VERSION "dbc-export 1 2025.20.8"

NS_ :

BS_:

BU_: ADSP APB APP APS APSB BB BMS CC CMP CMPD CP DAS DI DIF DIR DPB EPAS3P EPAS3S EPASTP EPASTS EPBL EPBR ESP GTW HVP IBST ICR IDB OCS1P ODIN PARK PCS PLG PM PMF PMR PTC RADC RCM RCM2 RCU SCCM SDCR TAS TCU TPMS TRCM UDS UI UIS UMC USM VC VCFRONT VCLEFT VCRIGHT VCSEC

BO_ 294 UI_alertMatrix4: 8 UI
 SG_ UI_a193_TcuRNandFwVersionMismatc : 0|1@1+ (1,0) [0|1] "" Vector__XXX
 SG_ UI_a194_AudioweaverRestarted : 1|1@1+ (1,0) [0|1] "" Vector__XXX
 SG_ UI_a195_gtwMfdUdpApiFired : 2|1@1+ (1,0) [0|1] "" Vector__XXX
 SG_ UI_a196_AMDI2C3BusInoperable : 3|1@1+ (1,0) [0|1] "" Vector__XXX
 SG_ UI_a197_AMDI2C1BusInoperable : 4|1@1+ (1,0) [0|1] "" Vector__XXX
 SG_ UI_a198_IncompatibleBTUSBHubHard : 5|1@1+ (1,0) [0|1] "" Vector__XXX
 SG_ UI_a199_HighAPedalDetectedAtColl : 6|1@1+ (1,0) [0|1] "" Vector__XXX
 SG_ UI_a200_UIFirmwareVersionMismatc : 7|1@1+ (1,0) [0|1] "" Vector__XXX
 SG_ UI_a201_rearDisplayDisconnected : 8|1@1+ (1,0) [0|1] "" Vector__XXX
 SG_ UI_a202_sysMemoryIncorrect : 9|1@1+ (1,0) [0|1] "" Vector__XXX
 SG_ UI_a204_ModemSleepFailure : 11|1@1+ (1,0) [0|1] "" Vector__XXX
 SG_ UI_a205_ModemSleepSignalMismatch : 12|1@1+ (1,0) [0|1] "" Vector__XXX
 SG_ UI_a206_ModemMIAAfterWake : 13|1@1+ (1,0) [0|1] "" Vector__XXX
 SG_ UI_a207_mqttClientDisconnected : 14|1@1+ (1,0) [0|1] "" Vector__XXX
 SG_ UI_a208_mqttDisconnectReason : 15|1@1+ (1,0) [0|1] "" Vector__XXX
 SG_ UI_a209_dataCallDisconnected : 16|1@1+ (1,0) [0|1] "" Vector__XXX
 SG_ UI_a210_CellularCSRegFail : 17|1@1+ (1,0) [0|1] "" Vector__XXX
 SG_ UI_a211_AEBSDisabled : 18|1@1+ (1,0) [0|1] "" Vector__XXX
 SG_ UI_a212_AEBSFaulted : 19|1@1+ (1,0) [0|1] "" Vector__XXX
 SG_ UI_a213_ISADisabled : 20|1@1+ (1,0) [0|1] "" Vector__XXX
 SG_ UI_a214_pmHelperFailure : 21|1@1+ (1,0) [0|1] "" Vector__XXX
 SG_ UI_a215_compositorStallDetected : 22|1@1+ (1,0) [0|1] "" Vector__XXX
 SG_ UI_a216_AudioA2bCircuitProblem : 23|1@1+ (1,0) [0|1] "" Vector__XXX
 SG_ UI_a217_CgroupMemoryPressure : 24|1@1+ (1,0) [0|1] "" Vector__XXX
 SG_ UI_a218_AudiodNoAudioDevices : 25|1@1+ (1,0) [0|1] "" Vector__XXX
 SG_ UI_a219_CompositorWatchdog : 26|1@1+ (1,0) [0|1] "" Vector__XXX
 SG_ UI_a220_MediaBrowseError : 27|1@1+ (1,0) [0|1] "" Vector__XXX
 SG_ UI_a221_NavigationServiceError : 28|1@1+ (1,0) [0|1] "" Vector__XXX
 SG_ UI_a222_QtCarRestart : 29|1@1+ (1,0) [0|1] "" Vector__XXX
 SG_ UI_a223_databaseError : 30|1@1+ (1,0) [0|1] "" Vector__XXX
 SG_ UI_a224_centerDisplayDisconnecte : 31|1@1+ (1,0) [0|1] "" Vector__XXX
 SG_ UI_a225_clusterDisplayDisconnect : 32|1@1+ (1,0) [0|1] "" Vector__XXX
 SG_ UI_a226_largePhoneContactSync : 33|1@1+ (1,0) [0|1] "" Vector__XXX
 SG_ UI_a228_pipewireXrunBurst : 35|1@1+ (1,0) [0|1] "" Vector__XXX
 SG_ UI_a229_SerDesError : 36|1@1+ (1,0) [0|1] "" Vector__XXX
 SG_ UI_a230_ModemSimCardMismatch : 37|1@1+ (1,0) [0|1] "" Vector__XXX
 SG_ UI_a231_SleepCancelled : 38|1@1+ (1,0) [0|1] "" Vector__XXX
 SG_ UI_a232_processExitError : 39|1@1+ (1,0) [0|1] "" Vector__XXX
 SG_ UI_a233_ModemRFFailure : 40|1@1+ (1,0) [0|1] "" Vector__XXX
 SG_ UI_a234_AMDI2C0Timeout : 41|1@1+ (1,0) [0|1] "" Vector__XXX
 SG_ UI_a235_AMDI2C1Timeout : 42|1@1+ (1,0) [0|1] "" Vector__XXX
 SG_ UI_a236_ModemOnResetState : 43|1@1+ (1,0) [0|1] "" Vector__XXX
 SG_ UI_a237_ClipUploadActive : 44|1@1+ (1,0) [0|1] "" Vector__XXX
 SG_ UI_a238_ModemConfigMismatch : 45|1@1+ (1,0) [0|1] "" Vector__XXX
 SG_ UI_a239_stateOfVehiclesFunctions : 46|1@1+ (1,0) [0|1] "" Vector__XXX
 SG_ UI_a240_ethError : 47|1@1+ (1,0) [0|1] "" Vector__XXX
 SG_ UI_a241_AxCPError : 48|1@1+ (1,0) [0|1] "" Vector__XXX

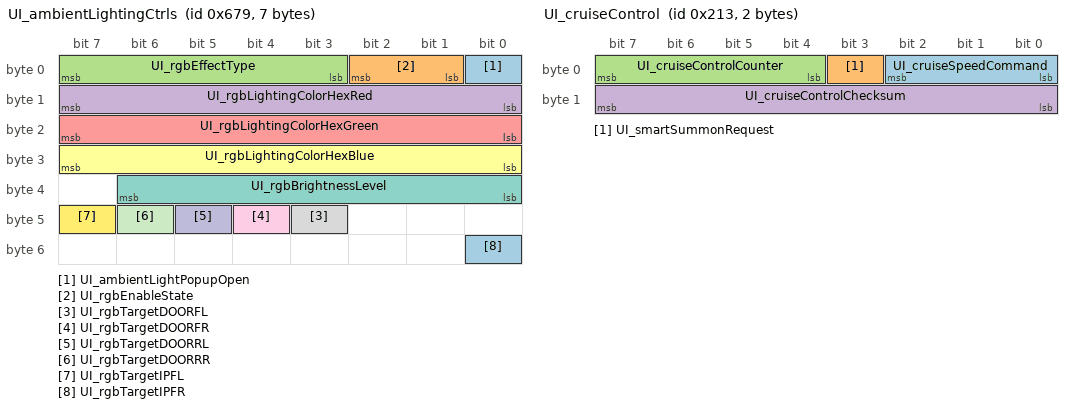
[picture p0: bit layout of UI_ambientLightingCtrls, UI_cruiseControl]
BO_ 1657 UI_ambientLightingCtrls: 7 UI
 SG_ UI_ambientLightPopupOpen : 0|1@1+ (1,0) [0|1] "" Vector__XXX
 SG_ UI_rgbEnableState : 1|2@1+ (1,0) [0|3] "" Vector__XXX
 SG_ UI_rgbEffectType : 3|5@1+ (1,0) [0|31] "" Vector__XXX
 SG_ UI_rgbLightingColorHexRed : 8|8@1+ (1,0) [0|255] "" Vector__XXX
 SG_ UI_rgbLightingColorHexGreen : 16|8@1+ (1,0) [0|255] "" Vector__XXX
 SG_ UI_rgbLightingColorHexBlue : 24|8@1+ (1,0) [0|255] "" Vector__XXX
 SG_ UI_rgbBrightnessLevel : 32|7@1+ (1,0) [0|100] "%" Vector__XXX
 SG_ UI_rgbTargetDOORFL : 43|1@1+ (1,0) [0|1] "" Vector__XXX
 SG_ UI_rgbTargetDOORFR : 44|1@1+ (1,0) [0|1] "" Vector__XXX
 SG_ UI_rgbTargetDOORRL : 45|1@1+ (1,0) [0|1] "" Vector__XXX
 SG_ UI_rgbTargetDOORRR : 46|1@1+ (1,0) [0|1] "" Vector__XXX
 SG_ UI_rgbTargetIPFL : 47|1@1+ (1,0) [0|1] "" Vector__XXX
 SG_ UI_rgbTargetIPFR : 48|1@1+ (1,0) [0|1] "" Vector__XXX

BO_ 1021 UI_autopilotControl: 8 UI
 SG_ UI_autopilotControlIndex M : 0|3@1+ (1,0) [0|7] "" Vector__XXX
 SG_ UI_hovEnabled m0 : 3|1@1+ (1,0) [0|1] "" Vector__XXX
 SG_ UI_donDisableAutoWiperDuration m0 : 4|3@1+ (1,0) [0|7] "" Vector__XXX
 SG_ UI_donDisableOnAutoWiperSpeed m0 : 7|4@1+ (1,0) [0|15] "" Vector__XXX
 SG_ UI_blindspotMinSpeed m0 : 11|4@1+ (1,0) [0|15] "" Vector__XXX
 SG_ UI_blindspotDistance m0 : 15|3@1+ (1,0) [0|7] "" Vector__XXX
 SG_ UI_blindspotTTC m0 : 18|3@1+ (1,0) [0|7] "" Vector__XXX
 SG_ UI_donStopEndOfRampBuffer m0 : 21|3@1+ (1,0) [0|7] "" Vector__XXX
 SG_ UI_donDisableCutin m0 : 24|1@1+ (1,0) [0|1] "" Vector__XXX
 SG_ UI_smartSetSpeedOffset m0 : 25|6@1+ (1,-30) [-30|33] "%" Vector__XXX
 SG_ UI_smartSetSpeedOffsetType m0 : 31|1@1+ (1,0) [0|1] "" Vector__XXX
 SG_ UI_autopilotMonarchBackup m0 : 32|1@1+ (1,0) [0|1] "" Vector__XXX
 SG_ UI_fsdVisualizationEnabled m0 : 37|1@1+ (1,0) [0|1] "" Vector__XXX
 SG_ UI_fsdStopsControlEnabled m0 : 38|1@1+ (1,0) [0|1] "" Vector__XXX
 SG_ UI_fsdContinueOnGreenWithCIPV m0 : 39|1@1+ (1,0) [0|1] "" Vector__XXX
 SG_ UI_smartSetSpeed m0 : 40|1@1+ (1,0) [0|1] "" Vector__XXX
 SG_ UI_automaticSetSpeedOffset m0 : 41|1@1+ (1,0) [0|1] "" Vector__XXX
 SG_ UI_apply2021_1958_ISA m0 : 42|1@1+ (1,0) [0|1] "" Vector__XXX
 SG_ UI_apply2021_646_ELKS m0 : 43|1@1+ (1,0) [0|1] "" Vector__XXX
 SG_ UI_apply2021_1341_DDAW m0 : 44|1@1+ (1,0) [0|1] "" Vector__XXX
 SG_ UI_homelinkNearby m0 : 45|1@1+ (1,0) [0|1] "" Vector__XXX
 SG_ UI_enableFullSelfDriving m0 : 46|1@1+ (1,0) [0|1] "" Vector__XXX
 SG_ UI_hasFullSelfDriving m0 : 47|1@1+ (1,0) [0|1] "" Vector__XXX
 SG_ UI_autosteerActivation m0 : 48|1@1+ (1,0) [0|1] "" Vector__XXX
 SG_ UI_autopilotDrivingProfile m0 : 49|2@1+ (1,0) [0|3] "" Vector__XXX
 SG_ UI_fsdBetaRequest m0 : 51|1@1+ (1,0) [0|1] "" Vector__XXX
 SG_ UI_fullSelfDrivingSuspended m0 : 52|1@1+ (1,0) [0|1] "" Vector__XXX
 SG_ UI_disableOptionalLaneChanges m0 : 53|1@1+ (1,0) [0|1] "" Vector__XXX
 SG_ UI_applyR152_AEBS m0 : 59|1@1+ (1,0) [0|1] "" Vector__XXX
 SG_ UI_autopilotControlMux0Valid m0 : 63|1@1+ (1,0) [0|1] "" Vector__XXX
 SG_ UI_selectableCameraRequest m1 : 8|4@1+ (1,0) [0|14] "" Vector__XXX
 SG_ UI_overrideSleepWithSuspend m1 : 16|1@1+ (1,0) [0|1] "" Vector__XXX
 SG_ UI_driverMonitorConfirmation m1 : 17|1@1+ (1,0) [0|1] "" Vector__XXX
 SG_ UI_parkAssistUseVision m1 : 18|1@1+ (1,0) [0|1] "" Vector__XXX
 SG_ UI_applyEceR79 m1 : 19|1@1+ (1,0) [0|1] "" Vector__XXX
 SG_ UI_enableMapStops m1 : 20|1@1+ (1,0) [0|1] "" Vector__XXX
 SG_ UI_disableMain m1 : 23|1@1+ (1,0) [0|1] "" Vector__XXX
 SG_ UI_disableNarrow m1 : 24|1@1+ (1,0) [0|1] "" Vector__XXX
 SG_ UI_disableFisheye m1 : 25|1@1+ (1,0) [0|1] "" Vector__XXX
 SG_ UI_disableLeftPillar m1 : 26|1@1+ (1,0) [0|1] "" Vector__XXX
 SG_ UI_disableRightPillar m1 : 27|1@1+ (1,0) [0|1] "" Vector__XXX
 SG_ UI_disableLeftRepeater m1 : 28|1@1+ (1,0) [0|1] "" Vector__XXX
 SG_ UI_disableRightRepeater m1 : 29|1@1+ (1,0) [0|1] "" Vector__XXX
 SG_ UI_disableBackup m1 : 30|1@1+ (1,0) [0|1] "" Vector__XXX
 SG_ UI_disableRadar m1 : 31|1@1+ (1,0) [0|1] "" Vector__XXX
 SG_ UI_noStalkConfirmAlertHaptic m1 : 32|1@1+ (1,0) [0|1] "" Vector__XXX
 SG_ UI_regulatoryLKA m1 : 33|1@1+ (1,0) [0|1] "" Vector__XXX
 SG_ UI_regulatoryLaneAssistLevel m1 : 34|1@1+ (1,0) [0|1] "" Vector__XXX
 SG_ UI_ulcSnooze m1 : 36|1@1+ (1,0) [0|1] "" Vector__XXX
 SG_ UI_noStalkConfirmAlertChime m1 : 37|1@1+ (1,0) [0|1] "" Vector__XXX
 SG_ UI_factorySummonEnable m1 : 39|1@1+ (1,0) [0|1] "" Vector__XXX
 SG_ UI_apmv3Branch m1 : 40|3@1+ (1,0) [0|7] "" Vector__XXX
 SG_ UI_enableCabinCamera m1 : 43|1@1+ (1,0) [0|1] "" Vector__XXX
 SG_ UI_enableAutopilotStopWarning m1 : 44|1@1+ (1,0) [0|1] "" Vector__XXX
 SG_ UI_showLaneGraph m1 : 45|1@1+ (1,0) [0|1] "" Vector__XXX
 SG_ UI_showTrackLabels m1 : 46|1@1+ (1,0) [0|1] "" Vector__XXX
 SG_ UI_hardCoreSummon m1 : 47|1@1+ (1,0) [0|1] "" Vector__XXX
 SG_ UI_enableCabinCameraTelemetry m1 : 48|1@1+ (1,0) [0|1] "" Vector__XXX
 SG_ UI_enableVisionSpeedControl m1 : 49|1@1+ (1,0) [0|1] "" Vector__XXX
 SG_ UI_autopilotTelemetryInChina m1 : 50|1@1+ (1,0) [0|1] "" Vector__XXX
 SG_ UI_enableTeslaAutopark m1 : 51|1@1+ (1,0) [0|1] "" Vector__XXX
 SG_ UI_autoTurnSignalMode m1 : 52|1@1+ (1,0) [0|1] "" Vector__XXX
 SG_ UI_enableCautionLightControl m1 : 54|1@1+ (1,0) [0|1] "" Vector__XXX
 SG_ UI_applyEceR79SmartSummonOnly m1 : 55|1@1+ (1,0) [0|1] "" Vector__XXX
 SG_ UI_autopilotMonarchEnabled m1 : 56|1@1+ (1,0) [0|1] "" Vector__XXX
 SG_ UI_autopilotEphemerisEnabled m1 : 57|1@1+ (1,0) [0|1] "" Vector__XXX
 SG_ UI_enableCabinAudioRecording m1 : 59|1@1+ (1,0) [0|1] "" Vector__XXX
 SG_ UI_autopilotControlMux1Valid m1 : 63|1@1+ (1,0) [0|1] "" Vector__XXX
 SG_ UI_enableApproachingEmergencyVeh m2 : 5|1@1+ (1,0) [0|1] "" Vector__XXX
 SG_ UI_enableStartFsdFromParkBrakeCo m2 : 6|1@1+ (1,0) [0|1] "" Vector__XXX
 SG_ UI_enableStartFsdFromPark m2 : 7|1@1+ (1,0) [0|1] "" Vector__XXX
 SG_ UI_fsdMaxSpeedOffsetPercentage m2 : 8|6@1+ (1,0) [0|63] "%" Vector__XXX
 SG_ UI_coldStartMonarchInFactory m2 : 16|1@1+ (1,0) [0|1] "" Vector__XXX
 SG_ UI_autopilotControlMux2Valid m2 : 63|1@1+ (1,0) [0|1] "" Vector__XXX

BO_ 819 UI_chargeRequest: 5 UI
 SG_ UI_openChargePortDoorRequest : 0|1@1+ (1,0) [0|1] "" Vector__XXX
 SG_ UI_closeChargePortDoorRequest : 1|1@1+ (1,0) [0|1] "" Vector__XXX
 SG_ UI_chargeEnableRequest : 2|1@1+ (1,0) [0|1] "" Vector__XXX
 SG_ UI_brickVLoggingRequest : 3|1@1+ (1,0) [0|1] "" Vector__XXX
 SG_ UI_brickBalancingDisabled : 4|1@1+ (1,0) [0|1] "" Vector__XXX
 SG_ UI_dSocAlertThreshold : 5|3@1+ (0.5,-4) [-4|-0.5] "%" Vector__XXX
 SG_ UI_acChargeCurrentLimit : 8|7@1+ (1,0) [0|126] "A" Vector__XXX
 SG_ UI_dSocAlertEnable : 15|1@1+ (1,0) [0|1] "" Vector__XXX
 SG_ UI_chargeTerminationPct : 16|10@1+ (0.1,0) [5|100] "%" Vector__XXX
 SG_ UI_chargeFeature1 : 26|1@1+ (1,0) [0|1] "" Vector__XXX
 SG_ UI_chargeFeature2 : 27|1@1+ (1,0) [0|1] "" Vector__XXX
 SG_ UI_chargeFeature3 : 28|1@1+ (1,0) [0|1] "" Vector__XXX
 SG_ UI_scheduledDepartureEnabled : 29|1@1+ (1,0) [0|1] "" Vector__XXX
 SG_ UI_chargePortLatchRequest : 30|2@1+ (1,0) [0|3] "" Vector__XXX
 SG_ UI_socSnapshotExpirationTime : 32|4@1+ (2,2) [2|32] "weeks" Vector__XXX
 SG_ UI_cpInletHeaterRequest : 36|2@1+ (1,0) [0|3] "" Vector__XXX
 SG_ UI_chargePowerSampleRequest : 38|1@1+ (1,0) [0|1] "" Vector__XXX
 SG_ UI_enableIso15118 : 39|1@1+ (1,0) [0|1] "" Vector__XXX

BO_ 531 UI_cruiseControl: 2 UI
 SG_ UI_cruiseSpeedCommand : 0|3@1+ (1,0) [0|7] "" Vector__XXX
 SG_ UI_smartSummonRequest : 3|1@1+ (1,0) [0|1] "" Vector__XXX
 SG_ UI_cruiseControlCounter : 4|4@1+ (1,0) [0|15] "" Vector__XXX
 SG_ UI_cruiseControlChecksum : 8|8@1+ (1,0) [0|255] "" Vector__XXX

BO_ 645 UI_driverProfileRecall: 8 UI
 SG_ UI_driverProfileRecallIndex M : 0|3@1+ (1,0) [1|7] "" Vector__XXX
 SG_ UI_driverProfileRecallStop : 3|1@1+ (1,0) [0|1] "" Vector__XXX
 SG_ UI_frontSeatRecallActive m1 : 4|1@1+ (1,0) [0|1] "" Vector__XXX
 SG_ UI_frontSeatTrackPos m1 : 5|10@1- (4,0) [-2048|2044] "mm" Vector__XXX
 SG_ UI_frontSeatBackPos m1 : 16|12@1- (0.1,0) [-204.8|204.7] "deg" Vector__XXX
 SG_ UI_frontSeatLiftPos m1 : 32|10@1- (4,0) [-2048|2044] "mm" Vector__XXX
 SG_ UI_frontSeatTiltPos m1 : 48|12@1- (0.1,0) [-204.8|204.7] "deg" Vector__XXX
 SG_ UI_columnAndLumbarRecallActive m2 : 4|1@1+ (1,0) [0|1] "" Vector__XXX
 SG_ UI_steeringColumnUpDownPos m2 : 8|8@1- (1,103) [-25|230] "mm" Vector__XXX
 SG_ UI_lumbarAPressureHpa m2 : 16|16@1+ (1,0) [0|65535] "" Vector__XXX
 SG_ UI_lumbarBPressureHpa m2 : 32|16@1+ (1,0) [0|65535] "" Vector__XXX
 SG_ UI_steeringColumnInOutPos m2 : 48|8@1- (1,103) [-25|230] "mm" Vector__XXX
 SG_ UI_leftMirrorTiltXPosition m3 : 8|8@1+ (0.02,0) [0|5] "V" Vector__XXX
 SG_ UI_leftMirrorTiltYPosition m3 : 16|8@1+ (0.02,0) [0|5] "V" Vector__XXX
 SG_ UI_rightMirrorTiltXPosition m3 : 24|8@1+ (0.02,0) [0|5.1] "V" Vector__XXX
 SG_ UI_rightMirrorTiltYPosition m3 : 32|8@1+ (0.02,0) [0|5.1] "V" Vector__XXX
 SG_ UI_mirrorRecallActive m4 : 4|1@1+ (1,0) [0|1] "" Vector__XXX
 SG_ UI_customMirrorDipPositionsSet m4 : 5|1@1+ (1,0) [0|1] "" Vector__XXX
 SG_ UI_leftMirrorDipXPosition m4 : 8|8@1+ (0.02,0) [0|5] "V" Vector__XXX
 SG_ UI_leftMirrorDipYPosition m4 : 16|8@1+ (0.02,0) [0|5] "V" Vector__XXX
 SG_ UI_rightMirrorDipXPosition m4 : 24|8@1+ (0.02,0) [0|5.1] "V" Vector__XXX
 SG_ UI_rightMirrorDipYPosition m4 : 32|8@1+ (0.02,0) [0|5.1] "V" Vector__XXX
 SG_ UI_modifyMirrorDipRequest m4 : 40|2@1+ (1,0) [0|3] "" Vector__XXX

BO_ 1279 UI_energyConsumptionInfo: 8 UI
 SG_ UI_energyConsumptionInfoIndex M : 0|5@1+ (1,0) [0|31] "" Vector__XXX
 SG_ UI_energyLossTotal_epa m0 : 16|16@1- (1,0) [-32768|32767] "Wh" Vector__XXX
 SG_ UI_energyLossDriving_epa m0 : 32|16@1- (1,0) [-32768|32767] "Wh" Vector__XXX
 SG_ UI_energyLossClimate_epa m0 : 48|16@1- (1,0) [-32768|32767] "Wh" Vector__XXX
 SG_ UI_energyLossBattCond_epa m1 : 16|16@1- (1,0) [-32768|32767] "Wh" Vector__XXX
 SG_ UI_energyLossElevation_epa m1 : 32|16@1- (1,0) [-32768|32767] "Wh" Vector__XXX
 SG_ UI_energyLossAcc_epa m1 : 48|16@1- (1,0) [-32768|32767] "Wh" Vector__XXX
 SG_ UI_energyLossTotalSinceCharge_ep m2 : 16|16@1- (1,0) [-32768|32767] "Wh" Vector__XXX
 SG_ UI_energyLossDrivingSinceCharge_ m2 : 32|16@1- (1,0) [-32768|32767] "Wh" Vector__XXX
 SG_ UI_energyLossClimateSinceCharge_ m2 : 48|16@1- (1,0) [-32768|32767] "Wh" Vector__XXX
 SG_ UI_energyLossBattCondSinceCharge m3 : 16|16@1- (1,0) [-32768|32767] "Wh" Vector__XXX
 SG_ UI_energyLossElevationSinceCharg m3 : 32|16@1- (1,0) [-32768|32767] "Wh" Vector__XXX
 SG_ UI_energyLossAccSinceCharge_epa m3 : 48|16@1- (1,0) [-32768|32767] "Wh" Vector__XXX
 SG_ UI_energyLossTotalSinceTripStart m4 : 16|16@1- (1,0) [-32768|32767] "Wh" Vector__XXX
 SG_ UI_energyLossDrivingSinceTripSta m4 : 32|16@1- (1,0) [-32768|32767] "Wh" Vector__XXX
 SG_ UI_energyLossClimateSinceTripSta m4 : 48|16@1- (1,0) [-32768|32767] "Wh" Vector__XXX
 SG_ UI_energyLossBattCondSinceTripSt m5 : 16|16@1- (1,0) [-32768|32767] "Wh" Vector__XXX
 SG_ UI_energyLossElevationSinceTripS m5 : 32|16@1- (1,0) [-32768|32767] "Wh" Vector__XXX
 SG_ UI_energyLossAccSinceTripStart m5 : 48|16@1- (1,0) [-32768|32767] "Wh" Vector__XXX
 SG_ UI_energyDeltaTotal_epa m6 : 16|16@1- (1,0) [-32768|32767] "Wh" Vector__XXX
 SG_ UI_energyDeltaDriving_epa m6 : 32|16@1- (1,0) [-32768|32767] "Wh" Vector__XXX
 SG_ UI_energyDeltaClimate_epa m6 : 48|16@1- (1,0) [-32768|32767] "Wh" Vector__XXX
 SG_ UI_energyDeltaBattCond_epa m7 : 16|16@1- (1,0) [-32768|32767] "Wh" Vector__XXX
 SG_ UI_energyDeltaElevation_epa m7 : 32|16@1- (1,0) [-32768|32767] "Wh" Vector__XXX
 SG_ UI_energyDeltaAcc_epa m7 : 48|16@1- (1,0) [-32768|32767] "Wh" Vector__XXX
 SG_ UI_uiDeltaOffsetTotal_epa m8 : 16|16@1- (1,0) [-32768|32767] "Wh" Vector__XXX
 SG_ UI_uiDeltaOffsetDriving_epa m8 : 32|16@1- (1,0) [-32768|32767] "Wh" Vector__XXX
 SG_ UI_uiDeltaOffsetClimate_epa m8 : 48|16@1- (1,0) [-32768|32767] "Wh" Vector__XXX
 SG_ UI_uiDeltaOffsetBattCond_epa m9 : 16|16@1- (1,0) [-32768|32767] "Wh" Vector__XXX
 SG_ UI_uiDeltaOffsetElevation_epa m9 : 32|16@1- (1,0) [-32768|32767] "Wh" Vector__XXX
 SG_ UI_uiDeltaOffsetAcc_epa m9 : 48|16@1- (1,0) [-32768|32767] "Wh" Vector__XXX
 SG_ UI_rawToUiEnergyRatio_epa m10 : 8|8@1+ (0.01,0) [0|2.55] "-" Vector__XXX
 SG_ UI_driveDistance_epa m10 : 16|16@1+ (0.01,0) [0|655.35] "miles" Vector__XXX
 SG_ UI_energyDeltaTotalSinceCharge_e m11 : 16|16@1- (1,0) [-32768|32767] "Wh" Vector__XXX
 SG_ UI_energyDeltaDrivingSinceCharge m11 : 32|16@1- (1,0) [-32768|32767] "Wh" Vector__XXX
 SG_ UI_energyDeltaClimateSinceCharge m11 : 48|16@1- (1,0) [-32768|32767] "Wh" Vector__XXX
 SG_ UI_energyDeltaBattCondSinceCharg m12 : 16|16@1- (1,0) [-32768|32767] "Wh" Vector__XXX
 SG_ UI_energyDeltaElevationSinceChar m12 : 32|16@1- (1,0) [-32768|32767] "Wh" Vector__XXX
 SG_ UI_energyDeltaAccSinceCharge_epa m12 : 48|16@1- (1,0) [-32768|32767] "Wh" Vector__XXX
 SG_ UI_uiDeltaOffsetTotalSinceCharge m13 : 16|16@1- (1,0) [-32768|32767] "Wh" Vector__XXX
 SG_ UI_uiDeltaOffsetDrivingSinceChar m13 : 32|16@1- (1,0) [-32768|32767] "Wh" Vector__XXX
 SG_ UI_uiDeltaOffsetClimateSinceChar m13 : 48|16@1- (1,0) [-32768|32767] "Wh" Vector__XXX
 SG_ UI_uiDeltaOffsetBattCondSinceCha m14 : 16|16@1- (1,0) [-32768|32767] "Wh" Vector__XXX
 SG_ UI_uiDeltaOffsetElevationSinceCh m14 : 32|16@1- (1,0) [-32768|32767] "Wh" Vector__XXX
 SG_ UI_uiDeltaOffsetAccSinceCharge_e m14 : 48|16@1- (1,0) [-32768|32767] "Wh" Vector__XXX
 SG_ UI_rawToUiEnergyRatioSinceCharge m15 : 8|8@1+ (0.01,0) [0|2.55] "-" Vector__XXX
 SG_ UI_driveDistanceSinceCharge_epa m15 : 16|16@1+ (0.01,0) [0|655.35] "miles" Vector__XXX
 SG_ UI_energyDeltaTotalSinceTripStar m16 : 16|16@1- (1,0) [-32768|32767] "Wh" Vector__XXX
 SG_ UI_energyDeltaDrivingSinceTripSt m16 : 32|16@1- (1,0) [-32768|32767] "Wh" Vector__XXX
 SG_ UI_energyDeltaClimateSinceTripSt m16 : 48|16@1- (1,0) [-32768|32767] "Wh" Vector__XXX
 SG_ UI_energyDeltaBattCondSinceTripS m17 : 16|16@1- (1,0) [-32768|32767] "Wh" Vector__XXX
 SG_ UI_energyDeltaElevationSinceTrip m17 : 32|16@1- (1,0) [-32768|32767] "Wh" Vector__XXX
 SG_ UI_energyDeltaAccSinceTripStart m17 : 48|16@1- (1,0) [-32768|32767] "Wh" Vector__XXX
 SG_ UI_uiDeltaOffsetTotalSinceTripSt m18 : 16|16@1- (1,0) [-32768|32767] "Wh" Vector__XXX
 SG_ UI_uiDeltaOffsetDrivingSinceTrip m18 : 32|16@1- (1,0) [-32768|32767] "Wh" Vector__XXX
 SG_ UI_uiDeltaOffsetClimateSinceTrip m18 : 48|16@1- (1,0) [-32768|32767] "Wh" Vector__XXX
 SG_ UI_uiDeltaOffsetBattCondSinceTri m19 : 16|16@1- (1,0) [-32768|32767] "Wh" Vector__XXX
 SG_ UI_uiDeltaOffsetElevationSinceTr m19 : 32|16@1- (1,0) [-32768|32767] "Wh" Vector__XXX
 SG_ UI_uiDeltaOffsetAccSinceTripStar m19 : 48|16@1- (1,0) [-32768|32767] "Wh" Vector__XXX
 SG_ UI_rawToUiEnergyRatioSinceTripSt m20 : 8|8@1+ (0.01,0) [0|2.55] "-" Vector__XXX
 SG_ UI_driveDistanceSinceTripStart m20 : 16|16@1+ (0.01,0) [0|655.35] "miles" Vector__XXX
 SG_ UI_voyagerEnabled m21 : 5|1@1+ (1,0) [0|1] "" Vector__XXX
 SG_ UI_trailerMass m21 : 16|16@1+ (1,0) [0|65535] "kg" Vector__XXX

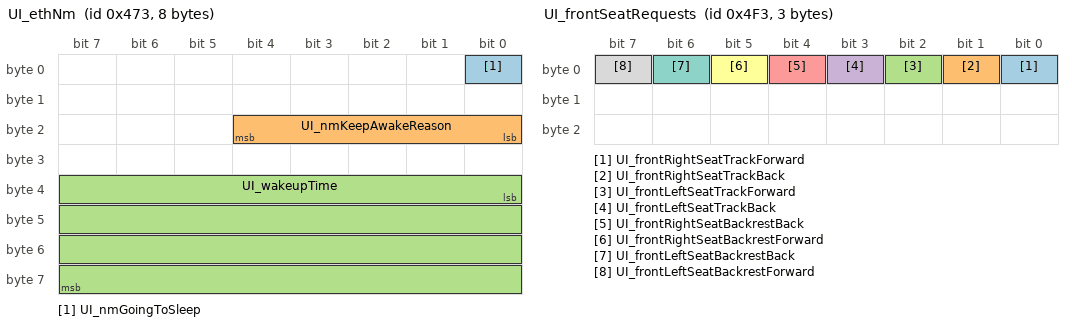
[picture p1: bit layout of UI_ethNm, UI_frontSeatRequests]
BO_ 1139 UI_ethNm: 8 UI
 SG_ UI_nmGoingToSleep : 0|1@1+ (1,0) [0|1] "" Vector__XXX
 SG_ UI_nmKeepAwakeReason : 16|5@1+ (1,0) [1|31] "" Vector__XXX
 SG_ UI_wakeupTime : 32|32@1+ (1,0) [0|4294967295] "" Vector__XXX

BO_ 1267 UI_frontSeatRequests: 3 UI
 SG_ UI_frontRightSeatTrackForward : 0|1@1+ (1,0) [0|1] "" Vector__XXX
 SG_ UI_frontRightSeatTrackBack : 1|1@1+ (1,0) [0|1] "" Vector__XXX
 SG_ UI_frontLeftSeatTrackForward : 2|1@1+ (1,0) [0|1] "" Vector__XXX
 SG_ UI_frontLeftSeatTrackBack : 3|1@1+ (1,0) [0|1] "" Vector__XXX
 SG_ UI_frontRightSeatBackrestBack : 4|1@1+ (1,0) [0|1] "" Vector__XXX
 SG_ UI_frontRightSeatBackrestForward : 5|1@1+ (1,0) [0|1] "" Vector__XXX
 SG_ UI_frontLeftSeatBackrestBack : 6|1@1+ (1,0) [0|1] "" Vector__XXX
 SG_ UI_frontLeftSeatBackrestForward : 7|1@1+ (1,0) [0|1] "" Vector__XXX

BO_ 955 UI_power: 2 UI
 SG_ UI_powerExpected : 0|8@1+ (1,0) [0|255] "kW" Vector__XXX
 SG_ UI_powerIdeal : 8|8@1+ (1,0) [0|255] "kW" Vector__XXX

BO_ 820 UI_powertrainControl: 8 UI
 SG_ UI_systemPowerLimit : 0|5@1+ (20,20) [20|620] "kW" Vector__XXX
 SG_ UI_pedalMap : 5|2@1+ (1,0) [0|3] "" Vector__XXX
 SG_ UI_enableRegenBackfill : 7|1@1+ (1,0) [0|1] "" Vector__XXX
 SG_ UI_systemTorqueLimit : 8|6@1+ (150,1000) [1000|10300] "Nm" Vector__XXX
 SG_ UI_closureConfirmed : 14|2@1+ (1,0) [0|3] "" Vector__XXX
 SG_ UI_regenTorqueMax : 16|5@1+ (5,0) [0|100] "%" Vector__XXX
 SG_ UI_limitMode : 21|2@1+ (1,0) [0|3] "" Vector__XXX
 SG_ UI_factoryCustomerDrivingModeReq : 23|1@1+ (1,0) [0|1] "" Vector__XXX
 SG_ UI_motorOnMode : 24|2@1+ (1,0) [0|3] "" Vector__XXX
 SG_ UI_wasteMode : 26|2@1+ (1,0) [0|3] "" Vector__XXX
 SG_ UI_wasteModeRegenLimit : 28|2@1+ (1,0) [0|3] "" Vector__XXX
 SG_ UI_stoppingMode : 30|2@1+ (1,0) [0|3] "" Vector__XXX
 SG_ UI_DIAppSliderDebug : 32|2@1+ (1,0) [0|3] "" Vector__XXX
 SG_ UI_speedLimit : 34|12@1+ (0.1,0) [0|335] "kph" Vector__XXX
 SG_ UI_enableSmartShift : 46|2@1+ (1,0) [0|3] "" Vector__XXX
 SG_ UI_navVehParallelToRdCanContinue : 49|2@1+ (1,0) [1|3] "" Vector__XXX
 SG_ UI_powertrainControlCounter : 52|4@1+ (1,0) [0|15] "" Vector__XXX
 SG_ UI_powertrainControlChecksum : 56|8@1+ (1,0) [0|255] "" Vector__XXX

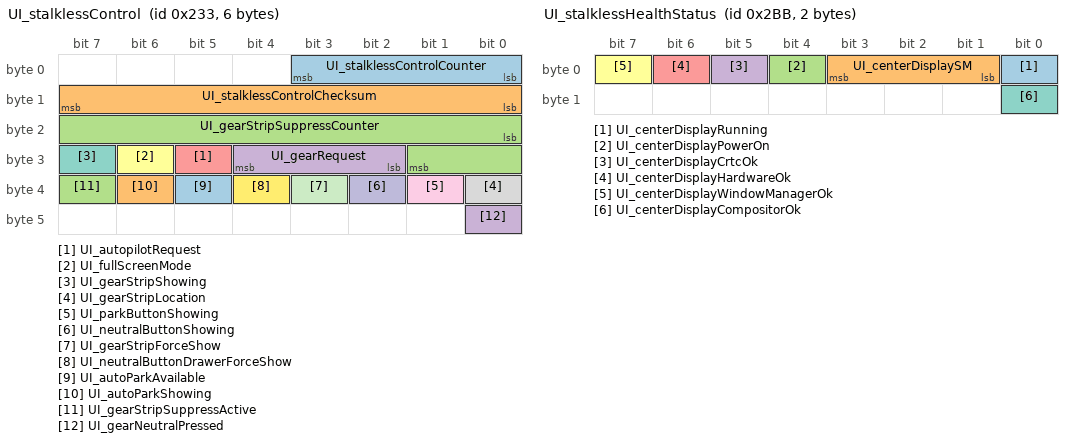
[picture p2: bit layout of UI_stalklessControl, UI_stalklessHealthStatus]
BO_ 563 UI_stalklessControl: 6 UI
 SG_ UI_stalklessControlCounter : 0|4@1+ (1,0) [0|15] "" Vector__XXX
 SG_ UI_stalklessControlChecksum : 8|8@1+ (1,0) [0|255] "" Vector__XXX
 SG_ UI_gearStripSuppressCounter : 16|10@1+ (1,0) [0|1023] "" Vector__XXX
 SG_ UI_gearRequest : 26|3@1+ (1,0) [1|7] "" Vector__XXX
 SG_ UI_autopilotRequest : 29|1@1+ (1,0) [0|1] "" Vector__XXX
 SG_ UI_fullScreenMode : 30|1@1+ (1,0) [0|1] "" Vector__XXX
 SG_ UI_gearStripShowing : 31|1@1+ (1,0) [0|1] "" Vector__XXX
 SG_ UI_gearStripLocation : 32|1@1+ (1,0) [0|1] "" Vector__XXX
 SG_ UI_parkButtonShowing : 33|1@1+ (1,0) [0|1] "" Vector__XXX
 SG_ UI_neutralButtonShowing : 34|1@1+ (1,0) [0|1] "" Vector__XXX
 SG_ UI_gearStripForceShow : 35|1@1+ (1,0) [0|1] "" Vector__XXX
 SG_ UI_neutralButtonDrawerForceShow : 36|1@1+ (1,0) [0|1] "" Vector__XXX
 SG_ UI_autoParkAvailable : 37|1@1+ (1,0) [0|1] "" Vector__XXX
 SG_ UI_autoParkShowing : 38|1@1+ (1,0) [0|1] "" Vector__XXX
 SG_ UI_gearStripSuppressActive : 39|1@1+ (1,0) [0|1] "" Vector__XXX
 SG_ UI_gearNeutralPressed : 40|1@1+ (1,0) [0|1] "" Vector__XXX

BO_ 699 UI_stalklessHealthStatus: 2 UI
 SG_ UI_centerDisplayRunning : 0|1@1+ (1,0) [0|1] "" Vector__XXX
 SG_ UI_centerDisplaySM : 1|3@1+ (1,0) [0|7] "" Vector__XXX
 SG_ UI_centerDisplayPowerOn : 4|1@1+ (1,0) [0|1] "" Vector__XXX
 SG_ UI_centerDisplayCrtcOk : 5|1@1+ (1,0) [0|1] "" Vector__XXX
 SG_ UI_centerDisplayHardwareOk : 6|1@1+ (1,0) [0|1] "" Vector__XXX
 SG_ UI_centerDisplayWindowManagerOk : 7|1@1+ (1,0) [0|1] "" Vector__XXX
 SG_ UI_centerDisplayCompositorOk : 8|1@1+ (1,0) [0|1] "" Vector__XXX

BO_ 991 UI_status2: 8 UI
 SG_ UI_mobileAppStepCount : 0|16@1+ (1,0) [0|65535] "" Vector__XXX
 SG_ UI_userRequestSnapshot : 16|1@1+ (1,0) [0|1] "" Vector__XXX
 SG_ UI_touchDetected : 17|1@1+ (1,0) [0|1] "" Vector__XXX
 SG_ UI_validDeviceForEUSummon : 18|1@1+ (1,0) [0|1] "" Vector__XXX
 SG_ UI_locatedAtHome : 19|1@1+ (1,0) [0|1] "" Vector__XXX
 SG_ UI_locatedAtWork : 20|1@1+ (1,0) [0|1] "" Vector__XXX
 SG_ UI_locatedAtFavorite : 21|1@1+ (1,0) [0|1] "" Vector__XXX
 SG_ UI_displayInDarkMode : 22|1@1+ (1,0) [0|1] "" Vector__XXX
 SG_ UI_userActivity : 23|1@1+ (1,0) [0|1] "" Vector__XXX
 SG_ UI_activeTouchPoints : 24|8@1+ (1,0) [0|255] "1" Vector__XXX
 SG_ UI_linkState : 32|2@1+ (1,0) [0|3] "" Vector__XXX
 SG_ UI_sentryModeState : 34|3@1+ (1,0) [0|7] "" Vector__XXX
 SG_ UI_autopilotSentryRequest : 37|1@1+ (1,0) [0|1] "" Vector__XXX
 SG_ UI_mobileAppConnected : 38|1@1+ (1,0) [0|1] "" Vector__XXX
 SG_ UI_autoshiftDRState : 40|3@1+ (1,0) [0|7] "" Vector__XXX
 SG_ UI_wifiBtModuleType : 43|3@1+ (1,0) [0|7] "" Vector__XXX
 SG_ UI_sohHealthStatus : 46|2@1+ (1,0) [0|3] "" Vector__XXX
 SG_ UI_selfParkState : 48|8@1+ (1,0) [0|254] "" Vector__XXX
 SG_ UI_summonDeviceIndex : 56|2@1+ (1,0) [0|3] "" Vector__XXX
 SG_ UI_sentryModeCameraDetection : 58|1@1+ (1,0) [0|1] "" Vector__XXX
 SG_ UI_wakeOnIPActive : 59|1@1+ (1,0) [0|1] "" Vector__XXX

BO_ 661 UI_systemMonitor: 8 UI
 SG_ UI_systemMonitorIndex M : 0|1@1+ (1,0) [0|1] "" Vector__XXX
 SG_ UI_SystemMemUsage m0 : 8|16@1+ (1,0) [0|65535] "MB" Vector__XXX
 SG_ UI_QtCarMemUsage m0 : 24|16@1+ (1,0) [0|65535] "MB" Vector__XXX
 SG_ UI_QtCarCPUUsage m0 : 40|7@1+ (1,0) [0|127] "%" Vector__XXX
 SG_ UI_emmcStatus m0 : 47|1@1+ (1,0) [0|1] "" Vector__XXX
 SG_ UI_SystemCPUUsage m0 : 48|7@1+ (1,0) [0|127] "%" Vector__XXX
 SG_ UI_HomeHealth m0 : 55|1@1+ (1,0) [0|1] "" Vector__XXX
 SG_ UI_VarHealth m0 : 56|1@1+ (1,0) [0|1] "" Vector__XXX
 SG_ UI_LogHealth m0 : 57|1@1+ (1,0) [0|1] "" Vector__XXX
 SG_ UI_TmpfsHealth m0 : 58|1@1+ (1,0) [0|1] "" Vector__XXX
 SG_ UI_emmcDataWritten m1 : 8|24@1+ (1,0) [0|16777215] "" Vector__XXX
 SG_ UI_emmcTotalErases m1 : 32|16@1+ (1,0) [0|65535] "" Vector__XXX

BO_ 952 UI_tpmsRCPsetting: 4 UI
 SG_ UI_setRCPFront : 16|8@1+ (0.025,0) [0|6.375] "bar" Vector__XXX
 SG_ UI_setRCPRear : 24|8@1+ (0.025,0) [0|6.375] "bar" Vector__XXX

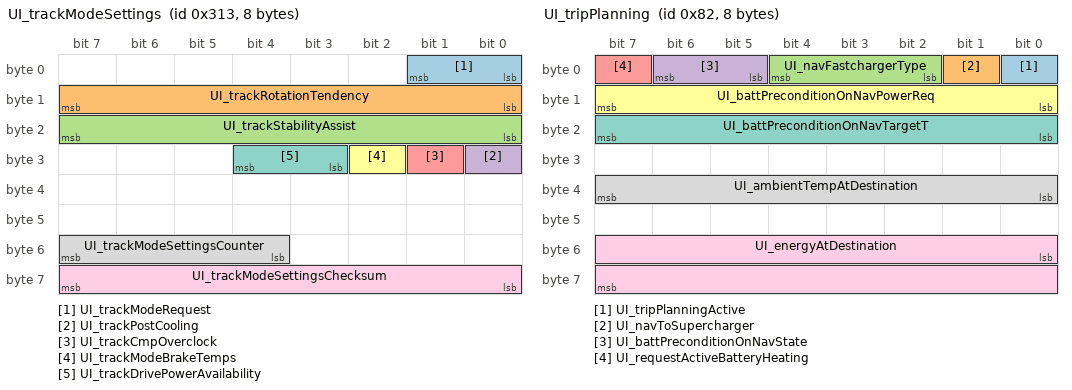
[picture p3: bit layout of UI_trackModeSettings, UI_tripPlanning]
BO_ 787 UI_trackModeSettings: 8 UI
 SG_ UI_trackModeRequest : 0|2@1+ (1,0) [0|3] "" Vector__XXX
 SG_ UI_trackRotationTendency : 8|8@1+ (0.5,0) [0|127.5] "%" Vector__XXX
 SG_ UI_trackStabilityAssist : 16|8@1+ (0.5,0) [0|127.5] "%" Vector__XXX
 SG_ UI_trackPostCooling : 24|1@1+ (1,0) [0|1] "" Vector__XXX
 SG_ UI_trackCmpOverclock : 25|1@1+ (1,0) [0|1] "" Vector__XXX
 SG_ UI_trackModeBrakeTemps : 26|1@1+ (1,0) [0|1] "" Vector__XXX
 SG_ UI_trackDrivePowerAvailability : 27|2@1+ (1,0) [0|3] "" Vector__XXX
 SG_ UI_trackModeSettingsCounter : 52|4@1+ (1,0) [0|15] "" Vector__XXX
 SG_ UI_trackModeSettingsChecksum : 56|8@1+ (1,0) [0|255] "" Vector__XXX

BO_ 130 UI_tripPlanning: 8 UI
 SG_ UI_tripPlanningActive : 0|1@1+ (1,0) [0|1] "" Vector__XXX
 SG_ UI_navToSupercharger : 1|1@1+ (1,0) [0|1] "" Vector__XXX
 SG_ UI_navFastchargerType : 2|3@1+ (1,0) [0|7] "" Vector__XXX
 SG_ UI_battPreconditionOnNavState : 5|2@1+ (1,0) [0|3] "" Vector__XXX
 SG_ UI_requestActiveBatteryHeating : 7|1@1+ (1,0) [0|1] "" Vector__XXX
 SG_ UI_battPreconditionOnNavPowerReq : 8|8@1- (125,0) [-16000|15750] "W" Vector__XXX
 SG_ UI_battPreconditionOnNavTargetT : 16|8@1+ (0.25,0) [0|63.5] "degC" Vector__XXX
 SG_ UI_ambientTempAtDestination : 32|8@1- (0.5,0) [-64|63.5] "degC" Vector__XXX
 SG_ UI_energyAtDestination : 48|16@1- (0.01,0) [-327.67|327.67] "kWh" Vector__XXX

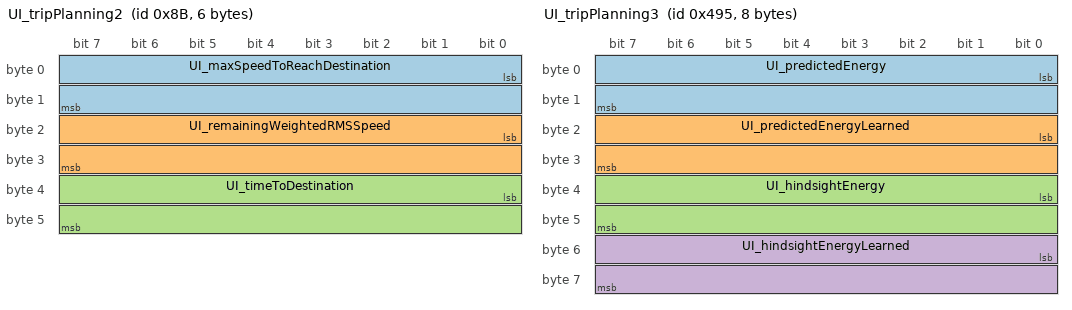
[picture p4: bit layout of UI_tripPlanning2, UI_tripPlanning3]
BO_ 139 UI_tripPlanning2: 6 UI
 SG_ UI_maxSpeedToReachDestination : 0|16@1+ (0.01,0) [0|655.34] "m/s" Vector__XXX
 SG_ UI_remainingWeightedRMSSpeed : 16|16@1+ (0.01,0) [0|655.34] "m/s" Vector__XXX
 SG_ UI_timeToDestination : 32|16@1+ (1,0) [0|65534] "s" Vector__XXX

BO_ 1173 UI_tripPlanning3: 8 UI
 SG_ UI_predictedEnergy : 0|16@1- (0.01,0) [-327.67|327.67] "kWh" Vector__XXX
 SG_ UI_predictedEnergyLearned : 16|16@1- (0.01,0) [-327.68|327.67] "kWh" Vector__XXX
 SG_ UI_hindsightEnergy : 32|16@1- (0.01,0) [-327.67|327.67] "kWh" Vector__XXX
 SG_ UI_hindsightEnergyLearned : 48|16@1- (0.01,0) [-327.68|327.67] "kWh" Vector__XXX

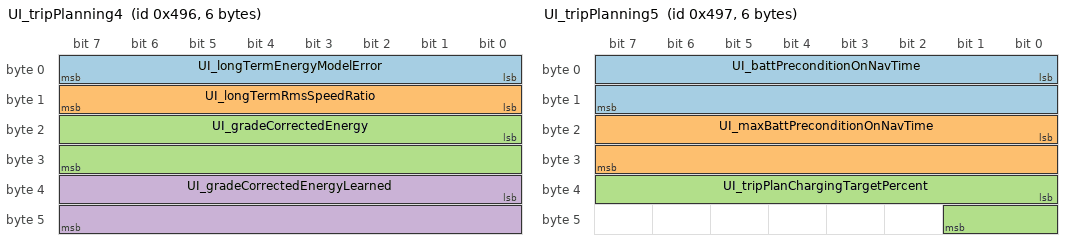
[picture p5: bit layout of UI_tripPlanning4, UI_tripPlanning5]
BO_ 1174 UI_tripPlanning4: 6 UI
 SG_ UI_longTermEnergyModelError : 0|8@1- (0.5,0) [-64|63.5] "whpm" Vector__XXX
 SG_ UI_longTermRmsSpeedRatio : 8|8@1+ (0.01,0) [0|2.54] "1" Vector__XXX
 SG_ UI_gradeCorrectedEnergy : 16|16@1- (0.01,0) [-327.68|327.67] "kWh" Vector__XXX
 SG_ UI_gradeCorrectedEnergyLearned : 32|16@1- (0.01,0) [-327.68|327.67] "kWh" Vector__XXX

BO_ 1175 UI_tripPlanning5: 6 UI
 SG_ UI_battPreconditionOnNavTime : 0|16@1+ (1,0) [0|65534] "s" Vector__XXX
 SG_ UI_maxBattPreconditionOnNavTime : 16|16@1+ (1,0) [0|65534] "s" Vector__XXX
 SG_ UI_tripPlanChargingTargetPercent : 32|10@1+ (0.1,0) [0|102.2] "%" Vector__XXX

BO_ 947 UI_vehicleControl2: 8 UI
 SG_ UI_gloveboxRequest : 0|1@1+ (1,0) [0|1] "" Vector__XXX
 SG_ UI_trunkRequest : 1|1@1+ (1,0) [0|1] "" Vector__XXX
 SG_ UI_UMCUpdateInhibit : 2|1@1+ (1,0) [0|1] "" Vector__XXX
 SG_ UI_WCUpdateInhibit : 3|1@1+ (1,0) [0|1] "" Vector__XXX
 SG_ UI_soundHornOnLock : 4|1@1+ (1,0) [0|1] "" Vector__XXX
 SG_ UI_locksPanelActive : 5|1@1+ (1,0) [0|1] "" Vector__XXX
 SG_ UI_PINToDriveEnabled : 6|1@1+ (1,0) [0|1] "" Vector__XXX
 SG_ UI_PINToDrivePassed : 7|1@1+ (1,0) [0|1] "" Vector__XXX
 SG_ UI_disableMirrorAutoDim : 8|1@1+ (1,0) [0|1] "" Vector__XXX
 SG_ UI_lightSwitch : 9|3@1+ (1,0) [0|7] "" Vector__XXX
 SG_ UI_readyToAddKey : 12|1@1+ (1,0) [0|1] "" Vector__XXX
 SG_ UI_alarmTriggerRequest : 13|1@1+ (1,0) [0|1] "" Vector__XXX
 SG_ UI_VCSECFeature1 : 14|1@1+ (1,0) [0|1] "" Vector__XXX
 SG_ UI_VCLEFTFeature1 : 15|1@1+ (1,0) [0|1] "" Vector__XXX
 SG_ UI_summonState : 16|2@1+ (1,0) [1|3] "" Vector__XXX
 SG_ UI_displayOnForUser : 18|1@1+ (1,0) [0|1] "" Vector__XXX
 SG_ UI_freeRollModeRequest : 19|1@1+ (1,0) [0|1] "" Vector__XXX
 SG_ UI_BLEPushNotificationRequest : 20|1@1+ (1,0) [0|1] "" Vector__XXX
 SG_ UI_pairKeyQRCodeDisplaying : 21|1@1+ (1,0) [0|1] "" Vector__XXX
 SG_ UI_keepAutopilotAwake : 22|1@1+ (1,0) [0|1] "" Vector__XXX
 SG_ UI_batteryPreconditioningRequest : 23|1@1+ (1,0) [0|1] "" Vector__XXX
 SG_ UI_coastDownMode : 24|1@1+ (1,0) [0|1] "" Vector__XXX
 SG_ UI_autopilotPowerStateRequest : 25|2@1+ (1,0) [0|3] "" Vector__XXX
 SG_ UI_shorted12VCellTestMode : 27|2@1+ (1,0) [0|3] "" Vector__XXX
 SG_ UI_autoRollWindowsOnLockEnable : 29|1@1+ (1,0) [0|1] "" Vector__XXX
 SG_ UI_virtualPitchSensorOverrideOKF : 30|1@1+ (1,0) [0|1] "" Vector__XXX
 SG_ UI_conditionalLoggingEnabledVCSE : 31|1@1+ (1,0) [0|1] "" Vector__XXX
 SG_ UI_WC3UpdateInhibit : 32|1@1+ (1,0) [0|1] "" Vector__XXX
 SG_ UI_steeringWheelHeatReq : 33|1@1+ (1,0) [0|1] "" Vector__XXX
 SG_ UI_disableHorn : 34|1@1+ (1,0) [0|1] "" Vector__XXX
 SG_ UI_frontLeftSeatFanReq : 37|2@1+ (1,0) [0|3] "" Vector__XXX
 SG_ UI_frontRightSeatAutoClimateReq : 39|1@1+ (1,0) [0|1] "" Vector__XXX
 SG_ UI_frontRightSeatFanReq : 40|2@1+ (1,0) [0|3] "" Vector__XXX
 SG_ UI_sleepFeature1 : 51|1@1+ (1,0) [0|1] "" Vector__XXX
 SG_ UI_dcr12VThreshold : 52|4@1+ (1,0) [0|15] "" Vector__XXX
 SG_ UI_frontLeftSeatAutoClimateReq : 56|1@1+ (1,0) [0|1] "" Vector__XXX
 SG_ UI_wiperHeaterReq : 57|1@1+ (1,0) [0|1] "" Vector__XXX
 SG_ UI_tireSeason : 59|1@1+ (1,0) [0|1] "" Vector__XXX
 SG_ UI_saveTireConfigReq : 60|1@1+ (1,0) [0|1] "" Vector__XXX
 SG_ UI_silentAlarm : 61|1@1+ (1,0) [0|1] "" Vector__XXX
 SG_ UI_sleepFeature2 : 63|1@1+ (1,0) [0|1] "" Vector__XXX

BO_ 628 UI_vehicleControl3: 8 UI
 SG_ UI_lightFlashRequest : 0|2@1+ (1,0) [0|3] "" Vector__XXX
 SG_ UI_keylessDrivingEnabled : 2|1@1+ (1,0) [0|1] "" Vector__XXX
 SG_ UI_phoneCallActive : 3|1@1+ (1,0) [0|1] "" Vector__XXX
 SG_ UI_drivingSideVEH : 4|2@1+ (1,0) [0|3] "" Vector__XXX
 SG_ UI_keyPairResponse : 6|2@1+ (1,0) [0|3] "" Vector__XXX
 SG_ UI_lightShowClosuresEnabled : 8|1@1+ (1,0) [0|1] "" Vector__XXX
 SG_ UI_steeringWheelHeatAutoReq : 9|1@1+ (1,0) [0|1] "" Vector__XXX
 SG_ UI_steeringWheelHeatLevelReq : 10|2@1+ (1,0) [0|3] "" Vector__XXX
 SG_ UI_headlightPulseRequest : 12|1@1+ (1,0) [0|1] "" Vector__XXX
 SG_ UI_VCSECFeature2 : 13|1@1+ (1,0) [0|1] "" Vector__XXX
 SG_ UI_VCSECFeature3 : 14|1@1+ (1,0) [0|1] "" Vector__XXX
 SG_ UI_VCSECFeature4 : 15|1@1+ (1,0) [0|1] "" Vector__XXX
 SG_ UI_VCSECFeature5 : 16|1@1+ (1,0) [0|1] "" Vector__XXX
 SG_ UI_shortHornRequest : 17|1@1+ (1,0) [0|1] "" Vector__XXX
 SG_ UI_packTempLoggingRequest : 18|1@1+ (1,0) [0|1] "" Vector__XXX
 SG_ UI_UMC3UpdateInhibit : 22|1@1+ (1,0) [0|1] "" Vector__XXX
 SG_ UI_handsFreeTrunk : 23|1@1+ (1,0) [0|1] "" Vector__XXX
 SG_ UI_displayRedShiftActive : 24|1@1+ (1,0) [0|1] "" Vector__XXX
 SG_ UI_handsFreeFrunk : 25|1@1+ (1,0) [0|1] "" Vector__XXX
 SG_ UI_fasciaCameraWashRequest : 26|1@1+ (1,0) [0|1] "" Vector__XXX
 SG_ UI_autoClosuresExcludeHome : 27|1@1+ (1,0) [0|1] "" Vector__XXX
 SG_ UI_leftRearSeatAdjustmentRequest : 28|3@1+ (1,0) [0|7] "" Vector__XXX
 SG_ UI_rightRearSeatAdjustmentReques : 32|3@1+ (1,0) [0|7] "" Vector__XXX
 SG_ UI_blindSpotIndicatorLightReques : 35|1@1+ (1,0) [0|1] "" Vector__XXX
 SG_ UI_etcBluetoothControl : 36|2@1+ (1,0) [0|3] "" Vector__XXX
 SG_ UI_keepOnAccessoryPortsReq : 38|1@1+ (1,0) [0|1] "" Vector__XXX
 SG_ UI_fasciaCameraShown : 39|1@1+ (1,0) [0|1] "" Vector__XXX
 SG_ UI_rearSeatChildLock : 40|2@1+ (1,0) [0|3] "" Vector__XXX
 SG_ UI_windowPercentageRequest : 42|6@1- (5,0) [-100|100] "%" Vector__XXX
 SG_ UI_windowRequestedFL : 48|1@1+ (1,0) [0|1] "" Vector__XXX
 SG_ UI_windowRequestedFR : 49|1@1+ (1,0) [0|1] "" Vector__XXX
 SG_ UI_windowRequestedRL : 50|1@1+ (1,0) [0|1] "" Vector__XXX
 SG_ UI_windowRequestedRR : 51|1@1+ (1,0) [0|1] "" Vector__XXX
 SG_ UI_windowRequest : 52|3@1+ (1,0) [0|7] "" Vector__XXX
 SG_ UI_closeTrunkRequest : 55|1@1+ (1,0) [0|1] "" Vector__XXX
 SG_ UI_childPresenceDetectionDisable : 56|1@1+ (1,0) [0|1] "" Vector__XXX
 SG_ UI_derivedLoadshedFeature : 59|1@1+ (1,0) [0|1] "" Vector__XXX
 SG_ UI_rearSeatFoldConfirmed : 60|1@1+ (1,0) [0|1] "" Vector__XXX
 SG_ UI_leftRearSeatRequestFromRearDi : 61|1@1+ (1,0) [0|1] "" Vector__XXX
 SG_ UI_selfParkStandingBy : 62|1@1+ (1,0) [0|1] "" Vector__XXX
 SG_ UI_rightRearSeatRequestFromRearD : 63|1@1+ (1,0) [0|1] "" Vector__XXX

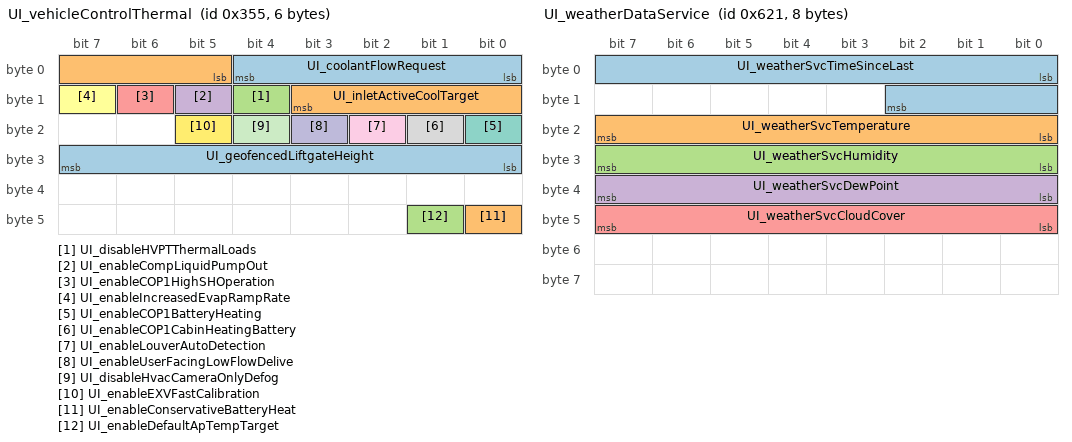
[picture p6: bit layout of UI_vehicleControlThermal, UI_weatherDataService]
BO_ 853 UI_vehicleControlThermal: 6 UI
 SG_ UI_coolantFlowRequest : 0|5@1+ (1,0) [0|25] "LPM" Vector__XXX
 SG_ UI_inletActiveCoolTarget : 5|7@1+ (1,0) [0|127] "degC" Vector__XXX
 SG_ UI_disableHVPTThermalLoads : 12|1@1+ (1,0) [0|1] "" Vector__XXX
 SG_ UI_enableCompLiquidPumpOut : 13|1@1+ (1,0) [0|1] "" Vector__XXX
 SG_ UI_enableCOP1HighSHOperation : 14|1@1+ (1,0) [0|1] "" Vector__XXX
 SG_ UI_enableIncreasedEvapRampRate : 15|1@1+ (1,0) [0|1] "" Vector__XXX
 SG_ UI_enableCOP1BatteryHeating : 16|1@1+ (1,0) [0|1] "" Vector__XXX
 SG_ UI_enableCOP1CabinHeatingBattery : 17|1@1+ (1,0) [0|1] "" Vector__XXX
 SG_ UI_enableLouverAutoDetection : 18|1@1+ (1,0) [0|1] "" Vector__XXX
 SG_ UI_enableUserFacingLowFlowDelive : 19|1@1+ (1,0) [0|1] "" Vector__XXX
 SG_ UI_disableHvacCameraOnlyDefog : 20|1@1+ (1,0) [0|1] "" Vector__XXX
 SG_ UI_enableEXVFastCalibration : 21|1@1+ (1,0) [0|1] "" Vector__XXX
 SG_ UI_geofencedLiftgateHeight : 24|8@1+ (1,0) [0|254] "cm" Vector__XXX
 SG_ UI_enableConservativeBatteryHeat : 40|1@1+ (1,0) [0|1] "" Vector__XXX
 SG_ UI_enableDefaultApTempTarget : 41|1@1+ (1,0) [0|1] "" Vector__XXX

BO_ 644 UI_vehicleModes: 8 UI
 SG_ UI_factoryMode : 0|1@1+ (1,0) [0|1] "" Vector__XXX
 SG_ UI_transportMode : 1|1@1+ (1,0) [0|1] "" Vector__XXX
 SG_ UI_showroomMode : 2|1@1+ (1,0) [0|1] "" Vector__XXX
 SG_ UI_serviceMode : 3|1@1+ (1,0) [0|1] "" Vector__XXX
 SG_ UI_isDelivered : 4|1@1+ (1,0) [0|1] "" Vector__XXX
 SG_ UI_hasEverBeenDelivered : 5|1@1+ (1,0) [0|1] "" Vector__XXX
 SG_ UI_homelinkV2Command0 : 8|8@1+ (1,0) [0|255] "" Vector__XXX
 SG_ UI_homelinkV2Command1 : 16|8@1+ (1,0) [0|255] "" Vector__XXX
 SG_ UI_homelinkV2Command2 : 24|8@1+ (1,0) [0|255] "" Vector__XXX
 SG_ UI_carWashMode : 32|1@1+ (1,0) [0|1] "" Vector__XXX
 SG_ UI_valetMode : 33|1@1+ (1,0) [0|1] "" Vector__XXX
 SG_ UI_gameMode : 34|1@1+ (1,0) [0|1] "" Vector__XXX
 SG_ UI_diagnosticsAllowed : 35|1@1+ (1,0) [0|1] "" Vector__XXX
 SG_ UI_serviceModePlus : 36|1@1+ (1,0) [0|1] "" Vector__XXX
 SG_ UI_premiumAmpPowerOff : 37|1@1+ (1,0) [0|1] "" Vector__XXX
 SG_ UI_signedCmdHardLocked : 38|1@1+ (1,0) [0|1] "" Vector__XXX
 SG_ UI_signedCmdServiceMode : 39|1@1+ (1,0) [0|1] "" Vector__XXX
 SG_ UI_closureEasterEggStatus : 40|2@1+ (1,0) [0|3] "" Vector__XXX
 SG_ UI_lightShowType : 42|3@1+ (1,0) [0|7] "" Vector__XXX
 SG_ UI_sohTestRequest : 45|1@1+ (1,0) [0|1] "" Vector__XXX
 SG_ UI_vehicleModesCounter : 52|4@1+ (1,0) [0|15] "" Vector__XXX
 SG_ UI_vehicleModesChecksum : 56|8@1+ (1,0) [0|255] "" Vector__XXX

BO_ 595 UI_ventPanelControlRequest: 8 UI
 SG_ UI_ventPanelControlRequestIndex M : 0|1@1+ (1,0) [0|1] "" Vector__XXX
 SG_ UI_ventPanelLeftPositionX m0 : 8|8@1+ (0.5,0) [0|100] "%" Vector__XXX
 SG_ UI_ventPanelLeftPositionY m0 : 16|8@1+ (0.5,0) [0|100] "%" Vector__XXX
 SG_ UI_ventPanelLeftLateralSplit m0 : 24|8@1+ (0.5,0) [0|100] "%" Vector__XXX
 SG_ UI_ventPanelRightPositionX m0 : 32|8@1+ (0.5,0) [0|100] "%" Vector__XXX
 SG_ UI_ventPanelRightPositionY m0 : 40|8@1+ (0.5,0) [0|100] "%" Vector__XXX
 SG_ UI_ventPanelRightLateralSplit m0 : 48|8@1+ (0.5,0) [0|100] "%" Vector__XXX
 SG_ UI_ventPanelLeftLateralMode m0 : 56|2@1+ (1,0) [0|3] "" Vector__XXX
 SG_ UI_ventPanelRightLateralMode m0 : 58|2@1+ (1,0) [0|3] "" Vector__XXX
 SG_ UI_hvacReqActiveVents m0 : 60|2@1+ (1,0) [0|3] "" Vector__XXX
 SG_ UI_vent2RLeftPositionX m1 : 8|8@1+ (0.5,0) [0|100] "%" Vector__XXX
 SG_ UI_vent2RLeftPositionY m1 : 16|8@1+ (0.5,0) [0|100] "%" Vector__XXX
 SG_ UI_vent2RRightPositionX m1 : 24|8@1+ (0.5,0) [0|100] "%" Vector__XXX
 SG_ UI_vent2RRightPositionY m1 : 32|8@1+ (0.5,0) [0|100] "%" Vector__XXX

BO_ 1569 UI_weatherDataService: 8 UI
 SG_ UI_weatherSvcTimeSinceLast : 0|11@1+ (1,0) [0|2046] "minutes" Vector__XXX
 SG_ UI_weatherSvcTemperature : 16|8@1- (0.5,0) [-64|63] "degC" Vector__XXX
 SG_ UI_weatherSvcHumidity : 24|8@1+ (0.5,0) [0|127] "%" Vector__XXX
 SG_ UI_weatherSvcDewPoint : 32|8@1+ (0.5,0) [0|127] "degC" Vector__XXX
 SG_ UI_weatherSvcCloudCover : 40|8@1+ (0.5,0) [0|127] "%" Vector__XXX

BO_ 1533 UMC_alertLog: 8 UMC
 SG_ UMC_alertID M : 0|15@1+ (1,0) [0|32767] "" Vector__XXX
 SG_ UMC_alertType : 15|1@1+ (1,0) [0|1] "" Vector__XXX
 SG_ UMC_a001_groundImpedance m1 : 32|32@1+ (1,0) [0|4294967295] "Ohm" Vector__XXX
 SG_ UMC_a002_ccidRmsCurrent m2 : 16|12@1+ (0.001,0) [0|4.095] "A" Vector__XXX
 SG_ UMC_a002_ccidRmsCurrentAvg m2 : 28|12@1+ (0.001,0) [0|4.095] "A" Vector__XXX
 SG_ UMC_a002_ccidFaultReason m2 : 50|4@1+ (1,0) [1|15] "" Vector__XXX
 SG_ UMC_a002_ccidFaultBucket m2 : 54|4@1+ (1,0) [0|15] "" Vector__XXX
 SG_ UMC_a003_faultType m3 : 16|8@1+ (1,0) [0|255] "" Vector__XXX
 SG_ UMC_a003_ccidSelfTestDuty m3 : 24|16@1+ (0.0001,50) [50|56.5535] "A" Vector__XXX
 SG_ UMC_a003_ccidSelfTestCurrent m3 : 40|16@1+ (0.0001,0) [0|6.5535] "A" Vector__XXX
 SG_ UMC_a004_lineVoltage m4 : 16|16@1+ (1,0) [0|65535] "Vrms" Vector__XXX
 SG_ UMC_a004_inputVoltage m4 : 32|16@1+ (0.01,0) [0|655.35] "V" Vector__XXX
 SG_ UMC_a004_inputNeutralVoltage m4 : 48|16@1+ (0.01,0) [0|655.35] "V" Vector__XXX
 SG_ UMC_a005_lineVoltage m5 : 16|16@1+ (1,0) [0|65535] "Vrms" Vector__XXX
 SG_ UMC_a005_inputVoltage m5 : 32|16@1+ (0.01,0) [0|655.35] "V" Vector__XXX
 SG_ UMC_a005_inputNeutralVoltage m5 : 48|16@1+ (0.01,0) [0|655.35] "V" Vector__XXX
 SG_ UMC_a006_outputVoltage m6 : 16|16@1+ (1,0) [0|65535] "Vrms" Vector__XXX
 SG_ UMC_a006_faultType m6 : 32|4@1+ (1,0) [0|15] "" Vector__XXX
 SG_ UMC_a006_umcReceptacleVoltage m6 : 36|12@1+ (0.1,0) [0|409.5] "V" Vector__XXX
 SG_ UMC_a006_handleVoltage m6 : 48|12@1+ (0.1,0) [0|409.5] "V" Vector__XXX
 SG_ UMC_a006_line1StuckClosed m6 : 60|1@1+ (1,0) [0|1] "" Vector__XXX
 SG_ UMC_a006_line2StuckClosed m6 : 61|1@1+ (1,0) [0|1] "" Vector__XXX
 SG_ UMC_a007_pcbaTemp m7 : 16|16@1+ (1,0) [0|65535] "degC" Vector__XXX
 SG_ UMC_a008_wallPlugTemp m8 : 16|16@1+ (1,0) [0|65535] "degC" Vector__XXX
 SG_ UMC_a008_SA_region m8 : 32|4@1+ (1,0) [0|15] "" Vector__XXX
 SG_ UMC_a008_SA_current m8 : 40|8@1+ (1,0) [0|255] "A" Vector__XXX
 SG_ UMC_a009_vehConnTemp m9 : 16|16@1+ (1,0) [0|65535] "degC" Vector__XXX
 SG_ UMC_a010_inputTerminalsTemp m10 : 16|16@1+ (1,0) [0|65535] "degC" Vector__XXX
 SG_ UMC_a012_pilotHigh m12 : 16|12@1- (0.01,0) [-20.48|20.47] "V" Vector__XXX
 SG_ UMC_a012_pilotLow m12 : 28|12@1- (0.01,0) [-20.48|20.47] "V" Vector__XXX
 SG_ UMC_a013_SA_region m13 : 16|4@1+ (1,0) [0|15] "" Vector__XXX
 SG_ UMC_a013_SA_current m13 : 24|8@1+ (1,0) [0|255] "A" Vector__XXX
 SG_ UMC_a015_SA_region m15 : 16|4@1+ (1,0) [0|15] "" Vector__XXX
 SG_ UMC_a015_SA_current m15 : 24|8@1+ (1,0) [0|255] "A" Vector__XXX
 SG_ UMC_a016_pcbaTemp m16 : 16|16@1+ (1,0) [0|65535] "degC" Vector__XXX
 SG_ UMC_a017_wallPlugTemp m17 : 16|16@1+ (1,0) [0|65535] "degC" Vector__XXX
 SG_ UMC_a017_SA_region m17 : 32|4@1+ (1,0) [0|15] "" Vector__XXX
 SG_ UMC_a017_SA_current m17 : 40|8@1+ (1,0) [0|255] "A" Vector__XXX
 SG_ UMC_a018_vehConnTemp m18 : 16|16@1+ (1,0) [0|65535] "degC" Vector__XXX
 SG_ UMC_a019_inputTerminalsTemp m19 : 16|16@1+ (1,0) [0|65535] "degC" Vector__XXX
 SG_ UMC_a024_groundImpedance m24 : 32|32@1+ (1,0) [0|4294967295] "Ohm" Vector__XXX
 SG_ UMC_a040_groundImpedance m40 : 32|32@1+ (1,0) [0|4294967295] "Ohm" Vector__XXX

BO_ 824 UMC_alertMatrix1: 8 UMC
 SG_ UMC_a001_gndMonIntrptLineSide : 0|1@1+ (1,0) [0|1] "" Vector__XXX
 SG_ UMC_a002_GFCITripped : 1|1@1+ (1,0) [0|1] "" Vector__XXX
 SG_ UMC_a003_GFCISelfTestFault : 2|1@1+ (1,0) [0|1] "" Vector__XXX
 SG_ UMC_a004_inputOverVoltage : 3|1@1+ (1,0) [0|1] "" Vector__XXX
 SG_ UMC_a005_inputUnderVoltage : 4|1@1+ (1,0) [0|1] "" Vector__XXX
 SG_ UMC_a006_contactorWelded : 5|1@1+ (1,0) [0|1] "" Vector__XXX
 SG_ UMC_a007_pcbaOT : 6|1@1+ (1,0) [0|1] "" Vector__XXX
 SG_ UMC_a008_wallPlugOT : 7|1@1+ (1,0) [0|1] "" Vector__XXX
 SG_ UMC_a009_vehConnOT : 8|1@1+ (1,0) [0|1] "" Vector__XXX
 SG_ UMC_a010_inputOT : 9|1@1+ (1,0) [0|1] "" Vector__XXX
 SG_ UMC_a011_proxDisconnected : 10|1@1+ (1,0) [0|1] "" Vector__XXX
 SG_ UMC_a012_pilotFault : 11|1@1+ (1,0) [0|1] "" Vector__XXX
 SG_ UMC_a013_SA_Temperature : 12|1@1+ (1,0) [0|1] "" Vector__XXX
 SG_ UMC_a014_SA_Genealogy : 13|1@1+ (1,0) [0|1] "" Vector__XXX
 SG_ UMC_a015_SA_Connection : 14|1@1+ (1,0) [0|1] "" Vector__XXX
 SG_ UMC_a016_pcbaOTFoldback : 15|1@1+ (1,0) [0|1] "" Vector__XXX
 SG_ UMC_a017_wallPlugOTFoldback : 16|1@1+ (1,0) [0|1] "" Vector__XXX
 SG_ UMC_a018_vehConnOTFoldback : 17|1@1+ (1,0) [0|1] "" Vector__XXX
 SG_ UMC_a019_inputOTFoldback : 18|1@1+ (1,0) [0|1] "" Vector__XXX
 SG_ UMC_a020_applicationCRC : 19|1@1+ (1,0) [0|1] "" Vector__XXX
 SG_ UMC_a021_dataBus : 20|1@1+ (1,0) [0|1] "" Vector__XXX
 SG_ UMC_a022_criticalRAM : 21|1@1+ (1,0) [0|1] "" Vector__XXX
 SG_ UMC_a023_adcSelfTest : 22|1@1+ (1,0) [0|1] "" Vector__XXX
 SG_ UMC_a024_gndResistanceHigh : 23|1@1+ (1,0) [0|1] "" Vector__XXX
 SG_ UMC_a025_cntrOpenExpectedClose : 24|1@1+ (1,0) [0|1] "" Vector__XXX
 SG_ UMC_a026_vRefOutOfRange : 25|1@1+ (1,0) [0|1] "" Vector__XXX
 SG_ UMC_a027_watchdogExpired : 26|1@1+ (1,0) [0|1] "" Vector__XXX
 SG_ UMC_a028_processorBooted : 27|1@1+ (1,0) [0|1] "" Vector__XXX
 SG_ UMC_a029_acPowerLoss : 28|1@1+ (1,0) [0|1] "" Vector__XXX
 SG_ UMC_a030_acLostPllLock : 29|1@1+ (1,0) [0|1] "" Vector__XXX
 SG_ UMC_a031_relayCoilVIrrational : 30|1@1+ (1,0) [0|1] "" Vector__XXX
 SG_ UMC_a032_chcVitalsRequestFailure : 31|1@1+ (1,0) [0|1] "" Vector__XXX
 SG_ UMC_a033_chcUpdateFault : 32|1@1+ (1,0) [0|1] "" Vector__XXX
 SG_ UMC_a034_v2lSAUnsupported : 33|1@1+ (1,0) [0|1] "" Vector__XXX
 SG_ UMC_a035_v2lHVACDetected : 34|1@1+ (1,0) [0|1] "" Vector__XXX
 SG_ UMC_a037_GFCICalibration : 36|1@1+ (1,0) [0|1] "" Vector__XXX
 SG_ UMC_a038_chcVitalsFault : 37|1@1+ (1,0) [0|1] "" Vector__XXX
 SG_ UMC_a039_inputOverCurrent : 38|1@1+ (1,0) [0|1] "" Vector__XXX
 SG_ UMC_a040_gndDisconnected : 39|1@1+ (1,0) [0|1] "" Vector__XXX

BO_TX_BU_ 294 : UI;
BO_TX_BU_ 1657 : UI;
BO_TX_BU_ 1021 : UI;
BO_TX_BU_ 819 : UI;
BO_TX_BU_ 531 : UI;
BO_TX_BU_ 645 : UI;
BO_TX_BU_ 1279 : UI;
BO_TX_BU_ 1139 : UI;
BO_TX_BU_ 1267 : UI;
BO_TX_BU_ 955 : UI;
BO_TX_BU_ 820 : UI;
BO_TX_BU_ 563 : UI;
BO_TX_BU_ 699 : UI;
BO_TX_BU_ 991 : UI;
BO_TX_BU_ 661 : UI;
BO_TX_BU_ 952 : UI;
BO_TX_BU_ 787 : UI;
BO_TX_BU_ 130 : UI;
BO_TX_BU_ 139 : UI;
BO_TX_BU_ 1173 : UI;
BO_TX_BU_ 1174 : UI;
BO_TX_BU_ 1175 : UI;
BO_TX_BU_ 947 : UI;
BO_TX_BU_ 628 : UI;
BO_TX_BU_ 853 : UI;
BO_TX_BU_ 644 : UI;
BO_TX_BU_ 595 : UI;
BO_TX_BU_ 1569 : UI;
BO_TX_BU_ 1533 : UMC;
BO_TX_BU_ 824 : UMC;
CM_ BO_ 294 "Touchscreen user interface computer message: alert matrix4";
CM_ SG_ 294 UI_a193_TcuRNandFwVersionMismatc "Touchscreen user interface computer: a193 tcu r nand fw version mismatch";
CM_ SG_ 294 UI_a194_AudioweaverRestarted "Touchscreen user interface computer: a194 audioweaver restarted";
CM_ SG_ 294 UI_a195_gtwMfdUdpApiFired "Touchscreen user interface computer: a195 gtw mfd udp api fired";
CM_ SG_ 294 UI_a196_AMDI2C3BusInoperable "Touchscreen user interface computer: a196 AMDI2 C3 bus inoperable";
CM_ SG_ 294 UI_a197_AMDI2C1BusInoperable "Touchscreen user interface computer: a197 AMDI2 C1 bus inoperable";
CM_ SG_ 294 UI_a198_IncompatibleBTUSBHubHard "Touchscreen user interface computer: a198 incompatible BTUSB hub hardware";
CM_ SG_ 294 UI_a199_HighAPedalDetectedAtColl "Touchscreen user interface computer: a199 high a pedal detected at collision";
CM_ SG_ 294 UI_a200_UIFirmwareVersionMismatc "Touchscreen user interface computer: a200 UI firmware version mismatch";
CM_ SG_ 294 UI_a201_rearDisplayDisconnected "Touchscreen user interface computer: a201 rear display disconnected";
CM_ SG_ 294 UI_a202_sysMemoryIncorrect "Touchscreen user interface computer: a202 sys memory incorrect";
CM_ SG_ 294 UI_a204_ModemSleepFailure "Touchscreen user interface computer: a204 modem sleep failure";
CM_ SG_ 294 UI_a205_ModemSleepSignalMismatch "Touchscreen user interface computer: a205 modem sleep signal mismatch";
CM_ SG_ 294 UI_a206_ModemMIAAfterWake "Touchscreen user interface computer: a206 modem MIA after wake";
CM_ SG_ 294 UI_a207_mqttClientDisconnected "Touchscreen user interface computer: a207 mqtt client disconnected";
CM_ SG_ 294 UI_a208_mqttDisconnectReason "Touchscreen user interface computer: a208 mqtt disconnect reason";
CM_ SG_ 294 UI_a209_dataCallDisconnected "Touchscreen user interface computer: a209 data call disconnected";
CM_ SG_ 294 UI_a210_CellularCSRegFail "Touchscreen user interface computer: a210 cellular CS reg fail";
CM_ SG_ 294 UI_a211_AEBSDisabled "Touchscreen user interface computer: a211 AEBS disabled";
CM_ SG_ 294 UI_a212_AEBSFaulted "Touchscreen user interface computer: a212 AEBS faulted";
CM_ SG_ 294 UI_a213_ISADisabled "Touchscreen user interface computer: a213 ISA disabled";
CM_ SG_ 294 UI_a214_pmHelperFailure "Touchscreen user interface computer: a214 pm helper failure";
CM_ SG_ 294 UI_a215_compositorStallDetected "Touchscreen user interface computer: a215 compositor stall detected";
CM_ SG_ 294 UI_a216_AudioA2bCircuitProblem "Touchscreen user interface computer: a216 audio a2b circuit problem";
CM_ SG_ 294 UI_a217_CgroupMemoryPressure "Touchscreen user interface computer: a217 cgroup memory pressure";
CM_ SG_ 294 UI_a218_AudiodNoAudioDevices "Touchscreen user interface computer: a218 audiod no audio devices";
CM_ SG_ 294 UI_a219_CompositorWatchdog "Touchscreen user interface computer: a219 compositor watchdog";
CM_ SG_ 294 UI_a220_MediaBrowseError "Touchscreen user interface computer: a220 media browse error";
CM_ SG_ 294 UI_a221_NavigationServiceError "Touchscreen user interface computer: a221 navigation service error";
CM_ SG_ 294 UI_a222_QtCarRestart "Signal reported by Touchscreen user interface computer";
CM_ SG_ 294 UI_a223_databaseError "Touchscreen user interface computer: a223 database error";
CM_ SG_ 294 UI_a224_centerDisplayDisconnecte "Touchscreen user interface computer: a224 center display disconnected";
CM_ SG_ 294 UI_a225_clusterDisplayDisconnect "Touchscreen user interface computer: a225 cluster display disconnected";
CM_ SG_ 294 UI_a226_largePhoneContactSync "Touchscreen user interface computer: a226 large phone contact sync";
CM_ SG_ 294 UI_a228_pipewireXrunBurst "Touchscreen user interface computer: a228 pipewire xrun burst";
CM_ SG_ 294 UI_a229_SerDesError "Touchscreen user interface computer: a229 ser des error";
CM_ SG_ 294 UI_a230_ModemSimCardMismatch "Touchscreen user interface computer: a230 modem sim card mismatch";
CM_ SG_ 294 UI_a231_SleepCancelled "Touchscreen user interface computer: a231 sleep cancelled";
CM_ SG_ 294 UI_a232_processExitError "Touchscreen user interface computer: a232 process exit error";
CM_ SG_ 294 UI_a233_ModemRFFailure "Touchscreen user interface computer: a233 modem RF failure";
CM_ SG_ 294 UI_a234_AMDI2C0Timeout "Touchscreen user interface computer: a234 AMDI2 C0 timeout";
CM_ SG_ 294 UI_a235_AMDI2C1Timeout "Touchscreen user interface computer: a235 AMDI2 C1 timeout";
CM_ SG_ 294 UI_a236_ModemOnResetState "Touchscreen user interface computer: a236 modem on reset state";
CM_ SG_ 294 UI_a237_ClipUploadActive "Touchscreen user interface computer: a237 clip upload active";
CM_ SG_ 294 UI_a238_ModemConfigMismatch "Touchscreen user interface computer: a238 modem config mismatch";
CM_ SG_ 294 UI_a239_stateOfVehiclesFunctions "Touchscreen user interface computer: a239 state of vehicles functions feedback";
CM_ SG_ 294 UI_a240_ethError "Touchscreen user interface computer: a240 eth error";
CM_ SG_ 294 UI_a241_AxCPError "Touchscreen user interface computer: a241 ax CP error";
CM_ BO_ 1657 "Touchscreen user interface computer message: ambient lighting ctrls";
CM_ SG_ 1657 UI_ambientLightPopupOpen "Touchscreen user interface computer: ambient light popup open";
CM_ SG_ 1657 UI_rgbEnableState "Request to enable RGB lights";
CM_ SG_ 1657 UI_rgbEffectType "Reports the RGB light effect type.";
CM_ SG_ 1657 UI_rgbLightingColorHexRed "Touchscreen user interface computer: rgb lighting color hex red";
CM_ SG_ 1657 UI_rgbLightingColorHexGreen "Touchscreen user interface computer: rgb lighting color hex green";
CM_ SG_ 1657 UI_rgbLightingColorHexBlue "Touchscreen user interface computer: rgb lighting color hex blue";
CM_ SG_ 1657 UI_rgbBrightnessLevel "Reports the requested RGB brightness level; raw 127 = signal not available (SNA)";
CM_ SG_ 1657 UI_rgbTargetDOORFL "Target RGB control for front left door";
CM_ SG_ 1657 UI_rgbTargetDOORFR "Target RGB control for the front right door";
CM_ SG_ 1657 UI_rgbTargetDOORRL "Target RGB control for rear left door";
CM_ SG_ 1657 UI_rgbTargetDOORRR "Target RGB control for the rear right door";
CM_ SG_ 1657 UI_rgbTargetIPFL "Reports control for RGB lighting for the front left instrument panel.";
CM_ SG_ 1657 UI_rgbTargetIPFR "Reports control for RGB lighting for the front right instrument panel.";
CM_ BO_ 1021 "Touchscreen user interface computer message: autopilot control";
CM_ SG_ 1021 UI_autopilotControlIndex "Touchscreen user interface computer: autopilot control index";
CM_ SG_ 1021 UI_hovEnabled "UI HOV routes enabled";
CM_ SG_ 1021 UI_donDisableAutoWiperDuration "Touchscreen user interface computer: don disable auto wiper duration";
CM_ SG_ 1021 UI_donDisableOnAutoWiperSpeed "Touchscreen user interface computer: don disable on auto wiper speed";
CM_ SG_ 1021 UI_blindspotMinSpeed "Touchscreen user interface computer: blindspot min speed";
CM_ SG_ 1021 UI_blindspotDistance "Touchscreen user interface computer: blindspot distance";
CM_ SG_ 1021 UI_blindspotTTC "Touchscreen user interface computer: blindspot TTC";
CM_ SG_ 1021 UI_donStopEndOfRampBuffer "Touchscreen user interface computer: don stop end of ramp buffer";
CM_ SG_ 1021 UI_donDisableCutin "Touchscreen user interface computer: don disable cutin";
CM_ SG_ 1021 UI_smartSetSpeedOffset "TACC will apply this offset over the speed limit";
CM_ SG_ 1021 UI_smartSetSpeedOffsetType "Offset applied will be a percentage or fixed value based on this setting";
CM_ SG_ 1021 UI_autopilotMonarchBackup "Touchscreen user interface computer: autopilot monarch backup";
CM_ SG_ 1021 UI_fsdVisualizationEnabled "Touchscreen user interface computer: fsd visualization enabled";
CM_ SG_ 1021 UI_fsdStopsControlEnabled "Indicates if autopilot control for traffic lights and stops signs has been enabled by the driver";
CM_ SG_ 1021 UI_fsdContinueOnGreenWithCIPV "Touchscreen user interface computer: fsd continue on green with CIPV";
CM_ SG_ 1021 UI_smartSetSpeed "TACC will use speed limit + offset as user set speed when enabled";
CM_ SG_ 1021 UI_automaticSetSpeedOffset "Maximum set speed offset would be determined automatically when this option is enabled";
CM_ SG_ 1021 UI_apply2021_1958_ISA "Touchscreen user interface computer: apply2021 1958 ISA";
CM_ SG_ 1021 UI_apply2021_646_ELKS "Touchscreen user interface computer: apply2021 646 ELKS";
CM_ SG_ 1021 UI_apply2021_1341_DDAW "Touchscreen user interface computer: apply2021 1341 DDAW";
CM_ SG_ 1021 UI_homelinkNearby "Touchscreen user interface computer: homelink nearby";
CM_ SG_ 1021 UI_enableFullSelfDriving "Indicates if the driver has enabled FSD behaviors";
CM_ SG_ 1021 UI_hasFullSelfDriving "Indicates if the vehicle hardware, software, and dependencies allow FSD";
CM_ SG_ 1021 UI_autosteerActivation "User-selected autosteer activation method";
CM_ SG_ 1021 UI_autopilotDrivingProfile "Driving profile for autopilot control";
CM_ SG_ 1021 UI_fsdBetaRequest "User accepted disclaimer and requested FSD (Supervised) builds";
CM_ SG_ 1021 UI_fullSelfDrivingSuspended "Full self driving is suspended";
CM_ SG_ 1021 UI_disableOptionalLaneChanges "Disable optional lane changes while FSD is controlling";
CM_ SG_ 1021 UI_applyR152_AEBS "Touchscreen user interface computer: apply R152 AEBS";
CM_ SG_ 1021 UI_autopilotControlMux0Valid "Touchscreen user interface computer: autopilot control mux0 valid";
CM_ SG_ 1021 UI_selectableCameraRequest "Infotainment selectable camera state request from AP signal; raw 15 = signal not available (SNA)";
CM_ SG_ 1021 UI_overrideSleepWithSuspend "Touchscreen user interface computer: override sleep with suspend";
CM_ SG_ 1021 UI_driverMonitorConfirmation "Driver attentiveness confirmation";
CM_ SG_ 1021 UI_parkAssistUseVision "Reports if the vehicle should use vision park assist.";
CM_ SG_ 1021 UI_applyEceR79 "Touchscreen user interface computer: apply ece R79";
CM_ SG_ 1021 UI_enableMapStops "Touchscreen user interface computer: enable map stops";
CM_ SG_ 1021 UI_disableMain "Touchscreen user interface computer: disable main";
CM_ SG_ 1021 UI_disableNarrow "Touchscreen user interface computer: disable narrow";
CM_ SG_ 1021 UI_disableFisheye "Touchscreen user interface computer: disable fisheye";
CM_ SG_ 1021 UI_disableLeftPillar "Touchscreen user interface computer: disable left pillar";
CM_ SG_ 1021 UI_disableRightPillar "Touchscreen user interface computer: disable right pillar";
CM_ SG_ 1021 UI_disableLeftRepeater "Touchscreen user interface computer: disable left repeater";
CM_ SG_ 1021 UI_disableRightRepeater "Touchscreen user interface computer: disable right repeater";
CM_ SG_ 1021 UI_disableBackup "Touchscreen user interface computer: disable backup";
CM_ SG_ 1021 UI_disableRadar "Touchscreen user interface computer: disable radar";
CM_ SG_ 1021 UI_noStalkConfirmAlertHaptic "Detects if alert haptic feedback should trigger.";
CM_ SG_ 1021 UI_regulatoryLKA "Touchscreen user interface computer: regulatory LKA";
CM_ SG_ 1021 UI_regulatoryLaneAssistLevel "Touchscreen user interface computer: regulatory lane assist level";
CM_ SG_ 1021 UI_ulcSnooze "Touchscreen user interface computer: ulc snooze";
CM_ SG_ 1021 UI_noStalkConfirmAlertChime "Detects if alert chime should trigger.";
CM_ SG_ 1021 UI_factorySummonEnable "Controls Factory Summon.";
CM_ SG_ 1021 UI_apmv3Branch "Touchscreen user interface computer: apmv3 branch";
CM_ SG_ 1021 UI_enableCabinCamera "Indicates if autopilot can enable cabin camera";
CM_ SG_ 1021 UI_enableAutopilotStopWarning "Enables the Autopilot active red light warning function.";
CM_ SG_ 1021 UI_showLaneGraph "Touchscreen user interface computer: show lane graph";
CM_ SG_ 1021 UI_showTrackLabels "Touchscreen user interface computer: show track labels";
CM_ SG_ 1021 UI_hardCoreSummon "Touchscreen user interface computer: hard core summon";
CM_ SG_ 1021 UI_enableCabinCameraTelemetry "Touchscreen user interface computer: enable cabin camera telemetry";
CM_ SG_ 1021 UI_enableVisionSpeedControl "Indicates if autopilot can enable vision speed control";
CM_ SG_ 1021 UI_autopilotTelemetryInChina "Touchscreen user interface computer: autopilot telemetry in china";
CM_ SG_ 1021 UI_enableTeslaAutopark "Indicates if autopilot can enable Telsa Autopark control";
CM_ SG_ 1021 UI_autoTurnSignalMode "Turn signal activation mode";
CM_ SG_ 1021 UI_enableCautionLightControl "Touchscreen user interface computer: enable caution light control";
CM_ SG_ 1021 UI_applyEceR79SmartSummonOnly "Touchscreen user interface computer: apply ece R79 smart summon only";
CM_ SG_ 1021 UI_autopilotMonarchEnabled "Touchscreen user interface computer: autopilot monarch enabled";
CM_ SG_ 1021 UI_autopilotEphemerisEnabled "Touchscreen user interface computer: autopilot ephemeris enabled";
CM_ SG_ 1021 UI_enableCabinAudioRecording "Indicates if autopilot can record cabin audio";
CM_ SG_ 1021 UI_autopilotControlMux1Valid "Touchscreen user interface computer: autopilot control mux1 valid";
CM_ SG_ 1021 UI_enableApproachingEmergencyVeh "Touchscreen user interface computer: enable approaching emergency vehicle detection";
CM_ SG_ 1021 UI_enableStartFsdFromParkBrakeCo "Touchscreen user interface computer: enable start fsd from park brake confirmation";
CM_ SG_ 1021 UI_enableStartFsdFromPark "Touchscreen user interface computer: enable start fsd from park";
CM_ SG_ 1021 UI_fsdMaxSpeedOffsetPercentage "Touchscreen user interface computer: fsd max speed offset percentage";
CM_ SG_ 1021 UI_coldStartMonarchInFactory "Touchscreen user interface computer: cold start monarch in factory";
CM_ SG_ 1021 UI_autopilotControlMux2Valid "Touchscreen user interface computer: autopilot control mux2 valid";
CM_ BO_ 819 "Touchscreen user interface computer message: charge request";
CM_ SG_ 819 UI_openChargePortDoorRequest "Request to open charge port.";
CM_ SG_ 819 UI_closeChargePortDoorRequest "Request to close charge port.";
CM_ SG_ 819 UI_chargeEnableRequest "Charging request initiated";
CM_ SG_ 819 UI_brickVLoggingRequest "Touchscreen user interface computer: brick v logging request";
CM_ SG_ 819 UI_brickBalancingDisabled "Touchscreen user interface computer: brick balancing disabled";
CM_ SG_ 819 UI_dSocAlertThreshold "Touchscreen user interface computer: d soc alert threshold";
CM_ SG_ 819 UI_acChargeCurrentLimit "UI charging line current request; raw 127 = signal not available (SNA)";
CM_ SG_ 819 UI_dSocAlertEnable "Set when the BMS_a117_SW_Delta_SOC_Weak_Short alert for the BMS should have a functional response";
CM_ SG_ 819 UI_chargeTerminationPct "Charge Termination Limit Percent";
CM_ SG_ 819 UI_chargeFeature1 "Touchscreen user interface computer: charge feature1";
CM_ SG_ 819 UI_chargeFeature2 "Touchscreen user interface computer: charge feature2";
CM_ SG_ 819 UI_chargeFeature3 "Touchscreen user interface computer: charge feature3";
CM_ SG_ 819 UI_scheduledDepartureEnabled "Reports scheduled departure feature enablement.";
CM_ SG_ 819 UI_chargePortLatchRequest "Request to engage or disengage the latch.";
CM_ SG_ 819 UI_socSnapshotExpirationTime "Touchscreen user interface computer: soc snapshot expiration time";
CM_ SG_ 819 UI_cpInletHeaterRequest "Enable charge port inlet heater";
CM_ SG_ 819 UI_chargePowerSampleRequest "Touchscreen user interface computer: charge power sample request";
CM_ SG_ 819 UI_enableIso15118 "Touchscreen user interface computer: enable iso15118";
CM_ BO_ 531 "Touchscreen user interface computer message: cruise control";
CM_ SG_ 531 UI_cruiseSpeedCommand "User command to change the cruise set speed.";
CM_ SG_ 531 UI_smartSummonRequest "Touchscreen user interface computer: smart summon request";
CM_ SG_ 531 UI_cruiseControlCounter "Touchscreen user interface computer: cruise control counter";
CM_ SG_ 531 UI_cruiseControlChecksum "Touchscreen user interface computer: cruise control checksum";
CM_ BO_ 645 "Touchscreen user interface computer message: driver profile recall";
CM_ SG_ 645 UI_driverProfileRecallIndex "Touchscreen user interface computer: driver profile recall index; raw 0 = signal not available (SNA)";
CM_ SG_ 645 UI_driverProfileRecallStop "notifies controller to stop profile recall action";
CM_ SG_ 645 UI_frontSeatRecallActive "signals when driver seat presets are being recalled";
CM_ SG_ 645 UI_frontSeatTrackPos "Touchscreen user interface computer: front seat track pos";
CM_ SG_ 645 UI_frontSeatBackPos "Touchscreen user interface computer: front seat back pos";
CM_ SG_ 645 UI_frontSeatLiftPos "Touchscreen user interface computer: front seat lift pos";
CM_ SG_ 645 UI_frontSeatTiltPos "Touchscreen user interface computer: front seat tilt pos";
CM_ SG_ 645 UI_columnAndLumbarRecallActive "Touchscreen user interface computer: column and lumbar recall active";
CM_ SG_ 645 UI_steeringColumnUpDownPos "Touchscreen user interface computer: steering column up down pos";
CM_ SG_ 645 UI_lumbarAPressureHpa "Touchscreen user interface computer: lumbar a pressure hpa";
CM_ SG_ 645 UI_lumbarBPressureHpa "Touchscreen user interface computer: lumbar b pressure hpa";
CM_ SG_ 645 UI_steeringColumnInOutPos "Touchscreen user interface computer: steering column in out pos";
CM_ SG_ 645 UI_leftMirrorTiltXPosition "signal from ui to command mirror X tilt position";
CM_ SG_ 645 UI_leftMirrorTiltYPosition "signal from ui to command mirror Y tilt position";
CM_ SG_ 645 UI_rightMirrorTiltXPosition "Touchscreen user interface computer: right mirror tilt x position";
CM_ SG_ 645 UI_rightMirrorTiltYPosition "Touchscreen user interface computer: right mirror tilt y position";
CM_ SG_ 645 UI_mirrorRecallActive "Touchscreen user interface computer: mirror recall active";
CM_ SG_ 645 UI_customMirrorDipPositionsSet "Reports whether custom mirror dip positions are set.";
CM_ SG_ 645 UI_leftMirrorDipXPosition "signal from ui to command left mirror X dip position";
CM_ SG_ 645 UI_leftMirrorDipYPosition "signal from ui to command mirror Y dip position";
CM_ SG_ 645 UI_rightMirrorDipXPosition "Touchscreen user interface computer: right mirror dip x position";
CM_ SG_ 645 UI_rightMirrorDipYPosition "Touchscreen user interface computer: right mirror dip y position";
CM_ SG_ 645 UI_modifyMirrorDipRequest "Reports that a user is trying to modify the mirrors in the dipped position.";
CM_ BO_ 1279 "Touchscreen user interface computer message: energy consumption info";
CM_ SG_ 1279 UI_energyConsumptionInfoIndex "Touchscreen user interface computer: energy consumption info index";
CM_ SG_ 1279 UI_energyLossTotal_epa "Energy amount for a given bucket for an energy consumption baseline (raw/real energy consumed)";
CM_ SG_ 1279 UI_energyLossDriving_epa "Energy amount for a given bucket for an energy consumption baseline (raw/real energy consumed)";
CM_ SG_ 1279 UI_energyLossClimate_epa "Energy amount for a given bucket for an energy consumption baseline (raw/real energy consumed)";
CM_ SG_ 1279 UI_energyLossBattCond_epa "Energy amount for a given bucket for an energy consumption baseline (raw/real energy consumed)";
CM_ SG_ 1279 UI_energyLossElevation_epa "Energy amount for a given bucket for an energy consumption baseline (raw/real energy consumed)";
CM_ SG_ 1279 UI_energyLossAcc_epa "Energy amount for a given bucket for an energy consumption baseline (raw/real energy consumed)";
CM_ SG_ 1279 UI_energyLossTotalSinceCharge_ep "Energy amount for a given bucket for an energy consumption baseline (raw/real energy consumed)";
CM_ SG_ 1279 UI_energyLossDrivingSinceCharge_ "Energy amount for a given bucket for an energy consumption baseline (raw/real energy consumed)";
CM_ SG_ 1279 UI_energyLossClimateSinceCharge_ "Energy amount for a given bucket for an energy consumption baseline (raw/real energy consumed)";
CM_ SG_ 1279 UI_energyLossBattCondSinceCharge "Energy amount for a given bucket for an energy consumption baseline (raw/real energy consumed)";
CM_ SG_ 1279 UI_energyLossElevationSinceCharg "Energy amount for a given bucket for an energy consumption baseline (raw/real energy consumed)";
CM_ SG_ 1279 UI_energyLossAccSinceCharge_epa "Energy amount for a given bucket for an energy consumption baseline (raw/real energy consumed)";
CM_ SG_ 1279 UI_energyLossTotalSinceTripStart "Energy amount for a given bucket for an energy consumption baseline (raw/real energy consumed)";
CM_ SG_ 1279 UI_energyLossDrivingSinceTripSta "Energy amount for a given bucket for an energy consumption baseline (raw/real energy consumed)";
CM_ SG_ 1279 UI_energyLossClimateSinceTripSta "Energy amount for a given bucket for an energy consumption baseline (raw/real energy consumed)";
CM_ SG_ 1279 UI_energyLossBattCondSinceTripSt "Energy amount for a given bucket for an energy consumption baseline (raw/real energy consumed)";
CM_ SG_ 1279 UI_energyLossElevationSinceTripS "Energy amount for a given bucket for an energy consumption baseline (raw/real energy consumed)";
CM_ SG_ 1279 UI_energyLossAccSinceTripStart "Energy amount for a given bucket for an energy consumption baseline (raw/real energy consumed)";
CM_ SG_ 1279 UI_energyDeltaTotal_epa "Energy amount for a given bucket for an energy consumption baseline (raw/real energy consumed)";
CM_ SG_ 1279 UI_energyDeltaDriving_epa "Energy amount for a given bucket for an energy consumption baseline (raw/real energy consumed)";
CM_ SG_ 1279 UI_energyDeltaClimate_epa "Energy amount for a given bucket for an energy consumption baseline (raw/real energy consumed)";
CM_ SG_ 1279 UI_energyDeltaBattCond_epa "Energy amount for a given bucket for an energy consumption baseline (raw/real energy consumed)";
CM_ SG_ 1279 UI_energyDeltaElevation_epa "Energy amount for a given bucket for an energy consumption baseline (raw/real energy consumed)";
CM_ SG_ 1279 UI_energyDeltaAcc_epa "Energy amount for a given bucket for an energy consumption baseline (raw/real energy consumed)";
CM_ SG_ 1279 UI_uiDeltaOffsetTotal_epa "Energy amount for a given bucket for an energy consumption baseline (raw/real energy consumed)";
CM_ SG_ 1279 UI_uiDeltaOffsetDriving_epa "Energy amount for a given bucket for an energy consumption baseline (raw/real energy consumed)";
CM_ SG_ 1279 UI_uiDeltaOffsetClimate_epa "Energy amount for a given bucket for an energy consumption baseline (raw/real energy consumed)";
CM_ SG_ 1279 UI_uiDeltaOffsetBattCond_epa "Energy amount for a given bucket for an energy consumption baseline (raw/real energy consumed)";
CM_ SG_ 1279 UI_uiDeltaOffsetElevation_epa "Energy amount for a given bucket for an energy consumption baseline (raw/real energy consumed)";
CM_ SG_ 1279 UI_uiDeltaOffsetAcc_epa "Energy amount for a given bucket for an energy consumption baseline (raw/real energy consumed)";
CM_ SG_ 1279 UI_rawToUiEnergyRatio_epa "Ratio used for conversion between UI and raw energy domains";
CM_ SG_ 1279 UI_driveDistance_epa "Distance driven for an energy consumption baseline";
CM_ SG_ 1279 UI_energyDeltaTotalSinceCharge_e "Energy amount for a given bucket for an energy consumption baseline (raw/real energy consumed)";
CM_ SG_ 1279 UI_energyDeltaDrivingSinceCharge "Energy amount for a given bucket for an energy consumption baseline (raw/real energy consumed)";
CM_ SG_ 1279 UI_energyDeltaClimateSinceCharge "Energy amount for a given bucket for an energy consumption baseline (raw/real energy consumed)";
CM_ SG_ 1279 UI_energyDeltaBattCondSinceCharg "Energy amount for a given bucket for an energy consumption baseline (raw/real energy consumed)";
CM_ SG_ 1279 UI_energyDeltaElevationSinceChar "Energy amount for a given bucket for an energy consumption baseline (raw/real energy consumed)";
CM_ SG_ 1279 UI_energyDeltaAccSinceCharge_epa "Energy amount for a given bucket for an energy consumption baseline (raw/real energy consumed)";
CM_ SG_ 1279 UI_uiDeltaOffsetTotalSinceCharge "Energy amount for a given bucket for an energy consumption baseline (raw/real energy consumed)";
CM_ SG_ 1279 UI_uiDeltaOffsetDrivingSinceChar "Energy amount for a given bucket for an energy consumption baseline (raw/real energy consumed)";
CM_ SG_ 1279 UI_uiDeltaOffsetClimateSinceChar "Energy amount for a given bucket for an energy consumption baseline (raw/real energy consumed)";
CM_ SG_ 1279 UI_uiDeltaOffsetBattCondSinceCha "Energy amount for a given bucket for an energy consumption baseline (raw/real energy consumed)";
CM_ SG_ 1279 UI_uiDeltaOffsetElevationSinceCh "Energy amount for a given bucket for an energy consumption baseline (raw/real energy consumed)";
CM_ SG_ 1279 UI_uiDeltaOffsetAccSinceCharge_e "Energy amount for a given bucket for an energy consumption baseline (raw/real energy consumed)";
CM_ SG_ 1279 UI_rawToUiEnergyRatioSinceCharge "Ratio used for conversion between UI and raw energy domains";
CM_ SG_ 1279 UI_driveDistanceSinceCharge_epa "Distance driven for an energy consumption baseline";
CM_ SG_ 1279 UI_energyDeltaTotalSinceTripStar "Energy amount for a given bucket for an energy consumption baseline (raw/real energy consumed)";
CM_ SG_ 1279 UI_energyDeltaDrivingSinceTripSt "Energy amount for a given bucket for an energy consumption baseline (raw/real energy consumed)";
CM_ SG_ 1279 UI_energyDeltaClimateSinceTripSt "Energy amount for a given bucket for an energy consumption baseline (raw/real energy consumed)";
CM_ SG_ 1279 UI_energyDeltaBattCondSinceTripS "Energy amount for a given bucket for an energy consumption baseline (raw/real energy consumed)";
CM_ SG_ 1279 UI_energyDeltaElevationSinceTrip "Energy amount for a given bucket for an energy consumption baseline (raw/real energy consumed)";
CM_ SG_ 1279 UI_energyDeltaAccSinceTripStart "Energy amount for a given bucket for an energy consumption baseline (raw/real energy consumed)";
CM_ SG_ 1279 UI_uiDeltaOffsetTotalSinceTripSt "Energy amount for a given bucket for an energy consumption baseline (raw/real energy consumed)";
CM_ SG_ 1279 UI_uiDeltaOffsetDrivingSinceTrip "Energy amount for a given bucket for an energy consumption baseline (raw/real energy consumed)";
CM_ SG_ 1279 UI_uiDeltaOffsetClimateSinceTrip "Energy amount for a given bucket for an energy consumption baseline (raw/real energy consumed)";
CM_ SG_ 1279 UI_uiDeltaOffsetBattCondSinceTri "Energy amount for a given bucket for an energy consumption baseline (raw/real energy consumed)";
CM_ SG_ 1279 UI_uiDeltaOffsetElevationSinceTr "Energy amount for a given bucket for an energy consumption baseline (raw/real energy consumed)";
CM_ SG_ 1279 UI_uiDeltaOffsetAccSinceTripStar "Energy amount for a given bucket for an energy consumption baseline (raw/real energy consumed)";
CM_ SG_ 1279 UI_rawToUiEnergyRatioSinceTripSt "Ratio used for conversion between UI and raw energy domains";
CM_ SG_ 1279 UI_driveDistanceSinceTripStart "Distance driven for an energy consumption baseline";
CM_ SG_ 1279 UI_voyagerEnabled "Touchscreen user interface computer: voyager enabled";
CM_ SG_ 1279 UI_trailerMass "Trailer mass from user input";
CM_ BO_ 1139 "Touchscreen user interface computer message: eth nm";
CM_ SG_ 1139 UI_nmGoingToSleep "Touchscreen user interface computer: nm going to sleep";
CM_ SG_ 1139 UI_nmKeepAwakeReason "reason UI is being kept awake; raw 0 = signal not available (SNA)";
CM_ SG_ 1139 UI_wakeupTime "Unix epoch time at which vehicle should wake for scheduled charge or update.";
CM_ BO_ 1267 "Touchscreen user interface computer message: front seat requests";
CM_ SG_ 1267 UI_frontRightSeatTrackForward "Touchscreen user interface computer: front right seat track forward";
CM_ SG_ 1267 UI_frontRightSeatTrackBack "Touchscreen user interface computer: front right seat track back";
CM_ SG_ 1267 UI_frontLeftSeatTrackForward "Touchscreen user interface computer: front left seat track forward";
CM_ SG_ 1267 UI_frontLeftSeatTrackBack "Touchscreen user interface computer: front left seat track back";
CM_ SG_ 1267 UI_frontRightSeatBackrestBack "Touchscreen user interface computer: front right seat backrest back";
CM_ SG_ 1267 UI_frontRightSeatBackrestForward "Touchscreen user interface computer: front right seat backrest forward";
CM_ SG_ 1267 UI_frontLeftSeatBackrestBack "Touchscreen user interface computer: front left seat backrest back";
CM_ SG_ 1267 UI_frontLeftSeatBackrestForward "Touchscreen user interface computer: front left seat backrest forward";
CM_ BO_ 955 "Touchscreen user interface computer message: power";
CM_ SG_ 955 UI_powerExpected "Touchscreen user interface computer: power expected";
CM_ SG_ 955 UI_powerIdeal "Touchscreen user interface computer: power ideal";
CM_ BO_ 820 "Touchscreen user interface computer message: powertrain control";
CM_ SG_ 820 UI_systemPowerLimit "Touchscreen user interface computer: system power limit; raw 31 = signal not available (SNA)";
CM_ SG_ 820 UI_pedalMap "Switch between various platform specific pedal maps";
CM_ SG_ 820 UI_enableRegenBackfill "Indicates if regenerative braking backfill has been enabled by the driver";
CM_ SG_ 820 UI_systemTorqueLimit "Touchscreen user interface computer: system torque limit; raw 63 = signal not available (SNA)";
CM_ SG_ 820 UI_closureConfirmed "Touchscreen user interface computer: closure confirmed";
CM_ SG_ 820 UI_regenTorqueMax "Maximum regen torque from UI - reports different value when in track mode";
CM_ SG_ 820 UI_limitMode "Commands limited drive inverter capabilities based on special vehicle modes";
CM_ SG_ 820 UI_factoryCustomerDrivingModeReq "Touchscreen user interface computer: factory customer driving mode request";
CM_ SG_ 820 UI_motorOnMode "Request from the UI to selectively enable or disable a drive unit (dev-only)";
CM_ SG_ 820 UI_wasteMode "Touchscreen user interface computer: waste mode";
CM_ SG_ 820 UI_wasteModeRegenLimit "Touchscreen user interface computer: waste mode regen limit";
CM_ SG_ 820 UI_stoppingMode "Low-speed behavior when no pedal is pressed (stopping/rolling/creeping)";
CM_ SG_ 820 UI_DIAppSliderDebug "Touchscreen user interface computer: DI app slider debug";
CM_ SG_ 820 UI_speedLimit "Maximum allowed speed enforced at vehicle level; raw 511 = signal not available (SNA)";
CM_ SG_ 820 UI_enableSmartShift "Stalkless convenience feature that allows unparking with only a firm press of brake pedal";
CM_ SG_ 820 UI_navVehParallelToRdCanContinue "Whether the vehicle is parallel parked on a public road; raw 0 = signal not available (SNA)";
CM_ SG_ 820 UI_powertrainControlCounter "Touchscreen user interface computer: powertrain control counter";
CM_ SG_ 820 UI_powertrainControlChecksum "Touchscreen user interface computer: powertrain control checksum";
CM_ BO_ 563 "Touchscreen user interface computer message: stalkless control";
CM_ SG_ 563 UI_stalklessControlCounter "Touchscreen user interface computer: stalkless control counter";
CM_ SG_ 563 UI_stalklessControlChecksum "Touchscreen user interface computer: stalkless control checksum";
CM_ SG_ 563 UI_gearStripSuppressCounter "Touchscreen user interface computer: gear strip suppress counter";
CM_ SG_ 563 UI_gearRequest "UI gear request from UI; raw 0 = signal not available (SNA)";
CM_ SG_ 563 UI_autopilotRequest "Touchscreen user interface computer: autopilot request";
CM_ SG_ 563 UI_fullScreenMode "Aggregates all situations with which the UI is using the entire screen so stalkless gear controls are not present";
CM_ SG_ 563 UI_gearStripShowing "UI communicating to GTW that the gear strip is visible on the screen as part of a handshake";
CM_ SG_ 563 UI_gearStripLocation "Touchscreen user interface computer: gear strip location";
CM_ SG_ 563 UI_parkButtonShowing "Touchscreen user interface computer: park button showing";
CM_ SG_ 563 UI_neutralButtonShowing "Touchscreen user interface computer: neutral button showing";
CM_ SG_ 563 UI_gearStripForceShow "UI request to GTW to show the gear strip";
CM_ SG_ 563 UI_neutralButtonDrawerForceShow "Touchscreen user interface computer: neutral button drawer force show";
CM_ SG_ 563 UI_autoParkAvailable "UI communicating to GTW that the autpark functionality is available";
CM_ SG_ 563 UI_autoParkShowing "Touchscreen user interface computer: auto park showing";
CM_ SG_ 563 UI_gearStripSuppressActive "UI communicating to GTW that the gear strip should not be shown";
CM_ SG_ 563 UI_gearNeutralPressed "Neutral button is being pressed";
CM_ BO_ 699 "Touchscreen user interface computer message: stalkless health status";
CM_ SG_ 699 UI_centerDisplayRunning "is center display running";
CM_ SG_ 699 UI_centerDisplaySM "Touchscreen user interface computer: center display SM";
CM_ SG_ 699 UI_centerDisplayPowerOn "center display power on";
CM_ SG_ 699 UI_centerDisplayCrtcOk "Touchscreen user interface computer: center display crtc ok";
CM_ SG_ 699 UI_centerDisplayHardwareOk "Touchscreen user interface computer: center display hardware ok";
CM_ SG_ 699 UI_centerDisplayWindowManagerOk "Touchscreen user interface computer: center display window manager ok";
CM_ SG_ 699 UI_centerDisplayCompositorOk "Touchscreen user interface computer: center display compositor ok";
CM_ BO_ 991 "Touchscreen user interface computer message: status2";
CM_ SG_ 991 UI_mobileAppStepCount "Touchscreen user interface computer: mobile app step count";
CM_ SG_ 991 UI_userRequestSnapshot "Touchscreen user interface computer: user request snapshot";
CM_ SG_ 991 UI_touchDetected "Touchscreen user interface computer: touch detected";
CM_ SG_ 991 UI_validDeviceForEUSummon "Touchscreen user interface computer: valid device for EU summon";
CM_ SG_ 991 UI_locatedAtHome "Touchscreen user interface computer: located at home";
CM_ SG_ 991 UI_locatedAtWork "Touchscreen user interface computer: located at work";
CM_ SG_ 991 UI_locatedAtFavorite "Touchscreen user interface computer: located at favorite";
CM_ SG_ 991 UI_displayInDarkMode "Touchscreen user interface computer: display in dark mode";
CM_ SG_ 991 UI_userActivity "Indicates user interaction with the center display";
CM_ SG_ 991 UI_activeTouchPoints "Quantity of active touch points on the Center Display";
CM_ SG_ 991 UI_linkState "Connectivity link state";
CM_ SG_ 991 UI_sentryModeState "Touchscreen user interface computer: sentry mode state; raw 6 = signal not available (SNA)";
CM_ SG_ 991 UI_autopilotSentryRequest "whether AP sentry mode should be enabled";
CM_ SG_ 991 UI_mobileAppConnected "Reports if Web Real-Time Communication (WebRTC) connection is connected while summon screen is open on the mobile app.";
CM_ SG_ 991 UI_autoshiftDRState "Reports the User Interface (UI) autoshift Drive/Reverse state.";
CM_ SG_ 991 UI_wifiBtModuleType "Reports the type of Wi-Fi and Bluetooth (BT) module.";
CM_ SG_ 991 UI_sohHealthStatus "Touchscreen user interface computer: soh health status";
CM_ SG_ 991 UI_selfParkState "Reports the auto park state changes; raw 255 = signal not available (SNA)";
CM_ SG_ 991 UI_summonDeviceIndex "Reports which device is being used to control summon.";
CM_ SG_ 991 UI_sentryModeCameraDetection "Touchscreen user interface computer: sentry mode camera detection";
CM_ SG_ 991 UI_wakeOnIPActive "Touchscreen user interface computer: wake on IP active";
CM_ BO_ 661 "Touchscreen user interface computer message: system monitor";
CM_ SG_ 661 UI_systemMonitorIndex "Touchscreen user interface computer: system monitor index";
CM_ SG_ 661 UI_SystemMemUsage "Monitors system memory usage";
CM_ SG_ 661 UI_QtCarMemUsage "Monitors memory usage of the primary User Interface application";
CM_ SG_ 661 UI_QtCarCPUUsage "Monitors CPU usage of the primary User Interface application";
CM_ SG_ 661 UI_emmcStatus "Touchscreen user interface computer: emmc status";
CM_ SG_ 661 UI_SystemCPUUsage "Monitors system CPU usage";
CM_ SG_ 661 UI_HomeHealth "Touchscreen user interface computer: home health";
CM_ SG_ 661 UI_VarHealth "Touchscreen user interface computer: var health";
CM_ SG_ 661 UI_LogHealth "Touchscreen user interface computer: log health";
CM_ SG_ 661 UI_TmpfsHealth "Touchscreen user interface computer: tmpfs health";
CM_ SG_ 661 UI_emmcDataWritten "Touchscreen user interface computer: emmc data written";
CM_ SG_ 661 UI_emmcTotalErases "Touchscreen user interface computer: emmc total erases";
CM_ BO_ 952 "Touchscreen user interface computer message: tpms RC psetting";
CM_ SG_ 952 UI_setRCPFront "Touchscreen user interface computer: set RCP front";
CM_ SG_ 952 UI_setRCPRear "Touchscreen user interface computer: set RCP rear";
CM_ BO_ 787 "Touchscreen user interface computer message: track mode settings";
CM_ SG_ 787 UI_trackModeRequest "User selected track mode";
CM_ SG_ 787 UI_trackRotationTendency "Touchscreen user interface computer: track rotation tendency";
CM_ SG_ 787 UI_trackStabilityAssist "Touchscreen user interface computer: track stability assist";
CM_ SG_ 787 UI_trackPostCooling "Touchscreen user interface computer: track post cooling";
CM_ SG_ 787 UI_trackCmpOverclock "Touchscreen user interface computer: track cmp overclock";
CM_ SG_ 787 UI_trackModeBrakeTemps "Touchscreen user interface computer: track mode brake temps";
CM_ SG_ 787 UI_trackDrivePowerAvailability "Reports power deployment strategy for Track Mode. Ranges from endurance limit to maximum power.";
CM_ SG_ 787 UI_trackModeSettingsCounter "Touchscreen user interface computer: track mode settings counter";
CM_ SG_ 787 UI_trackModeSettingsChecksum "Touchscreen user interface computer: track mode settings checksum";
CM_ BO_ 130 "Touchscreen user interface computer message: trip planning";
CM_ SG_ 130 UI_tripPlanningActive "Indicates that there is active route in navigation with a valid energy at destination prediction.";
CM_ SG_ 130 UI_navToSupercharger "Navigation destination is a supercharger";
CM_ SG_ 130 UI_navFastchargerType "when navigation is turned on, this enum identifies the type of fastcharger the car is navigating to based on the rated power from sc_locations";
CM_ SG_ 130 UI_battPreconditionOnNavState "Indicates to battery and thermal systems whether the battery should be actively heated, passively heated, actively cooled, or passively cooled";
CM_ SG_ 130 UI_requestActiveBatteryHeating "Flag to request BMS enable active battery heating";
CM_ SG_ 130 UI_battPreconditionOnNavPowerReq "The preconditioning power that Trip Planner is requesting from the thermal system to use for battery preconditioning (cooling or heating); raw 127 = signal not available (SNA)";
CM_ SG_ 130 UI_battPreconditionOnNavTargetT "The pack temperature that Trip Planner is targeting upon arriving to a fast charger; raw 255 = signal not available (SNA)";
CM_ SG_ 130 UI_ambientTempAtDestination "Touchscreen user interface computer: ambient temp at destination; raw 128 = signal not available (SNA)";
CM_ SG_ 130 UI_energyAtDestination "expected energy at destination in kWh for current navigation route; raw 32768 = signal not available (SNA)";
CM_ BO_ 139 "Touchscreen user interface computer message: trip planning2";
CM_ SG_ 139 UI_maxSpeedToReachDestination "maximum speed to reach destination without significant risk of running out of energy; raw 65535 = signal not available (SNA)";
CM_ SG_ 139 UI_remainingWeightedRMSSpeed "Touchscreen user interface computer: remaining weighted RMS speed; raw 65535 = signal not available (SNA)";
CM_ SG_ 139 UI_timeToDestination "remaining time to reach destination; raw 65535 = signal not available (SNA)";
CM_ BO_ 1173 "Touchscreen user interface computer message: trip planning3";
CM_ SG_ 1173 UI_predictedEnergy "initially predicted energy in kWh for current location along navigation route; raw 32768 = signal not available (SNA)";
CM_ SG_ 1173 UI_predictedEnergyLearned "Touchscreen user interface computer: predicted energy learned; raw 32768 = signal not available (SNA)";
CM_ SG_ 1173 UI_hindsightEnergy "hindsight energy, the model predicted energy based on measured speed and acceleration for the current location along navigation route; raw 32768 = signal not available (SNA)";
CM_ SG_ 1173 UI_hindsightEnergyLearned "Touchscreen user interface computer: hindsight energy learned; raw 32768 = signal not available (SNA)";
CM_ BO_ 1174 "Touchscreen user interface computer message: trip planning4";
CM_ SG_ 1174 UI_longTermEnergyModelError "Touchscreen user interface computer: long term energy model error; raw 128 = signal not available (SNA)";
CM_ SG_ 1174 UI_longTermRmsSpeedRatio "Touchscreen user interface computer: long term rms speed ratio; raw 255 = signal not available (SNA)";
CM_ SG_ 1174 UI_gradeCorrectedEnergy "Touchscreen user interface computer: grade corrected energy; raw 32768 = signal not available (SNA)";
CM_ SG_ 1174 UI_gradeCorrectedEnergyLearned "Touchscreen user interface computer: grade corrected energy learned; raw 32768 = signal not available (SNA)";
CM_ BO_ 1175 "Touchscreen user interface computer message: trip planning5";
CM_ SG_ 1175 UI_battPreconditionOnNavTime "Touchscreen user interface computer: batt precondition on nav time; raw 65535 = signal not available (SNA)";
CM_ SG_ 1175 UI_maxBattPreconditionOnNavTime "Touchscreen user interface computer: max batt precondition on nav time; raw 65535 = signal not available (SNA)";
CM_ SG_ 1175 UI_tripPlanChargingTargetPercent "Touchscreen user interface computer: trip plan charging target percent; raw 1023 = signal not available (SNA)";
CM_ BO_ 947 "Touchscreen user interface computer message: vehicle control2";
CM_ SG_ 947 UI_gloveboxRequest "UI request to open the glovebox";
CM_ SG_ 947 UI_trunkRequest "Rear trunk request";
CM_ SG_ 947 UI_UMCUpdateInhibit "Touchscreen user interface computer: UMC update inhibit";
CM_ SG_ 947 UI_WCUpdateInhibit "Touchscreen user interface computer: WC update inhibit";
CM_ SG_ 947 UI_soundHornOnLock "Touchscreen user interface computer: sound horn on lock";
CM_ SG_ 947 UI_locksPanelActive "Touchscreen user interface computer: locks panel active";
CM_ SG_ 947 UI_PINToDriveEnabled "UI customer level request to pin to drive enabled.";
CM_ SG_ 947 UI_PINToDrivePassed "UI customer level request to enable drive with pin passed.";
CM_ SG_ 947 UI_disableMirrorAutoDim "Request to disable side and rear-view mirror auto dim";
CM_ SG_ 947 UI_lightSwitch "Headlight mode; raw 4 = signal not available (SNA)";
CM_ SG_ 947 UI_readyToAddKey "Ready to add key";
CM_ SG_ 947 UI_alarmTriggerRequest "Alarm activation request from UI";
CM_ SG_ 947 UI_VCSECFeature1 "Touchscreen user interface computer: VCSEC feature1";
CM_ SG_ 947 UI_VCLEFTFeature1 "Touchscreen user interface computer: VCLEFT feature1";
CM_ SG_ 947 UI_summonState "Touchscreen user interface computer: summon state; raw 0 = signal not available (SNA)";
CM_ SG_ 947 UI_displayOnForUser "User is present";
CM_ SG_ 947 UI_freeRollModeRequest "Touchscreen user interface computer: free roll mode request";
CM_ SG_ 947 UI_BLEPushNotificationRequest "Reports that the User Interface (UI) wants to talk to a phone and Vehicle Controller Security (VCSEC) should let all connected phones know.";
CM_ SG_ 947 UI_pairKeyQRCodeDisplaying "Touchscreen user interface computer: pair key QR code displaying";
CM_ SG_ 947 UI_keepAutopilotAwake "Reports the request for Vehicle Controller (VC) to keep autopilot awake.";
CM_ SG_ 947 UI_batteryPreconditioningRequest "Requests battery preconditioning.";
CM_ SG_ 947 UI_coastDownMode "Touchscreen user interface computer: coast down mode";
CM_ SG_ 947 UI_autopilotPowerStateRequest "Requests different power states from autopilot ECU depending on feature usage.";
CM_ SG_ 947 UI_shorted12VCellTestMode "Touchscreen user interface computer: shorted12 v cell test mode";
CM_ SG_ 947 UI_autoRollWindowsOnLockEnable "UI customer level request to enable auto-roll windows on lock";
CM_ SG_ 947 UI_virtualPitchSensorOverrideOKF "Touchscreen user interface computer: virtual pitch sensor override OK for aim";
CM_ SG_ 947 UI_conditionalLoggingEnabledVCSE "Touchscreen user interface computer: conditional logging enabled VCSEC";
CM_ SG_ 947 UI_WC3UpdateInhibit "Touchscreen user interface computer: WC3 update inhibit";
CM_ SG_ 947 UI_steeringWheelHeatReq "Request to enable steering wheel heater";
CM_ SG_ 947 UI_disableHorn "Request to disable horn";
CM_ SG_ 947 UI_frontLeftSeatFanReq "Request for front left seat ventilation";
CM_ SG_ 947 UI_frontRightSeatAutoClimateReq "UI setting to enable auto seat heating and cooling for front right seat";
CM_ SG_ 947 UI_frontRightSeatFanReq "Request for front left seat ventilation";
CM_ SG_ 947 UI_sleepFeature1 "Touchscreen user interface computer: sleep feature1";
CM_ SG_ 947 UI_dcr12VThreshold "Touchscreen user interface computer: dcr12 v threshold";
CM_ SG_ 947 UI_frontLeftSeatAutoClimateReq "UI setting to enable auto seat heating and cooling for front left seat";
CM_ SG_ 947 UI_wiperHeaterReq "UI request to enable the wiper heater";
CM_ SG_ 947 UI_tireSeason "Touchscreen user interface computer: tire season";
CM_ SG_ 947 UI_saveTireConfigReq "Touchscreen user interface computer: save tire config req";
CM_ SG_ 947 UI_silentAlarm "Signal indicating alarms should be silenced";
CM_ SG_ 947 UI_sleepFeature2 "Touchscreen user interface computer: sleep feature2";
CM_ BO_ 628 "Touchscreen user interface computer message: vehicle control3";
CM_ SG_ 628 UI_lightFlashRequest "UI flash lights request";
CM_ SG_ 628 UI_keylessDrivingEnabled "Touchscreen user interface computer: keyless driving enabled";
CM_ SG_ 628 UI_phoneCallActive "On phone call via Bluetooth if active";
CM_ SG_ 628 UI_drivingSideVEH "Touchscreen user interface computer: driving side VEH";
CM_ SG_ 628 UI_keyPairResponse "Touchscreen user interface computer: key pair response";
CM_ SG_ 628 UI_lightShowClosuresEnabled "Closure movements enabled during light show";
CM_ SG_ 628 UI_steeringWheelHeatAutoReq "UI setting to request auto steering wheel heat";
CM_ SG_ 628 UI_steeringWheelHeatLevelReq "Request for steering wheel heat";
CM_ SG_ 628 UI_headlightPulseRequest "Request headlights to pulse";
CM_ SG_ 628 UI_VCSECFeature2 "Touchscreen user interface computer: VCSEC feature2";
CM_ SG_ 628 UI_VCSECFeature3 "Touchscreen user interface computer: VCSEC feature3";
CM_ SG_ 628 UI_VCSECFeature4 "Touchscreen user interface computer: VCSEC feature4";
CM_ SG_ 628 UI_VCSECFeature5 "Touchscreen user interface computer: VCSEC feature5";
CM_ SG_ 628 UI_shortHornRequest "Touchscreen user interface computer: short horn request";
CM_ SG_ 628 UI_packTempLoggingRequest "Touchscreen user interface computer: pack temp logging request";
CM_ SG_ 628 UI_UMC3UpdateInhibit "Touchscreen user interface computer: UMC3 update inhibit";
CM_ SG_ 628 UI_handsFreeTrunk "Touchscreen user interface computer: hands free trunk";
CM_ SG_ 628 UI_displayRedShiftActive "UI's reduce blue light setting is active";
CM_ SG_ 628 UI_handsFreeFrunk "Touchscreen user interface computer: hands free frunk";
CM_ SG_ 628 UI_fasciaCameraWashRequest "User request to activate fascia camera wash";
CM_ SG_ 628 UI_autoClosuresExcludeHome "Touchscreen user interface computer: auto closures exclude home";
CM_ SG_ 628 UI_leftRearSeatAdjustmentRequest "Reports request from UI to actuate the left rear seat";
CM_ SG_ 628 UI_rightRearSeatAdjustmentReques "Reports request from UI to actuate the right rear seat";
CM_ SG_ 628 UI_blindSpotIndicatorLightReques "Request for blind spot indicator light";
CM_ SG_ 628 UI_etcBluetoothControl "Touchscreen user interface computer: etc bluetooth control";
CM_ SG_ 628 UI_keepOnAccessoryPortsReq "User setting to keep 12V outlets, USB ports, and phone chargers powered in CONDITIONING";
CM_ SG_ 628 UI_fasciaCameraShown "Whether the UI is currently showing the fascia camera view";
CM_ SG_ 628 UI_rearSeatChildLock "Reports the state of second row seat fold flat child lock from the UI";
CM_ SG_ 628 UI_windowPercentageRequest "Reports the window percentage value when window request is WINDOW_REQUEST_GOTO_PERCENT.";
CM_ SG_ 628 UI_windowRequestedFL "Reports that the front left window is requested.";
CM_ SG_ 628 UI_windowRequestedFR "Reports that the front right window is requested.";
CM_ SG_ 628 UI_windowRequestedRL "Reports that the rear left window is requested.";
CM_ SG_ 628 UI_windowRequestedRR "Reports that the rear right window is requested.";
CM_ SG_ 628 UI_windowRequest "Window operation request from the mobile app.";
CM_ SG_ 628 UI_closeTrunkRequest "Explicity request for the rear trunk to close";
CM_ SG_ 628 UI_childPresenceDetectionDisable "User request to disable child presence detection behaviors until the next drive cycle";
CM_ SG_ 628 UI_derivedLoadshedFeature "Reports whether vehicle controllers should enable derived loadshed feature.";
CM_ SG_ 628 UI_rearSeatFoldConfirmed "Touchscreen user interface computer: rear seat fold confirmed";
CM_ SG_ 628 UI_leftRearSeatRequestFromRearDi "Touchscreen user interface computer: left rear seat request from rear display";
CM_ SG_ 628 UI_selfParkStandingBy "Reports that summon is in standby.";
CM_ SG_ 628 UI_rightRearSeatRequestFromRearD "Touchscreen user interface computer: right rear seat request from rear display";
CM_ BO_ 853 "Touchscreen user interface computer message: vehicle control thermal";
CM_ SG_ 853 UI_coolantFlowRequest "request for coolant flow to MCU in LPM";
CM_ SG_ 853 UI_inletActiveCoolTarget "request for coolant temperature at Car Computer inlet";
CM_ SG_ 853 UI_disableHVPTThermalLoads "Request thermal system to disable active battery heating";
CM_ SG_ 853 UI_enableCompLiquidPumpOut "Touchscreen user interface computer: enable comp liquid pump out";
CM_ SG_ 853 UI_enableCOP1HighSHOperation "Touchscreen user interface computer: enable COP1 high SH operation";
CM_ SG_ 853 UI_enableIncreasedEvapRampRate "Touchscreen user interface computer: enable increased evap ramp rate";
CM_ SG_ 853 UI_enableCOP1BatteryHeating "Touchscreen user interface computer: enable COP1 battery heating";
CM_ SG_ 853 UI_enableCOP1CabinHeatingBattery "Touchscreen user interface computer: enable COP1 cabin heating battery heating";
CM_ SG_ 853 UI_enableLouverAutoDetection "Touchscreen user interface computer: enable louver auto detection";
CM_ SG_ 853 UI_enableUserFacingLowFlowDelive "Touchscreen user interface computer: enable user facing low flow delivery alert";
CM_ SG_ 853 UI_disableHvacCameraOnlyDefog "Touchscreen user interface computer: disable hvac camera only defog";
CM_ SG_ 853 UI_enableEXVFastCalibration "Touchscreen user interface computer: enable EXV fast calibration";
CM_ SG_ 853 UI_geofencedLiftgateHeight "Touchscreen user interface computer: geofenced liftgate height; raw 255 = signal not available (SNA)";
CM_ SG_ 853 UI_enableConservativeBatteryHeat "Touchscreen user interface computer: enable conservative battery heating";
CM_ SG_ 853 UI_enableDefaultApTempTarget "Touchscreen user interface computer: enable default ap temp target";
CM_ BO_ 644 "Touchscreen user interface computer message: vehicle modes";
CM_ SG_ 644 UI_factoryMode "Touchscreen user interface computer: factory mode";
CM_ SG_ 644 UI_transportMode "Reports UI Transport mode. Distinct from GTW transport mode.";
CM_ SG_ 644 UI_showroomMode "Reports UI showroom mode.";
CM_ SG_ 644 UI_serviceMode "Service diagnostics mode active";
CM_ SG_ 644 UI_isDelivered "Touchscreen user interface computer: is delivered";
CM_ SG_ 644 UI_hasEverBeenDelivered "Touchscreen user interface computer: has ever been delivered";
CM_ SG_ 644 UI_homelinkV2Command0 "Touchscreen user interface computer: homelink V2 command0";
CM_ SG_ 644 UI_homelinkV2Command1 "Touchscreen user interface computer: homelink V2 command1";
CM_ SG_ 644 UI_homelinkV2Command2 "Touchscreen user interface computer: homelink V2 command2";
CM_ SG_ 644 UI_carWashMode "Car Wash Mode";
CM_ SG_ 644 UI_valetMode "Touchscreen user interface computer: valet mode";
CM_ SG_ 644 UI_gameMode "Game mode";
CM_ SG_ 644 UI_diagnosticsAllowed "Touchscreen user interface computer: diagnostics allowed";
CM_ SG_ 644 UI_serviceModePlus "Extended service diagnostics mode active";
CM_ SG_ 644 UI_premiumAmpPowerOff "Premium amplifier power off request";
CM_ SG_ 644 UI_signedCmdHardLocked "Touchscreen user interface computer: signed cmd hard locked";
CM_ SG_ 644 UI_signedCmdServiceMode "Signal reported by Touchscreen user interface computer";
CM_ SG_ 644 UI_closureEasterEggStatus "Touchscreen user interface computer: closure easter egg status";
CM_ SG_ 644 UI_lightShowType "Type of the light show to be run";
CM_ SG_ 644 UI_sohTestRequest "Touchscreen user interface computer: soh test request";
CM_ SG_ 644 UI_vehicleModesCounter "Touchscreen user interface computer: vehicle modes counter";
CM_ SG_ 644 UI_vehicleModesChecksum "Touchscreen user interface computer: vehicle modes checksum";
CM_ BO_ 595 "Touchscreen user interface computer message: vent panel control request";
CM_ SG_ 595 UI_ventPanelControlRequestIndex "Touchscreen user interface computer: vent panel control request index";
CM_ SG_ 595 UI_ventPanelLeftPositionX "Airwave left X position.";
CM_ SG_ 595 UI_ventPanelLeftPositionY "Airwave left Y position.";
CM_ SG_ 595 UI_ventPanelLeftLateralSplit "Airwave left split amount.";
CM_ SG_ 595 UI_ventPanelRightPositionX "Airwave right X position.";
CM_ SG_ 595 UI_ventPanelRightPositionY "Airwave right Y position.";
CM_ SG_ 595 UI_ventPanelRightLateralSplit "Airwave right split amount.";
CM_ SG_ 595 UI_ventPanelLeftLateralMode "Airwave left focus or split.";
CM_ SG_ 595 UI_ventPanelRightLateralMode "Airwave right focus or split.";
CM_ SG_ 595 UI_hvacReqActiveVents "Active airwave sides - left/right/both";
CM_ SG_ 595 UI_vent2RLeftPositionX "Airwave left X position.";
CM_ SG_ 595 UI_vent2RLeftPositionY "Airwave left Y position.";
CM_ SG_ 595 UI_vent2RRightPositionX "Airwave left X position.";
CM_ SG_ 595 UI_vent2RRightPositionY "Airwave left Y position.";
CM_ BO_ 1569 "Touchscreen user interface computer message: weather data service";
CM_ SG_ 1569 UI_weatherSvcTimeSinceLast "Touchscreen user interface computer: weather svc time since last; raw 2047 = signal not available (SNA)";
CM_ SG_ 1569 UI_weatherSvcTemperature "Touchscreen user interface computer: weather svc temperature; raw 127 = signal not available (SNA)";
CM_ SG_ 1569 UI_weatherSvcHumidity "Touchscreen user interface computer: weather svc humidity; raw 255 = signal not available (SNA)";
CM_ SG_ 1569 UI_weatherSvcDewPoint "Touchscreen user interface computer: weather svc dew point; raw 255 = signal not available (SNA)";
CM_ SG_ 1569 UI_weatherSvcCloudCover "Touchscreen user interface computer: weather svc cloud cover; raw 255 = signal not available (SNA)";
CM_ BO_ 1533 "UMC ECU message: alert log";
CM_ SG_ 1533 UMC_alertID "UMC ECU: alert ID";
CM_ SG_ 1533 UMC_alertType "UMC ECU: alert type";
CM_ SG_ 1533 UMC_a001_groundImpedance "UMC ECU: a001 ground impedance";
CM_ SG_ 1533 UMC_a002_ccidRmsCurrent "UMC ECU: a002 ccid rms current";
CM_ SG_ 1533 UMC_a002_ccidRmsCurrentAvg "UMC ECU: a002 ccid rms current avg";
CM_ SG_ 1533 UMC_a002_ccidFaultReason "UMC ECU: a002 ccid fault reason; raw 0 = signal not available (SNA)";
CM_ SG_ 1533 UMC_a002_ccidFaultBucket "UMC ECU: a002 ccid fault bucket";
CM_ SG_ 1533 UMC_a003_faultType "UMC ECU: a003 fault type";
CM_ SG_ 1533 UMC_a003_ccidSelfTestDuty "UMC ECU: a003 ccid self test duty";
CM_ SG_ 1533 UMC_a003_ccidSelfTestCurrent "UMC ECU: a003 ccid self test current";
CM_ SG_ 1533 UMC_a004_lineVoltage "UMC ECU: a004 line voltage";
CM_ SG_ 1533 UMC_a004_inputVoltage "UMC ECU: a004 input voltage";
CM_ SG_ 1533 UMC_a004_inputNeutralVoltage "UMC ECU: a004 input neutral voltage";
CM_ SG_ 1533 UMC_a005_lineVoltage "UMC ECU: a005 line voltage";
CM_ SG_ 1533 UMC_a005_inputVoltage "UMC ECU: a005 input voltage";
CM_ SG_ 1533 UMC_a005_inputNeutralVoltage "UMC ECU: a005 input neutral voltage";
CM_ SG_ 1533 UMC_a006_outputVoltage "UMC ECU: a006 output voltage";
CM_ SG_ 1533 UMC_a006_faultType "UMC ECU: a006 fault type";
CM_ SG_ 1533 UMC_a006_umcReceptacleVoltage "UMC ECU: a006 umc receptacle voltage";
CM_ SG_ 1533 UMC_a006_handleVoltage "UMC ECU: a006 handle voltage";
CM_ SG_ 1533 UMC_a006_line1StuckClosed "UMC ECU: a006 line1 stuck closed";
CM_ SG_ 1533 UMC_a006_line2StuckClosed "UMC ECU: a006 line2 stuck closed";
CM_ SG_ 1533 UMC_a007_pcbaTemp "UMC ECU: a007 pcba temp";
CM_ SG_ 1533 UMC_a008_wallPlugTemp "UMC ECU: a008 wall plug temp";
CM_ SG_ 1533 UMC_a008_SA_region "UMC ECU: a008 SA region";
CM_ SG_ 1533 UMC_a008_SA_current "UMC ECU: a008 SA current";
CM_ SG_ 1533 UMC_a009_vehConnTemp "UMC ECU: a009 veh conn temp";
CM_ SG_ 1533 UMC_a010_inputTerminalsTemp "UMC ECU: a010 input terminals temp";
CM_ SG_ 1533 UMC_a012_pilotHigh "UMC ECU: a012 pilot high";
CM_ SG_ 1533 UMC_a012_pilotLow "UMC ECU: a012 pilot low";
CM_ SG_ 1533 UMC_a013_SA_region "UMC ECU: a013 SA region";
CM_ SG_ 1533 UMC_a013_SA_current "UMC ECU: a013 SA current";
CM_ SG_ 1533 UMC_a015_SA_region "UMC ECU: a015 SA region";
CM_ SG_ 1533 UMC_a015_SA_current "UMC ECU: a015 SA current";
CM_ SG_ 1533 UMC_a016_pcbaTemp "UMC ECU: a016 pcba temp";
CM_ SG_ 1533 UMC_a017_wallPlugTemp "UMC ECU: a017 wall plug temp";
CM_ SG_ 1533 UMC_a017_SA_region "UMC ECU: a017 SA region";
CM_ SG_ 1533 UMC_a017_SA_current "UMC ECU: a017 SA current";
CM_ SG_ 1533 UMC_a018_vehConnTemp "UMC ECU: a018 veh conn temp";
CM_ SG_ 1533 UMC_a019_inputTerminalsTemp "UMC ECU: a019 input terminals temp";
CM_ SG_ 1533 UMC_a024_groundImpedance "UMC ECU: a024 ground impedance";
CM_ SG_ 1533 UMC_a040_groundImpedance "UMC ECU: a040 ground impedance";
CM_ BO_ 824 "UMC ECU message: alert matrix1";
CM_ SG_ 824 UMC_a001_gndMonIntrptLineSide "UMC ECU: a001 gnd mon intrpt line side";
CM_ SG_ 824 UMC_a002_GFCITripped "UMC ECU: a002 GFCI tripped";
CM_ SG_ 824 UMC_a003_GFCISelfTestFault "UMC ECU: a003 GFCI self test fault";
CM_ SG_ 824 UMC_a004_inputOverVoltage "UMC ECU: a004 input over voltage";
CM_ SG_ 824 UMC_a005_inputUnderVoltage "UMC ECU: a005 input under voltage";
CM_ SG_ 824 UMC_a006_contactorWelded "UMC ECU: a006 contactor welded";
CM_ SG_ 824 UMC_a007_pcbaOT "UMC ECU: a007 pcba OT";
CM_ SG_ 824 UMC_a008_wallPlugOT "UMC ECU: a008 wall plug OT";
CM_ SG_ 824 UMC_a009_vehConnOT "UMC ECU: a009 veh conn OT";
CM_ SG_ 824 UMC_a010_inputOT "UMC ECU: a010 input OT";
CM_ SG_ 824 UMC_a011_proxDisconnected "UMC ECU: a011 prox disconnected";
CM_ SG_ 824 UMC_a012_pilotFault "UMC ECU: a012 pilot fault";
CM_ SG_ 824 UMC_a013_SA_Temperature "UMC ECU: a013 SA temperature";
CM_ SG_ 824 UMC_a014_SA_Genealogy "UMC ECU: a014 SA genealogy";
CM_ SG_ 824 UMC_a015_SA_Connection "UMC ECU: a015 SA connection";
CM_ SG_ 824 UMC_a016_pcbaOTFoldback "UMC ECU: a016 pcba OT foldback";
CM_ SG_ 824 UMC_a017_wallPlugOTFoldback "UMC ECU: a017 wall plug OT foldback";
CM_ SG_ 824 UMC_a018_vehConnOTFoldback "UMC ECU: a018 veh conn OT foldback";
CM_ SG_ 824 UMC_a019_inputOTFoldback "UMC ECU: a019 input OT foldback";
CM_ SG_ 824 UMC_a020_applicationCRC "UMC ECU: a020 application CRC";
CM_ SG_ 824 UMC_a021_dataBus "UMC ECU: a021 data bus";
CM_ SG_ 824 UMC_a022_criticalRAM "UMC ECU: a022 critical RAM";
CM_ SG_ 824 UMC_a023_adcSelfTest "UMC ECU: a023 adc self test";
CM_ SG_ 824 UMC_a024_gndResistanceHigh "UMC ECU: a024 gnd resistance high";
CM_ SG_ 824 UMC_a025_cntrOpenExpectedClose "UMC ECU: a025 cntr open expected close";
CM_ SG_ 824 UMC_a026_vRefOutOfRange "UMC ECU: a026 v ref out of range";
CM_ SG_ 824 UMC_a027_watchdogExpired "UMC ECU: a027 watchdog expired";
CM_ SG_ 824 UMC_a028_processorBooted "UMC ECU: a028 processor booted";
CM_ SG_ 824 UMC_a029_acPowerLoss "UMC ECU: a029 ac power loss";
CM_ SG_ 824 UMC_a030_acLostPllLock "UMC ECU: a030 ac lost pll lock";
CM_ SG_ 824 UMC_a031_relayCoilVIrrational "UMC ECU: a031 relay coil v irrational";
CM_ SG_ 824 UMC_a032_chcVitalsRequestFailure "UMC ECU: a032 chc vitals request failure";
CM_ SG_ 824 UMC_a033_chcUpdateFault "UMC ECU: a033 chc update fault";
CM_ SG_ 824 UMC_a034_v2lSAUnsupported "UMC ECU: a034 v2l SA unsupported";
CM_ SG_ 824 UMC_a035_v2lHVACDetected "UMC ECU: a035 v2l HVAC detected";
CM_ SG_ 824 UMC_a037_GFCICalibration "UMC ECU: a037 GFCI calibration";
CM_ SG_ 824 UMC_a038_chcVitalsFault "UMC ECU: a038 chc vitals fault";
CM_ SG_ 824 UMC_a039_inputOverCurrent "UMC ECU: a039 input over current";
CM_ SG_ 824 UMC_a040_gndDisconnected "UMC ECU: a040 gnd disconnected";
BA_DEF_ BO_ "GenMsgCycleTime" INT 0 3600000;
BA_DEF_ BO_ "GenMsgSendType" ENUM "Cyclic","NotUsed","NotUsed","NotUsed","NotUsed","NotUsed","NotUsed","IfActive","NoMsgSendType","NotUsed";
BA_DEF_ BO_ "VFrameFormat" ENUM "StandardCAN","ExtendedCAN","reserved","J1939PG","reserved","reserved","reserved","reserved","reserved","reserved","reserved","reserved","reserved","reserved","StandardCAN_FD","ExtendedCAN_FD";
BA_DEF_ BO_ "CANFD_BRS" ENUM "0","1";
BA_DEF_ SG_ "GenSigSNA" STRING;
BA_DEF_ SG_ "SystemSignalLongSymbol" STRING;
BA_DEF_ SG_ "Confidence" ENUM "validated","plausible","layout-only","contradicted";
BA_DEF_DEF_ "GenMsgCycleTime" 0;
BA_DEF_DEF_ "GenMsgSendType" "NoMsgSendType";
BA_DEF_DEF_ "VFrameFormat" "StandardCAN";
BA_DEF_DEF_ "CANFD_BRS" "1";
BA_DEF_DEF_ "GenSigSNA" "";
BA_DEF_DEF_ "SystemSignalLongSymbol" "";
BA_DEF_DEF_ "Confidence" "layout-only";
BA_ "GenMsgCycleTime" BO_ 294 1000;
BA_ "GenMsgSendType" BO_ 294 0;
BA_ "GenMsgCycleTime" BO_ 1657 500;
BA_ "GenMsgSendType" BO_ 1657 0;
BA_ "GenMsgCycleTime" BO_ 1021 500;
BA_ "GenMsgSendType" BO_ 1021 0;
BA_ "GenMsgCycleTime" BO_ 819 500;
BA_ "GenMsgSendType" BO_ 819 0;
BA_ "GenMsgCycleTime" BO_ 531 500;
BA_ "GenMsgSendType" BO_ 531 0;
BA_ "GenMsgCycleTime" BO_ 645 500;
BA_ "GenMsgSendType" BO_ 645 0;
BA_ "GenMsgCycleTime" BO_ 1279 1000;
BA_ "GenMsgSendType" BO_ 1279 0;
BA_ "GenMsgCycleTime" BO_ 1139 500;
BA_ "GenMsgSendType" BO_ 1139 0;
BA_ "GenMsgCycleTime" BO_ 1267 500;
BA_ "GenMsgSendType" BO_ 1267 0;
BA_ "GenMsgCycleTime" BO_ 955 1000;
BA_ "GenMsgSendType" BO_ 955 0;
BA_ "GenMsgCycleTime" BO_ 820 500;
BA_ "GenMsgSendType" BO_ 820 0;
BA_ "GenMsgCycleTime" BO_ 563 500;
BA_ "GenMsgSendType" BO_ 563 0;
BA_ "GenMsgCycleTime" BO_ 699 500;
BA_ "GenMsgSendType" BO_ 699 0;
BA_ "GenMsgCycleTime" BO_ 991 500;
BA_ "GenMsgSendType" BO_ 991 0;
BA_ "GenMsgCycleTime" BO_ 661 15000;
BA_ "GenMsgSendType" BO_ 661 0;
BA_ "GenMsgCycleTime" BO_ 952 1000;
BA_ "GenMsgSendType" BO_ 952 0;
BA_ "GenMsgCycleTime" BO_ 787 500;
BA_ "GenMsgSendType" BO_ 787 0;
BA_ "GenMsgCycleTime" BO_ 130 1000;
BA_ "GenMsgSendType" BO_ 130 0;
BA_ "GenMsgCycleTime" BO_ 139 1000;
BA_ "GenMsgSendType" BO_ 139 0;
BA_ "GenMsgCycleTime" BO_ 1173 1000;
BA_ "GenMsgSendType" BO_ 1173 0;
BA_ "GenMsgCycleTime" BO_ 1174 1000;
BA_ "GenMsgSendType" BO_ 1174 0;
BA_ "GenMsgCycleTime" BO_ 1175 1000;
BA_ "GenMsgSendType" BO_ 1175 0;
BA_ "GenMsgCycleTime" BO_ 947 500;
BA_ "GenMsgSendType" BO_ 947 0;
BA_ "GenMsgCycleTime" BO_ 628 500;
BA_ "GenMsgSendType" BO_ 628 0;
BA_ "GenMsgCycleTime" BO_ 853 1000;
BA_ "GenMsgSendType" BO_ 853 0;
BA_ "GenMsgCycleTime" BO_ 644 500;
BA_ "GenMsgSendType" BO_ 644 0;
BA_ "GenMsgCycleTime" BO_ 595 500;
BA_ "GenMsgSendType" BO_ 595 0;
BA_ "GenMsgCycleTime" BO_ 1569 500;
BA_ "GenMsgSendType" BO_ 1569 0;
BA_ "GenMsgCycleTime" BO_ 824 1000;
BA_ "GenMsgSendType" BO_ 824 0;
BA_ "SystemSignalLongSymbol" SG_ 294 UI_a193_TcuRNandFwVersionMismatc "UI_a193_TcuRNandFwVersionMismatch";
BA_ "SystemSignalLongSymbol" SG_ 294 UI_a198_IncompatibleBTUSBHubHard "UI_a198_IncompatibleBTUSBHubHardware";
BA_ "SystemSignalLongSymbol" SG_ 294 UI_a199_HighAPedalDetectedAtColl "UI_a199_HighAPedalDetectedAtCollision";
BA_ "SystemSignalLongSymbol" SG_ 294 UI_a200_UIFirmwareVersionMismatc "UI_a200_UIFirmwareVersionMismatch";
BA_ "SystemSignalLongSymbol" SG_ 294 UI_a224_centerDisplayDisconnecte "UI_a224_centerDisplayDisconnected";
BA_ "SystemSignalLongSymbol" SG_ 294 UI_a225_clusterDisplayDisconnect "UI_a225_clusterDisplayDisconnected";
BA_ "SystemSignalLongSymbol" SG_ 294 UI_a239_stateOfVehiclesFunctions "UI_a239_stateOfVehiclesFunctionsFeedback";
BA_ "Confidence" SG_ 1657 UI_rgbEnableState 1;
BA_ "Confidence" SG_ 1657 UI_rgbEffectType 1;
BA_ "Confidence" SG_ 1657 UI_rgbBrightnessLevel 1;
BA_ "GenSigSNA" SG_ 1657 UI_rgbBrightnessLevel "127";
BA_ "Confidence" SG_ 1657 UI_rgbTargetDOORFL 1;
BA_ "Confidence" SG_ 1657 UI_rgbTargetDOORFR 1;
BA_ "Confidence" SG_ 1657 UI_rgbTargetDOORRL 1;
BA_ "Confidence" SG_ 1657 UI_rgbTargetDOORRR 1;
BA_ "Confidence" SG_ 1657 UI_rgbTargetIPFL 1;
BA_ "Confidence" SG_ 1657 UI_rgbTargetIPFR 1;
BA_ "Confidence" SG_ 1021 UI_autopilotControlIndex 1;
BA_ "Confidence" SG_ 1021 UI_hovEnabled 1;
BA_ "Confidence" SG_ 1021 UI_donDisableAutoWiperDuration 1;
BA_ "Confidence" SG_ 1021 UI_donDisableOnAutoWiperSpeed 1;
BA_ "Confidence" SG_ 1021 UI_blindspotMinSpeed 1;
BA_ "Confidence" SG_ 1021 UI_blindspotDistance 1;
BA_ "Confidence" SG_ 1021 UI_blindspotTTC 1;
BA_ "Confidence" SG_ 1021 UI_donStopEndOfRampBuffer 1;
BA_ "Confidence" SG_ 1021 UI_donDisableCutin 1;
BA_ "Confidence" SG_ 1021 UI_smartSetSpeedOffset 1;
BA_ "Confidence" SG_ 1021 UI_smartSetSpeedOffsetType 1;
BA_ "Confidence" SG_ 1021 UI_autopilotMonarchBackup 1;
BA_ "Confidence" SG_ 1021 UI_fsdVisualizationEnabled 1;
BA_ "Confidence" SG_ 1021 UI_fsdStopsControlEnabled 1;
BA_ "Confidence" SG_ 1021 UI_fsdContinueOnGreenWithCIPV 1;
BA_ "Confidence" SG_ 1021 UI_smartSetSpeed 1;
BA_ "Confidence" SG_ 1021 UI_automaticSetSpeedOffset 1;
BA_ "Confidence" SG_ 1021 UI_apply2021_1958_ISA 1;
BA_ "Confidence" SG_ 1021 UI_apply2021_646_ELKS 1;
BA_ "Confidence" SG_ 1021 UI_apply2021_1341_DDAW 1;
BA_ "Confidence" SG_ 1021 UI_homelinkNearby 1;
BA_ "Confidence" SG_ 1021 UI_enableFullSelfDriving 1;
BA_ "Confidence" SG_ 1021 UI_hasFullSelfDriving 1;
BA_ "Confidence" SG_ 1021 UI_autosteerActivation 1;
BA_ "Confidence" SG_ 1021 UI_autopilotDrivingProfile 1;
BA_ "Confidence" SG_ 1021 UI_fsdBetaRequest 1;
BA_ "Confidence" SG_ 1021 UI_fullSelfDrivingSuspended 1;
BA_ "Confidence" SG_ 1021 UI_disableOptionalLaneChanges 1;
BA_ "Confidence" SG_ 1021 UI_applyR152_AEBS 1;
BA_ "Confidence" SG_ 1021 UI_autopilotControlMux0Valid 1;
BA_ "Confidence" SG_ 1021 UI_selectableCameraRequest 1;
BA_ "GenSigSNA" SG_ 1021 UI_selectableCameraRequest "15";
BA_ "Confidence" SG_ 1021 UI_overrideSleepWithSuspend 1;
BA_ "Confidence" SG_ 1021 UI_driverMonitorConfirmation 1;
BA_ "Confidence" SG_ 1021 UI_parkAssistUseVision 1;
BA_ "Confidence" SG_ 1021 UI_applyEceR79 1;
BA_ "Confidence" SG_ 1021 UI_enableMapStops 1;
BA_ "Confidence" SG_ 1021 UI_disableMain 1;
BA_ "Confidence" SG_ 1021 UI_disableNarrow 1;
BA_ "Confidence" SG_ 1021 UI_disableFisheye 1;
BA_ "Confidence" SG_ 1021 UI_disableLeftPillar 1;
BA_ "Confidence" SG_ 1021 UI_disableRightPillar 1;
BA_ "Confidence" SG_ 1021 UI_disableLeftRepeater 1;
BA_ "Confidence" SG_ 1021 UI_disableRightRepeater 1;
BA_ "Confidence" SG_ 1021 UI_disableBackup 1;
BA_ "Confidence" SG_ 1021 UI_disableRadar 1;
BA_ "Confidence" SG_ 1021 UI_noStalkConfirmAlertHaptic 1;
BA_ "Confidence" SG_ 1021 UI_regulatoryLKA 1;
BA_ "Confidence" SG_ 1021 UI_regulatoryLaneAssistLevel 1;
BA_ "Confidence" SG_ 1021 UI_ulcSnooze 1;
BA_ "Confidence" SG_ 1021 UI_noStalkConfirmAlertChime 1;
BA_ "Confidence" SG_ 1021 UI_factorySummonEnable 1;
BA_ "Confidence" SG_ 1021 UI_apmv3Branch 1;
BA_ "Confidence" SG_ 1021 UI_enableCabinCamera 1;
BA_ "Confidence" SG_ 1021 UI_enableAutopilotStopWarning 1;
BA_ "Confidence" SG_ 1021 UI_showLaneGraph 1;
BA_ "Confidence" SG_ 1021 UI_showTrackLabels 1;
BA_ "Confidence" SG_ 1021 UI_hardCoreSummon 1;
BA_ "Confidence" SG_ 1021 UI_enableCabinCameraTelemetry 1;
BA_ "Confidence" SG_ 1021 UI_enableVisionSpeedControl 1;
BA_ "Confidence" SG_ 1021 UI_autopilotTelemetryInChina 1;
BA_ "Confidence" SG_ 1021 UI_enableTeslaAutopark 1;
BA_ "Confidence" SG_ 1021 UI_autoTurnSignalMode 1;
BA_ "Confidence" SG_ 1021 UI_enableCautionLightControl 1;
BA_ "Confidence" SG_ 1021 UI_applyEceR79SmartSummonOnly 1;
BA_ "Confidence" SG_ 1021 UI_autopilotMonarchEnabled 1;
BA_ "Confidence" SG_ 1021 UI_autopilotEphemerisEnabled 1;
BA_ "Confidence" SG_ 1021 UI_enableCabinAudioRecording 1;
BA_ "Confidence" SG_ 1021 UI_autopilotControlMux1Valid 1;
BA_ "Confidence" SG_ 1021 UI_enableApproachingEmergencyVeh 1;
BA_ "SystemSignalLongSymbol" SG_ 1021 UI_enableApproachingEmergencyVeh "UI_enableApproachingEmergencyVehicleDetection";
BA_ "Confidence" SG_ 1021 UI_enableStartFsdFromParkBrakeCo 1;
BA_ "SystemSignalLongSymbol" SG_ 1021 UI_enableStartFsdFromParkBrakeCo "UI_enableStartFsdFromParkBrakeConfirmation";
BA_ "Confidence" SG_ 1021 UI_enableStartFsdFromPark 1;
BA_ "Confidence" SG_ 1021 UI_fsdMaxSpeedOffsetPercentage 1;
BA_ "Confidence" SG_ 1021 UI_coldStartMonarchInFactory 1;
BA_ "Confidence" SG_ 1021 UI_autopilotControlMux2Valid 1;
BA_ "Confidence" SG_ 819 UI_openChargePortDoorRequest 1;
BA_ "Confidence" SG_ 819 UI_closeChargePortDoorRequest 1;
BA_ "Confidence" SG_ 819 UI_chargeEnableRequest 1;
BA_ "Confidence" SG_ 819 UI_brickVLoggingRequest 1;
BA_ "Confidence" SG_ 819 UI_brickBalancingDisabled 1;
BA_ "Confidence" SG_ 819 UI_dSocAlertThreshold 1;
BA_ "Confidence" SG_ 819 UI_acChargeCurrentLimit 1;
BA_ "GenSigSNA" SG_ 819 UI_acChargeCurrentLimit "127";
BA_ "Confidence" SG_ 819 UI_dSocAlertEnable 1;
BA_ "Confidence" SG_ 819 UI_chargeTerminationPct 1;
BA_ "Confidence" SG_ 819 UI_chargeFeature1 1;
BA_ "Confidence" SG_ 819 UI_chargeFeature2 1;
BA_ "Confidence" SG_ 819 UI_chargeFeature3 1;
BA_ "Confidence" SG_ 819 UI_scheduledDepartureEnabled 1;
BA_ "Confidence" SG_ 819 UI_chargePortLatchRequest 1;
BA_ "Confidence" SG_ 819 UI_socSnapshotExpirationTime 1;
BA_ "Confidence" SG_ 819 UI_cpInletHeaterRequest 1;
BA_ "Confidence" SG_ 819 UI_chargePowerSampleRequest 1;
BA_ "Confidence" SG_ 819 UI_enableIso15118 1;
BA_ "Confidence" SG_ 531 UI_cruiseSpeedCommand 1;
BA_ "Confidence" SG_ 531 UI_smartSummonRequest 1;
BA_ "Confidence" SG_ 531 UI_cruiseControlCounter 1;
BA_ "Confidence" SG_ 531 UI_cruiseControlChecksum 0;
BA_ "Confidence" SG_ 645 UI_driverProfileRecallIndex 1;
BA_ "GenSigSNA" SG_ 645 UI_driverProfileRecallIndex "0";
BA_ "Confidence" SG_ 645 UI_driverProfileRecallStop 1;
BA_ "Confidence" SG_ 645 UI_frontSeatRecallActive 1;
BA_ "Confidence" SG_ 645 UI_frontSeatTrackPos 1;
BA_ "Confidence" SG_ 645 UI_frontSeatBackPos 1;
BA_ "Confidence" SG_ 645 UI_frontSeatLiftPos 1;
BA_ "Confidence" SG_ 645 UI_frontSeatTiltPos 1;
BA_ "Confidence" SG_ 645 UI_columnAndLumbarRecallActive 1;
BA_ "Confidence" SG_ 645 UI_steeringColumnUpDownPos 1;
BA_ "Confidence" SG_ 645 UI_lumbarAPressureHpa 1;
BA_ "Confidence" SG_ 645 UI_lumbarBPressureHpa 1;
BA_ "Confidence" SG_ 645 UI_steeringColumnInOutPos 1;
BA_ "Confidence" SG_ 645 UI_leftMirrorTiltXPosition 1;
BA_ "Confidence" SG_ 645 UI_leftMirrorTiltYPosition 1;
BA_ "Confidence" SG_ 645 UI_rightMirrorTiltXPosition 1;
BA_ "Confidence" SG_ 645 UI_rightMirrorTiltYPosition 1;
BA_ "Confidence" SG_ 645 UI_mirrorRecallActive 1;
BA_ "Confidence" SG_ 645 UI_customMirrorDipPositionsSet 1;
BA_ "Confidence" SG_ 645 UI_leftMirrorDipXPosition 1;
BA_ "Confidence" SG_ 645 UI_leftMirrorDipYPosition 1;
BA_ "Confidence" SG_ 645 UI_rightMirrorDipXPosition 1;
BA_ "Confidence" SG_ 645 UI_rightMirrorDipYPosition 1;
BA_ "Confidence" SG_ 645 UI_modifyMirrorDipRequest 1;
BA_ "Confidence" SG_ 1279 UI_energyConsumptionInfoIndex 1;
BA_ "Confidence" SG_ 1279 UI_energyLossTotal_epa 1;
BA_ "Confidence" SG_ 1279 UI_energyLossDriving_epa 1;
BA_ "Confidence" SG_ 1279 UI_energyLossClimate_epa 1;
BA_ "Confidence" SG_ 1279 UI_energyLossBattCond_epa 1;
BA_ "Confidence" SG_ 1279 UI_energyLossElevation_epa 1;
BA_ "Confidence" SG_ 1279 UI_energyLossAcc_epa 1;
BA_ "Confidence" SG_ 1279 UI_energyLossTotalSinceCharge_ep 1;
BA_ "SystemSignalLongSymbol" SG_ 1279 UI_energyLossTotalSinceCharge_ep "UI_energyLossTotalSinceCharge_epa";
BA_ "Confidence" SG_ 1279 UI_energyLossDrivingSinceCharge_ 1;
BA_ "SystemSignalLongSymbol" SG_ 1279 UI_energyLossDrivingSinceCharge_ "UI_energyLossDrivingSinceCharge_epa";
BA_ "Confidence" SG_ 1279 UI_energyLossClimateSinceCharge_ 1;
BA_ "SystemSignalLongSymbol" SG_ 1279 UI_energyLossClimateSinceCharge_ "UI_energyLossClimateSinceCharge_epa";
BA_ "Confidence" SG_ 1279 UI_energyLossBattCondSinceCharge 1;
BA_ "SystemSignalLongSymbol" SG_ 1279 UI_energyLossBattCondSinceCharge "UI_energyLossBattCondSinceCharge_epa";
BA_ "Confidence" SG_ 1279 UI_energyLossElevationSinceCharg 1;
BA_ "SystemSignalLongSymbol" SG_ 1279 UI_energyLossElevationSinceCharg "UI_energyLossElevationSinceCharge_epa";
BA_ "Confidence" SG_ 1279 UI_energyLossAccSinceCharge_epa 1;
BA_ "Confidence" SG_ 1279 UI_energyLossTotalSinceTripStart 1;
BA_ "Confidence" SG_ 1279 UI_energyLossDrivingSinceTripSta 1;
BA_ "SystemSignalLongSymbol" SG_ 1279 UI_energyLossDrivingSinceTripSta "UI_energyLossDrivingSinceTripStart";
BA_ "Confidence" SG_ 1279 UI_energyLossClimateSinceTripSta 1;
BA_ "SystemSignalLongSymbol" SG_ 1279 UI_energyLossClimateSinceTripSta "UI_energyLossClimateSinceTripStart";
BA_ "Confidence" SG_ 1279 UI_energyLossBattCondSinceTripSt 1;
BA_ "SystemSignalLongSymbol" SG_ 1279 UI_energyLossBattCondSinceTripSt "UI_energyLossBattCondSinceTripStart";
BA_ "Confidence" SG_ 1279 UI_energyLossElevationSinceTripS 1;
BA_ "SystemSignalLongSymbol" SG_ 1279 UI_energyLossElevationSinceTripS "UI_energyLossElevationSinceTripStart";
BA_ "Confidence" SG_ 1279 UI_energyLossAccSinceTripStart 1;
BA_ "Confidence" SG_ 1279 UI_energyDeltaTotal_epa 1;
BA_ "Confidence" SG_ 1279 UI_energyDeltaDriving_epa 1;
BA_ "Confidence" SG_ 1279 UI_energyDeltaClimate_epa 1;
BA_ "Confidence" SG_ 1279 UI_energyDeltaBattCond_epa 1;
BA_ "Confidence" SG_ 1279 UI_energyDeltaElevation_epa 1;
BA_ "Confidence" SG_ 1279 UI_energyDeltaAcc_epa 1;
BA_ "Confidence" SG_ 1279 UI_uiDeltaOffsetTotal_epa 1;
BA_ "Confidence" SG_ 1279 UI_uiDeltaOffsetDriving_epa 1;
BA_ "Confidence" SG_ 1279 UI_uiDeltaOffsetClimate_epa 1;
BA_ "Confidence" SG_ 1279 UI_uiDeltaOffsetBattCond_epa 1;
BA_ "Confidence" SG_ 1279 UI_uiDeltaOffsetElevation_epa 1;
BA_ "Confidence" SG_ 1279 UI_uiDeltaOffsetAcc_epa 1;
BA_ "Confidence" SG_ 1279 UI_rawToUiEnergyRatio_epa 1;
BA_ "Confidence" SG_ 1279 UI_driveDistance_epa 1;
BA_ "Confidence" SG_ 1279 UI_energyDeltaTotalSinceCharge_e 1;
BA_ "SystemSignalLongSymbol" SG_ 1279 UI_energyDeltaTotalSinceCharge_e "UI_energyDeltaTotalSinceCharge_epa";
BA_ "Confidence" SG_ 1279 UI_energyDeltaDrivingSinceCharge 1;
BA_ "SystemSignalLongSymbol" SG_ 1279 UI_energyDeltaDrivingSinceCharge "UI_energyDeltaDrivingSinceCharge_epa";
BA_ "Confidence" SG_ 1279 UI_energyDeltaClimateSinceCharge 1;
BA_ "SystemSignalLongSymbol" SG_ 1279 UI_energyDeltaClimateSinceCharge "UI_energyDeltaClimateSinceCharge_epa";
BA_ "Confidence" SG_ 1279 UI_energyDeltaBattCondSinceCharg 1;
BA_ "SystemSignalLongSymbol" SG_ 1279 UI_energyDeltaBattCondSinceCharg "UI_energyDeltaBattCondSinceCharge_epa";
BA_ "Confidence" SG_ 1279 UI_energyDeltaElevationSinceChar 1;
BA_ "SystemSignalLongSymbol" SG_ 1279 UI_energyDeltaElevationSinceChar "UI_energyDeltaElevationSinceCharge_epa";
BA_ "Confidence" SG_ 1279 UI_energyDeltaAccSinceCharge_epa 1;
BA_ "Confidence" SG_ 1279 UI_uiDeltaOffsetTotalSinceCharge 1;
BA_ "SystemSignalLongSymbol" SG_ 1279 UI_uiDeltaOffsetTotalSinceCharge "UI_uiDeltaOffsetTotalSinceCharge_epa";
BA_ "Confidence" SG_ 1279 UI_uiDeltaOffsetDrivingSinceChar 1;
BA_ "SystemSignalLongSymbol" SG_ 1279 UI_uiDeltaOffsetDrivingSinceChar "UI_uiDeltaOffsetDrivingSinceCharge_epa";
BA_ "Confidence" SG_ 1279 UI_uiDeltaOffsetClimateSinceChar 1;
BA_ "SystemSignalLongSymbol" SG_ 1279 UI_uiDeltaOffsetClimateSinceChar "UI_uiDeltaOffsetClimateSinceCharge_epa";
BA_ "Confidence" SG_ 1279 UI_uiDeltaOffsetBattCondSinceCha 1;
BA_ "SystemSignalLongSymbol" SG_ 1279 UI_uiDeltaOffsetBattCondSinceCha "UI_uiDeltaOffsetBattCondSinceCharge_epa";
BA_ "Confidence" SG_ 1279 UI_uiDeltaOffsetElevationSinceCh 1;
BA_ "SystemSignalLongSymbol" SG_ 1279 UI_uiDeltaOffsetElevationSinceCh "UI_uiDeltaOffsetElevationSinceCharge_epa";
BA_ "Confidence" SG_ 1279 UI_uiDeltaOffsetAccSinceCharge_e 1;
BA_ "SystemSignalLongSymbol" SG_ 1279 UI_uiDeltaOffsetAccSinceCharge_e "UI_uiDeltaOffsetAccSinceCharge_epa";
BA_ "Confidence" SG_ 1279 UI_rawToUiEnergyRatioSinceCharge 1;
BA_ "SystemSignalLongSymbol" SG_ 1279 UI_rawToUiEnergyRatioSinceCharge "UI_rawToUiEnergyRatioSinceCharge_epa";
BA_ "Confidence" SG_ 1279 UI_driveDistanceSinceCharge_epa 1;
BA_ "Confidence" SG_ 1279 UI_energyDeltaTotalSinceTripStar 1;
BA_ "SystemSignalLongSymbol" SG_ 1279 UI_energyDeltaTotalSinceTripStar "UI_energyDeltaTotalSinceTripStart";
BA_ "Confidence" SG_ 1279 UI_energyDeltaDrivingSinceTripSt 1;
BA_ "SystemSignalLongSymbol" SG_ 1279 UI_energyDeltaDrivingSinceTripSt "UI_energyDeltaDrivingSinceTripStart";
BA_ "Confidence" SG_ 1279 UI_energyDeltaClimateSinceTripSt 1;
BA_ "SystemSignalLongSymbol" SG_ 1279 UI_energyDeltaClimateSinceTripSt "UI_energyDeltaClimateSinceTripStart";
BA_ "Confidence" SG_ 1279 UI_energyDeltaBattCondSinceTripS 1;
BA_ "SystemSignalLongSymbol" SG_ 1279 UI_energyDeltaBattCondSinceTripS "UI_energyDeltaBattCondSinceTripStart";
BA_ "Confidence" SG_ 1279 UI_energyDeltaElevationSinceTrip 1;
BA_ "SystemSignalLongSymbol" SG_ 1279 UI_energyDeltaElevationSinceTrip "UI_energyDeltaElevationSinceTripStart";
BA_ "Confidence" SG_ 1279 UI_energyDeltaAccSinceTripStart 1;
BA_ "Confidence" SG_ 1279 UI_uiDeltaOffsetTotalSinceTripSt 1;
BA_ "SystemSignalLongSymbol" SG_ 1279 UI_uiDeltaOffsetTotalSinceTripSt "UI_uiDeltaOffsetTotalSinceTripStart";
BA_ "Confidence" SG_ 1279 UI_uiDeltaOffsetDrivingSinceTrip 1;
BA_ "SystemSignalLongSymbol" SG_ 1279 UI_uiDeltaOffsetDrivingSinceTrip "UI_uiDeltaOffsetDrivingSinceTripStart";
BA_ "Confidence" SG_ 1279 UI_uiDeltaOffsetClimateSinceTrip 1;
BA_ "SystemSignalLongSymbol" SG_ 1279 UI_uiDeltaOffsetClimateSinceTrip "UI_uiDeltaOffsetClimateSinceTripStart";
BA_ "Confidence" SG_ 1279 UI_uiDeltaOffsetBattCondSinceTri 1;
BA_ "SystemSignalLongSymbol" SG_ 1279 UI_uiDeltaOffsetBattCondSinceTri "UI_uiDeltaOffsetBattCondSinceTripStart";
BA_ "Confidence" SG_ 1279 UI_uiDeltaOffsetElevationSinceTr 1;
BA_ "SystemSignalLongSymbol" SG_ 1279 UI_uiDeltaOffsetElevationSinceTr "UI_uiDeltaOffsetElevationSinceTripStart";
BA_ "Confidence" SG_ 1279 UI_uiDeltaOffsetAccSinceTripStar 1;
BA_ "SystemSignalLongSymbol" SG_ 1279 UI_uiDeltaOffsetAccSinceTripStar "UI_uiDeltaOffsetAccSinceTripStart";
BA_ "Confidence" SG_ 1279 UI_rawToUiEnergyRatioSinceTripSt 1;
BA_ "SystemSignalLongSymbol" SG_ 1279 UI_rawToUiEnergyRatioSinceTripSt "UI_rawToUiEnergyRatioSinceTripStart";
BA_ "Confidence" SG_ 1279 UI_driveDistanceSinceTripStart 1;
BA_ "Confidence" SG_ 1279 UI_trailerMass 1;
BA_ "Confidence" SG_ 1139 UI_nmGoingToSleep 1;
BA_ "Confidence" SG_ 1139 UI_nmKeepAwakeReason 1;
BA_ "GenSigSNA" SG_ 1139 UI_nmKeepAwakeReason "0";
BA_ "Confidence" SG_ 1139 UI_wakeupTime 1;
BA_ "Confidence" SG_ 1267 UI_frontRightSeatTrackForward 1;
BA_ "Confidence" SG_ 1267 UI_frontRightSeatTrackBack 1;
BA_ "Confidence" SG_ 1267 UI_frontLeftSeatTrackForward 1;
BA_ "Confidence" SG_ 1267 UI_frontLeftSeatTrackBack 1;
BA_ "Confidence" SG_ 1267 UI_frontRightSeatBackrestBack 1;
BA_ "Confidence" SG_ 1267 UI_frontRightSeatBackrestForward 1;
BA_ "Confidence" SG_ 1267 UI_frontLeftSeatBackrestBack 1;
BA_ "Confidence" SG_ 1267 UI_frontLeftSeatBackrestForward 1;
BA_ "Confidence" SG_ 955 UI_powerExpected 1;
BA_ "Confidence" SG_ 955 UI_powerIdeal 1;
BA_ "Confidence" SG_ 820 UI_systemPowerLimit 1;
BA_ "GenSigSNA" SG_ 820 UI_systemPowerLimit "31";
BA_ "Confidence" SG_ 820 UI_pedalMap 1;
BA_ "Confidence" SG_ 820 UI_enableRegenBackfill 1;
BA_ "Confidence" SG_ 820 UI_systemTorqueLimit 1;
BA_ "GenSigSNA" SG_ 820 UI_systemTorqueLimit "63";
BA_ "Confidence" SG_ 820 UI_closureConfirmed 1;
BA_ "Confidence" SG_ 820 UI_regenTorqueMax 1;
BA_ "Confidence" SG_ 820 UI_limitMode 1;
BA_ "Confidence" SG_ 820 UI_factoryCustomerDrivingModeReq 1;
BA_ "SystemSignalLongSymbol" SG_ 820 UI_factoryCustomerDrivingModeReq "UI_factoryCustomerDrivingModeRequest";
BA_ "Confidence" SG_ 820 UI_motorOnMode 1;
BA_ "Confidence" SG_ 820 UI_wasteMode 1;
BA_ "Confidence" SG_ 820 UI_wasteModeRegenLimit 1;
BA_ "Confidence" SG_ 820 UI_stoppingMode 1;
BA_ "Confidence" SG_ 820 UI_DIAppSliderDebug 1;
BA_ "Confidence" SG_ 820 UI_speedLimit 1;
BA_ "GenSigSNA" SG_ 820 UI_speedLimit "511";
BA_ "Confidence" SG_ 820 UI_enableSmartShift 1;
BA_ "Confidence" SG_ 820 UI_navVehParallelToRdCanContinue 1;
BA_ "GenSigSNA" SG_ 820 UI_navVehParallelToRdCanContinue "0";
BA_ "Confidence" SG_ 820 UI_powertrainControlCounter 1;
BA_ "Confidence" SG_ 820 UI_powertrainControlChecksum 0;
BA_ "Confidence" SG_ 563 UI_gearRequest 1;
BA_ "GenSigSNA" SG_ 563 UI_gearRequest "0";
BA_ "Confidence" SG_ 563 UI_autopilotRequest 1;
BA_ "Confidence" SG_ 563 UI_fullScreenMode 1;
BA_ "Confidence" SG_ 563 UI_gearStripShowing 1;
BA_ "Confidence" SG_ 563 UI_gearStripLocation 1;
BA_ "Confidence" SG_ 563 UI_gearStripForceShow 1;
BA_ "Confidence" SG_ 563 UI_autoParkAvailable 1;
BA_ "Confidence" SG_ 563 UI_gearStripSuppressActive 1;
BA_ "Confidence" SG_ 563 UI_gearNeutralPressed 1;
BA_ "Confidence" SG_ 699 UI_centerDisplayRunning 1;
BA_ "Confidence" SG_ 699 UI_centerDisplaySM 1;
BA_ "Confidence" SG_ 699 UI_centerDisplayPowerOn 1;
BA_ "Confidence" SG_ 991 UI_mobileAppStepCount 1;
BA_ "Confidence" SG_ 991 UI_userRequestSnapshot 1;
BA_ "Confidence" SG_ 991 UI_touchDetected 1;
BA_ "Confidence" SG_ 991 UI_validDeviceForEUSummon 1;
BA_ "Confidence" SG_ 991 UI_locatedAtHome 1;
BA_ "Confidence" SG_ 991 UI_locatedAtWork 1;
BA_ "Confidence" SG_ 991 UI_locatedAtFavorite 1;
BA_ "Confidence" SG_ 991 UI_displayInDarkMode 1;
BA_ "Confidence" SG_ 991 UI_userActivity 1;
BA_ "Confidence" SG_ 991 UI_activeTouchPoints 1;
BA_ "Confidence" SG_ 991 UI_linkState 1;
BA_ "Confidence" SG_ 991 UI_sentryModeState 1;
BA_ "GenSigSNA" SG_ 991 UI_sentryModeState "6";
BA_ "Confidence" SG_ 991 UI_autopilotSentryRequest 1;
BA_ "Confidence" SG_ 991 UI_mobileAppConnected 1;
BA_ "Confidence" SG_ 991 UI_autoshiftDRState 1;
BA_ "Confidence" SG_ 991 UI_wifiBtModuleType 1;
BA_ "Confidence" SG_ 991 UI_sohHealthStatus 1;
BA_ "Confidence" SG_ 991 UI_selfParkState 1;
BA_ "GenSigSNA" SG_ 991 UI_selfParkState "255";
BA_ "Confidence" SG_ 991 UI_summonDeviceIndex 1;
BA_ "Confidence" SG_ 991 UI_sentryModeCameraDetection 1;
BA_ "Confidence" SG_ 991 UI_wakeOnIPActive 1;
BA_ "Confidence" SG_ 661 UI_systemMonitorIndex 1;
BA_ "Confidence" SG_ 661 UI_SystemMemUsage 1;
BA_ "Confidence" SG_ 661 UI_QtCarMemUsage 1;
BA_ "Confidence" SG_ 661 UI_QtCarCPUUsage 1;
BA_ "Confidence" SG_ 661 UI_SystemCPUUsage 1;
BA_ "Confidence" SG_ 952 UI_setRCPFront 1;
BA_ "Confidence" SG_ 952 UI_setRCPRear 1;
BA_ "Confidence" SG_ 787 UI_trackModeRequest 1;
BA_ "Confidence" SG_ 787 UI_trackRotationTendency 1;
BA_ "Confidence" SG_ 787 UI_trackStabilityAssist 1;
BA_ "Confidence" SG_ 787 UI_trackPostCooling 1;
BA_ "Confidence" SG_ 787 UI_trackCmpOverclock 1;
BA_ "Confidence" SG_ 787 UI_trackModeBrakeTemps 1;
BA_ "Confidence" SG_ 787 UI_trackDrivePowerAvailability 1;
BA_ "Confidence" SG_ 787 UI_trackModeSettingsCounter 1;
BA_ "Confidence" SG_ 787 UI_trackModeSettingsChecksum 0;
BA_ "Confidence" SG_ 130 UI_tripPlanningActive 1;
BA_ "Confidence" SG_ 130 UI_navToSupercharger 1;
BA_ "Confidence" SG_ 130 UI_navFastchargerType 1;
BA_ "Confidence" SG_ 130 UI_battPreconditionOnNavState 1;
BA_ "Confidence" SG_ 130 UI_requestActiveBatteryHeating 1;
BA_ "Confidence" SG_ 130 UI_battPreconditionOnNavPowerReq 1;
BA_ "GenSigSNA" SG_ 130 UI_battPreconditionOnNavPowerReq "127";
BA_ "Confidence" SG_ 130 UI_battPreconditionOnNavTargetT 1;
BA_ "GenSigSNA" SG_ 130 UI_battPreconditionOnNavTargetT "255";
BA_ "Confidence" SG_ 130 UI_ambientTempAtDestination 1;
BA_ "GenSigSNA" SG_ 130 UI_ambientTempAtDestination "128";
BA_ "Confidence" SG_ 130 UI_energyAtDestination 1;
BA_ "GenSigSNA" SG_ 130 UI_energyAtDestination "32768";
BA_ "Confidence" SG_ 139 UI_maxSpeedToReachDestination 1;
BA_ "GenSigSNA" SG_ 139 UI_maxSpeedToReachDestination "65535";
BA_ "Confidence" SG_ 139 UI_remainingWeightedRMSSpeed 1;
BA_ "GenSigSNA" SG_ 139 UI_remainingWeightedRMSSpeed "65535";
BA_ "Confidence" SG_ 139 UI_timeToDestination 1;
BA_ "GenSigSNA" SG_ 139 UI_timeToDestination "65535";
BA_ "Confidence" SG_ 1173 UI_predictedEnergy 1;
BA_ "GenSigSNA" SG_ 1173 UI_predictedEnergy "32768";
BA_ "Confidence" SG_ 1173 UI_predictedEnergyLearned 1;
BA_ "GenSigSNA" SG_ 1173 UI_predictedEnergyLearned "32768";
BA_ "Confidence" SG_ 1173 UI_hindsightEnergy 1;
BA_ "GenSigSNA" SG_ 1173 UI_hindsightEnergy "32768";
BA_ "Confidence" SG_ 1173 UI_hindsightEnergyLearned 1;
BA_ "GenSigSNA" SG_ 1173 UI_hindsightEnergyLearned "32768";
BA_ "Confidence" SG_ 1174 UI_longTermEnergyModelError 1;
BA_ "GenSigSNA" SG_ 1174 UI_longTermEnergyModelError "128";
BA_ "Confidence" SG_ 1174 UI_longTermRmsSpeedRatio 1;
BA_ "GenSigSNA" SG_ 1174 UI_longTermRmsSpeedRatio "255";
BA_ "Confidence" SG_ 1174 UI_gradeCorrectedEnergy 1;
BA_ "GenSigSNA" SG_ 1174 UI_gradeCorrectedEnergy "32768";
BA_ "Confidence" SG_ 1174 UI_gradeCorrectedEnergyLearned 1;
BA_ "GenSigSNA" SG_ 1174 UI_gradeCorrectedEnergyLearned "32768";
BA_ "Confidence" SG_ 1175 UI_battPreconditionOnNavTime 1;
BA_ "GenSigSNA" SG_ 1175 UI_battPreconditionOnNavTime "65535";
BA_ "Confidence" SG_ 1175 UI_maxBattPreconditionOnNavTime 1;
BA_ "GenSigSNA" SG_ 1175 UI_maxBattPreconditionOnNavTime "65535";
BA_ "Confidence" SG_ 1175 UI_tripPlanChargingTargetPercent 1;
BA_ "GenSigSNA" SG_ 1175 UI_tripPlanChargingTargetPercent "1023";
BA_ "Confidence" SG_ 947 UI_gloveboxRequest 1;
BA_ "Confidence" SG_ 947 UI_trunkRequest 1;
BA_ "Confidence" SG_ 947 UI_UMCUpdateInhibit 1;
BA_ "Confidence" SG_ 947 UI_WCUpdateInhibit 1;
BA_ "Confidence" SG_ 947 UI_soundHornOnLock 1;
BA_ "Confidence" SG_ 947 UI_locksPanelActive 1;
BA_ "Confidence" SG_ 947 UI_PINToDriveEnabled 1;
BA_ "Confidence" SG_ 947 UI_PINToDrivePassed 1;
BA_ "Confidence" SG_ 947 UI_disableMirrorAutoDim 1;
BA_ "Confidence" SG_ 947 UI_lightSwitch 1;
BA_ "GenSigSNA" SG_ 947 UI_lightSwitch "4";
BA_ "Confidence" SG_ 947 UI_readyToAddKey 1;
BA_ "Confidence" SG_ 947 UI_alarmTriggerRequest 1;
BA_ "Confidence" SG_ 947 UI_VCSECFeature1 1;
BA_ "Confidence" SG_ 947 UI_VCLEFTFeature1 1;
BA_ "Confidence" SG_ 947 UI_summonState 1;
BA_ "GenSigSNA" SG_ 947 UI_summonState "0";
BA_ "Confidence" SG_ 947 UI_displayOnForUser 1;
BA_ "Confidence" SG_ 947 UI_freeRollModeRequest 1;
BA_ "Confidence" SG_ 947 UI_BLEPushNotificationRequest 1;
BA_ "Confidence" SG_ 947 UI_pairKeyQRCodeDisplaying 1;
BA_ "Confidence" SG_ 947 UI_keepAutopilotAwake 1;
BA_ "Confidence" SG_ 947 UI_batteryPreconditioningRequest 1;
BA_ "Confidence" SG_ 947 UI_coastDownMode 1;
BA_ "Confidence" SG_ 947 UI_autopilotPowerStateRequest 1;
BA_ "Confidence" SG_ 947 UI_shorted12VCellTestMode 1;
BA_ "Confidence" SG_ 947 UI_autoRollWindowsOnLockEnable 1;
BA_ "Confidence" SG_ 947 UI_virtualPitchSensorOverrideOKF 1;
BA_ "SystemSignalLongSymbol" SG_ 947 UI_virtualPitchSensorOverrideOKF "UI_virtualPitchSensorOverrideOKForAim";
BA_ "Confidence" SG_ 947 UI_conditionalLoggingEnabledVCSE 1;
BA_ "SystemSignalLongSymbol" SG_ 947 UI_conditionalLoggingEnabledVCSE "UI_conditionalLoggingEnabledVCSEC";
BA_ "Confidence" SG_ 947 UI_WC3UpdateInhibit 1;
BA_ "Confidence" SG_ 947 UI_steeringWheelHeatReq 1;
BA_ "Confidence" SG_ 947 UI_disableHorn 1;
BA_ "Confidence" SG_ 947 UI_frontLeftSeatFanReq 1;
BA_ "Confidence" SG_ 947 UI_frontRightSeatAutoClimateReq 1;
BA_ "Confidence" SG_ 947 UI_frontRightSeatFanReq 1;
BA_ "Confidence" SG_ 947 UI_sleepFeature1 1;
BA_ "Confidence" SG_ 947 UI_dcr12VThreshold 1;
BA_ "Confidence" SG_ 947 UI_frontLeftSeatAutoClimateReq 1;
BA_ "Confidence" SG_ 947 UI_wiperHeaterReq 1;
BA_ "Confidence" SG_ 947 UI_tireSeason 1;
BA_ "Confidence" SG_ 947 UI_saveTireConfigReq 1;
BA_ "Confidence" SG_ 947 UI_silentAlarm 1;
BA_ "Confidence" SG_ 947 UI_sleepFeature2 1;
BA_ "Confidence" SG_ 628 UI_lightFlashRequest 1;
BA_ "Confidence" SG_ 628 UI_keylessDrivingEnabled 1;
BA_ "Confidence" SG_ 628 UI_phoneCallActive 1;
BA_ "Confidence" SG_ 628 UI_drivingSideVEH 1;
BA_ "Confidence" SG_ 628 UI_keyPairResponse 1;
BA_ "Confidence" SG_ 628 UI_lightShowClosuresEnabled 1;
BA_ "Confidence" SG_ 628 UI_steeringWheelHeatAutoReq 1;
BA_ "Confidence" SG_ 628 UI_steeringWheelHeatLevelReq 1;
BA_ "Confidence" SG_ 628 UI_headlightPulseRequest 1;
BA_ "Confidence" SG_ 628 UI_VCSECFeature2 1;
BA_ "Confidence" SG_ 628 UI_VCSECFeature3 1;
BA_ "Confidence" SG_ 628 UI_VCSECFeature4 1;
BA_ "Confidence" SG_ 628 UI_VCSECFeature5 1;
BA_ "Confidence" SG_ 628 UI_shortHornRequest 1;
BA_ "Confidence" SG_ 628 UI_packTempLoggingRequest 1;
BA_ "Confidence" SG_ 628 UI_UMC3UpdateInhibit 1;
BA_ "Confidence" SG_ 628 UI_handsFreeTrunk 1;
BA_ "Confidence" SG_ 628 UI_displayRedShiftActive 1;
BA_ "Confidence" SG_ 628 UI_handsFreeFrunk 1;
BA_ "Confidence" SG_ 628 UI_fasciaCameraWashRequest 1;
BA_ "Confidence" SG_ 628 UI_autoClosuresExcludeHome 1;
BA_ "Confidence" SG_ 628 UI_leftRearSeatAdjustmentRequest 1;
BA_ "Confidence" SG_ 628 UI_rightRearSeatAdjustmentReques 1;
BA_ "SystemSignalLongSymbol" SG_ 628 UI_rightRearSeatAdjustmentReques "UI_rightRearSeatAdjustmentRequest";
BA_ "Confidence" SG_ 628 UI_blindSpotIndicatorLightReques 1;
BA_ "SystemSignalLongSymbol" SG_ 628 UI_blindSpotIndicatorLightReques "UI_blindSpotIndicatorLightRequest";
BA_ "Confidence" SG_ 628 UI_etcBluetoothControl 1;
BA_ "Confidence" SG_ 628 UI_keepOnAccessoryPortsReq 1;
BA_ "Confidence" SG_ 628 UI_fasciaCameraShown 1;
BA_ "Confidence" SG_ 628 UI_rearSeatChildLock 1;
BA_ "Confidence" SG_ 628 UI_windowPercentageRequest 1;
BA_ "Confidence" SG_ 628 UI_windowRequestedFL 1;
BA_ "Confidence" SG_ 628 UI_windowRequestedFR 1;
BA_ "Confidence" SG_ 628 UI_windowRequestedRL 1;
BA_ "Confidence" SG_ 628 UI_windowRequestedRR 1;
BA_ "Confidence" SG_ 628 UI_windowRequest 1;
BA_ "Confidence" SG_ 628 UI_closeTrunkRequest 1;
BA_ "Confidence" SG_ 628 UI_childPresenceDetectionDisable 1;
BA_ "SystemSignalLongSymbol" SG_ 628 UI_childPresenceDetectionDisable "UI_childPresenceDetectionDisableRequest";
BA_ "Confidence" SG_ 628 UI_derivedLoadshedFeature 1;
BA_ "Confidence" SG_ 628 UI_rearSeatFoldConfirmed 1;
BA_ "Confidence" SG_ 628 UI_leftRearSeatRequestFromRearDi 1;
BA_ "SystemSignalLongSymbol" SG_ 628 UI_leftRearSeatRequestFromRearDi "UI_leftRearSeatRequestFromRearDisplay";
BA_ "Confidence" SG_ 628 UI_selfParkStandingBy 1;
BA_ "Confidence" SG_ 628 UI_rightRearSeatRequestFromRearD 1;
BA_ "SystemSignalLongSymbol" SG_ 628 UI_rightRearSeatRequestFromRearD "UI_rightRearSeatRequestFromRearDisplay";
BA_ "Confidence" SG_ 853 UI_coolantFlowRequest 0;
BA_ "Confidence" SG_ 853 UI_inletActiveCoolTarget 1;
BA_ "Confidence" SG_ 853 UI_disableHVPTThermalLoads 1;
BA_ "Confidence" SG_ 853 UI_enableCompLiquidPumpOut 1;
BA_ "Confidence" SG_ 853 UI_enableCOP1HighSHOperation 1;
BA_ "Confidence" SG_ 853 UI_enableIncreasedEvapRampRate 1;
BA_ "Confidence" SG_ 853 UI_enableCOP1BatteryHeating 1;
BA_ "Confidence" SG_ 853 UI_enableCOP1CabinHeatingBattery 1;
BA_ "SystemSignalLongSymbol" SG_ 853 UI_enableCOP1CabinHeatingBattery "UI_enableCOP1CabinHeatingBatteryHeating";
BA_ "Confidence" SG_ 853 UI_enableLouverAutoDetection 1;
BA_ "Confidence" SG_ 853 UI_enableUserFacingLowFlowDelive 1;
BA_ "SystemSignalLongSymbol" SG_ 853 UI_enableUserFacingLowFlowDelive "UI_enableUserFacingLowFlowDeliveryAlert";
BA_ "Confidence" SG_ 853 UI_disableHvacCameraOnlyDefog 1;
BA_ "Confidence" SG_ 853 UI_enableEXVFastCalibration 1;
BA_ "Confidence" SG_ 853 UI_geofencedLiftgateHeight 1;
BA_ "GenSigSNA" SG_ 853 UI_geofencedLiftgateHeight "255";
BA_ "Confidence" SG_ 853 UI_enableConservativeBatteryHeat 1;
BA_ "SystemSignalLongSymbol" SG_ 853 UI_enableConservativeBatteryHeat "UI_enableConservativeBatteryHeating";
BA_ "Confidence" SG_ 853 UI_enableDefaultApTempTarget 1;
BA_ "Confidence" SG_ 644 UI_factoryMode 1;
BA_ "Confidence" SG_ 644 UI_transportMode 1;
BA_ "Confidence" SG_ 644 UI_showroomMode 1;
BA_ "Confidence" SG_ 644 UI_serviceMode 1;
BA_ "Confidence" SG_ 644 UI_isDelivered 1;
BA_ "Confidence" SG_ 644 UI_hasEverBeenDelivered 1;
BA_ "Confidence" SG_ 644 UI_homelinkV2Command0 1;
BA_ "Confidence" SG_ 644 UI_homelinkV2Command1 1;
BA_ "Confidence" SG_ 644 UI_homelinkV2Command2 1;
BA_ "Confidence" SG_ 644 UI_carWashMode 1;
BA_ "Confidence" SG_ 644 UI_valetMode 1;
BA_ "Confidence" SG_ 644 UI_gameMode 1;
BA_ "Confidence" SG_ 644 UI_diagnosticsAllowed 1;
BA_ "Confidence" SG_ 644 UI_serviceModePlus 1;
BA_ "Confidence" SG_ 644 UI_premiumAmpPowerOff 1;
BA_ "Confidence" SG_ 644 UI_signedCmdHardLocked 1;
BA_ "Confidence" SG_ 644 UI_signedCmdServiceMode 1;
BA_ "Confidence" SG_ 644 UI_closureEasterEggStatus 1;
BA_ "Confidence" SG_ 644 UI_lightShowType 1;
BA_ "Confidence" SG_ 644 UI_sohTestRequest 1;
BA_ "Confidence" SG_ 644 UI_vehicleModesCounter 1;
BA_ "Confidence" SG_ 644 UI_vehicleModesChecksum 0;
BA_ "Confidence" SG_ 595 UI_ventPanelControlRequestIndex 1;
BA_ "Confidence" SG_ 595 UI_ventPanelLeftPositionX 1;
BA_ "Confidence" SG_ 595 UI_ventPanelLeftPositionY 1;
BA_ "Confidence" SG_ 595 UI_ventPanelLeftLateralSplit 1;
BA_ "Confidence" SG_ 595 UI_ventPanelRightPositionX 1;
BA_ "Confidence" SG_ 595 UI_ventPanelRightPositionY 1;
BA_ "Confidence" SG_ 595 UI_ventPanelRightLateralSplit 1;
BA_ "Confidence" SG_ 595 UI_ventPanelLeftLateralMode 1;
BA_ "Confidence" SG_ 595 UI_ventPanelRightLateralMode 1;
BA_ "Confidence" SG_ 595 UI_hvacReqActiveVents 1;
BA_ "Confidence" SG_ 595 UI_vent2RLeftPositionX 1;
BA_ "Confidence" SG_ 595 UI_vent2RLeftPositionY 1;
BA_ "Confidence" SG_ 595 UI_vent2RRightPositionX 1;
BA_ "Confidence" SG_ 595 UI_vent2RRightPositionY 1;
BA_ "Confidence" SG_ 1569 UI_weatherSvcTimeSinceLast 1;
BA_ "GenSigSNA" SG_ 1569 UI_weatherSvcTimeSinceLast "2047";
BA_ "Confidence" SG_ 1569 UI_weatherSvcTemperature 1;
BA_ "GenSigSNA" SG_ 1569 UI_weatherSvcTemperature "127";
BA_ "Confidence" SG_ 1569 UI_weatherSvcHumidity 1;
BA_ "GenSigSNA" SG_ 1569 UI_weatherSvcHumidity "255";
BA_ "Confidence" SG_ 1569 UI_weatherSvcDewPoint 1;
BA_ "GenSigSNA" SG_ 1569 UI_weatherSvcDewPoint "255";
BA_ "Confidence" SG_ 1569 UI_weatherSvcCloudCover 1;
BA_ "GenSigSNA" SG_ 1569 UI_weatherSvcCloudCover "255";
BA_ "Confidence" SG_ 1533 UMC_alertID 1;
BA_ "Confidence" SG_ 1533 UMC_alertType 1;
BA_ "Confidence" SG_ 1533 UMC_a001_groundImpedance 1;
BA_ "Confidence" SG_ 1533 UMC_a002_ccidRmsCurrent 1;
BA_ "Confidence" SG_ 1533 UMC_a002_ccidRmsCurrentAvg 1;
BA_ "Confidence" SG_ 1533 UMC_a002_ccidFaultReason 1;
BA_ "GenSigSNA" SG_ 1533 UMC_a002_ccidFaultReason "0";
BA_ "Confidence" SG_ 1533 UMC_a003_faultType 1;
BA_ "Confidence" SG_ 1533 UMC_a003_ccidSelfTestDuty 1;
BA_ "Confidence" SG_ 1533 UMC_a003_ccidSelfTestCurrent 1;
BA_ "Confidence" SG_ 1533 UMC_a004_lineVoltage 1;
BA_ "Confidence" SG_ 1533 UMC_a004_inputVoltage 1;
BA_ "Confidence" SG_ 1533 UMC_a004_inputNeutralVoltage 1;
BA_ "Confidence" SG_ 1533 UMC_a005_lineVoltage 1;
BA_ "Confidence" SG_ 1533 UMC_a005_inputVoltage 1;
BA_ "Confidence" SG_ 1533 UMC_a005_inputNeutralVoltage 1;
BA_ "Confidence" SG_ 1533 UMC_a006_outputVoltage 1;
BA_ "Confidence" SG_ 1533 UMC_a006_faultType 1;
BA_ "Confidence" SG_ 1533 UMC_a006_umcReceptacleVoltage 1;
BA_ "Confidence" SG_ 1533 UMC_a006_handleVoltage 1;
BA_ "Confidence" SG_ 1533 UMC_a007_pcbaTemp 1;
BA_ "Confidence" SG_ 1533 UMC_a008_wallPlugTemp 1;
BA_ "Confidence" SG_ 1533 UMC_a008_SA_current 1;
BA_ "Confidence" SG_ 1533 UMC_a009_vehConnTemp 1;
BA_ "Confidence" SG_ 1533 UMC_a010_inputTerminalsTemp 1;
BA_ "Confidence" SG_ 1533 UMC_a012_pilotHigh 1;
BA_ "Confidence" SG_ 1533 UMC_a012_pilotLow 1;
BA_ "Confidence" SG_ 1533 UMC_a013_SA_current 1;
BA_ "Confidence" SG_ 1533 UMC_a015_SA_current 1;
BA_ "Confidence" SG_ 1533 UMC_a016_pcbaTemp 1;
BA_ "Confidence" SG_ 1533 UMC_a017_wallPlugTemp 1;
BA_ "Confidence" SG_ 1533 UMC_a017_SA_current 1;
BA_ "Confidence" SG_ 1533 UMC_a018_vehConnTemp 1;
BA_ "Confidence" SG_ 1533 UMC_a019_inputTerminalsTemp 1;
BA_ "Confidence" SG_ 1533 UMC_a024_groundImpedance 1;
BA_ "Confidence" SG_ 1533 UMC_a040_groundImpedance 1;
VAL_ 1657 UI_rgbEnableState 2 "AUTO" 1 "ON" 0 "OFF" ;
VAL_ 1657 UI_rgbEffectType 20 "RAMP_5000MS" 19 "RAMP_4750MS" 18 "RAMP_4500MS" 17 "RAMP_4250MS" 16 "RAMP_4000MS" 15 "RAMP_3750MS" 14 "RAMP_3500MS" 13 "RAMP_3250MS" 12 "RAMP_3000MS" 11 "RAMP_2750MS" 10 "RAMP_2500MS" 9 "RAMP_2250MS" 8 "RAMP_2000MS" 7 "RAMP_1750MS" 6 "RAMP_1500MS" 5 "RAMP_1250MS" 4 "RAMP_1000MS" 3 "RAMP_750MS" 2 "RAMP_500MS" 1 "RAMP_250MS" 0 "RAMP_INSTANT" ;
VAL_ 1657 UI_rgbBrightnessLevel 127 "SNA" ;
VAL_ 1021 UI_autopilotControlIndex 7 "7" 6 "6" 5 "5" 4 "4" 3 "3" 2 "2" 1 "1" 0 "0" ;
VAL_ 1021 UI_hovEnabled 1 "HOV_ON" 0 "HOV_OFF" ;
VAL_ 1021 UI_donDisableAutoWiperDuration 6 "OFF" 5 "120_S" 4 "60_S" 3 "30_S" 2 "15_S" 1 "5_S" 0 "DEFAULT" ;
VAL_ 1021 UI_donDisableOnAutoWiperSpeed 15 "INVALID" 14 "14" 13 "13" 12 "12" 11 "11" 10 "10" 9 "9" 8 "8" 7 "7" 6 "6" 5 "5" 4 "4" 3 "3" 2 "2" 1 "1" 0 "OFF" ;
VAL_ 1021 UI_blindspotMinSpeed 10 "OFF" 9 "45_KPH" 8 "40_KPH" 7 "35_KPH" 6 "30_KPH" 5 "25_KPH" 4 "20_KPH" 3 "15_KPH" 2 "10_KPH" 1 "5_KPH" 0 "DEFAULT" ;
VAL_ 1021 UI_blindspotDistance 5 "OFF" 4 "4_M" 3 "2_M" 2 "1_M" 1 "0P5_M" 0 "DEFAULT" ;
VAL_ 1021 UI_blindspotTTC 7 "OFF" 6 "5_S" 5 "3_S" 4 "4_S" 3 "2_S" 2 "1_S" 1 "0P5_S" 0 "DEFAULT" ;
VAL_ 1021 UI_donStopEndOfRampBuffer 4 "OFF" 3 "45_M" 2 "30_M" 1 "15_M" 0 "DEFAULT" ;
VAL_ 1021 UI_donDisableCutin 1 "ON" 0 "OFF" ;
VAL_ 1021 UI_smartSetSpeedOffsetType 1 "PERCENTAGE_OFFSET" 0 "FIXED_OFFSET" ;
VAL_ 1021 UI_homelinkNearby 1 "NEARBY" 0 "NOT_NEARBY" ;
VAL_ 1021 UI_autosteerActivation 1 "DOUBLE_CLICK" 0 "SINGLE_CLICK" ;
VAL_ 1021 UI_autopilotDrivingProfile 3 "MAD_MAX" 2 "ASSERTIVE" 1 "NORMAL" 0 "CHILL" ;
VAL_ 1021 UI_fsdBetaRequest 1 "FSD_REQUEST_ACTIVE" 0 "FSD_REQUEST_NOT_ACTIVE" ;
VAL_ 1021 UI_selectableCameraRequest 15 "SNA" 13 "REPEATERS_BACKUP" 12 "FASCIA" 11 "GRID_VIEW" 10 "OCTA" 9 "BACKUP" 8 "RIGHT_REPEATER" 7 "RIGHT_PILLAR" 6 "LEFT_REPEATER" 5 "LEFT_PILLAR" 4 "FRONT_NARROW" 3 "FRONT_FISHEYE" 2 "FRONT_MAIN" 1 "SELFIE" 0 "NONE" ;
VAL_ 1021 UI_overrideSleepWithSuspend 1 "ENABLED" 0 "DISABLED" ;
VAL_ 1021 UI_regulatoryLaneAssistLevel 1 "ASSIST" 0 "WARNING" ;
VAL_ 1021 UI_apmv3Branch 5 "DEMO" 4 "EAP" 3 "STAGE2" 2 "DEV" 1 "STAGE" 0 "LIVE" ;
VAL_ 1021 UI_autoTurnSignalMode 1 "UI_AUTO_TURN_SIGNAL_MODE_AUTO_CANCEL" 0 "UI_AUTO_TURN_SIGNAL_MODE_OFF" ;
VAL_ 819 UI_brickVLoggingRequest 1 "TRUE" 0 "FALSE" ;
VAL_ 819 UI_brickBalancingDisabled 1 "TRUE" 0 "FALSE" ;
VAL_ 819 UI_acChargeCurrentLimit 127 "SNA" ;
VAL_ 819 UI_chargePortLatchRequest 2 "UI_LATCH_REQUEST_DISENGAGE" 1 "UI_LATCH_REQUEST_ENGAGE" 0 "UI_LATCH_REQUEST_NONE" ;
VAL_ 819 UI_cpInletHeaterRequest 2 "HEATER_MANUAL_OVERRIDE" 1 "HEATER_AUTO" 0 "HEATER_OFF" ;
VAL_ 531 UI_cruiseSpeedCommand 6 "CRUISE_SPEED_SNAP_SPEEDO" 5 "CRUISE_SPEED_SNAP" 4 "CRUISE_SPEED_DEC_LONG" 3 "CRUISE_SPEED_DEC_SHORT" 2 "CRUISE_SPEED_INC_LONG" 1 "CRUISE_SPEED_INC_SHORT" 0 "CRUISE_SPEED_IDLE" ;
VAL_ 645 UI_driverProfileRecallIndex 5 "5" 4 "4" 3 "3" 2 "2" 1 "1" 0 "SNA" ;
VAL_ 645 UI_modifyMirrorDipRequest 2 "MODIFY_MIRROR_DIP_REQUEST_DIPPED" 1 "MODIFY_MIRROR_DIP_REQUEST_UNDIPPED" 0 "MODIFY_MIRROR_DIP_REQUEST_NONE" ;
VAL_ 1279 UI_energyConsumptionInfoIndex 21 "21" 20 "20" 19 "19" 18 "18" 17 "17" 16 "16" 15 "15" 14 "14" 13 "13" 12 "12" 11 "11" 10 "10" 9 "9" 8 "8" 7 "7" 6 "6" 5 "5" 4 "4" 3 "3" 2 "2" 1 "1" 0 "0" ;
VAL_ 1139 UI_nmKeepAwakeReason 31 "UI_KEEPAWAKE_REASON_AUTO_CONDITIONING_START" 30 "UI_KEEPAWAKE_REASON_WINDOW_CONTROL" 29 "UI_KEEPAWAKE_REASON_GET_VEHICLE_CONFIGURATION" 28 "UI_KEEPAWAKE_REASON_MOTHERSHIP_SMS_OWNER_WAKE_UP" 27 "UI_KEEPAWAKE_REASON_MOTHERSHIP_SMS_GARAGE_WAKE_UP" 26 "UI_KEEPAWAKE_REASON_MOTHERSHIP_SMS_VEHICLE_TASK" 25 "UI_KEEPAWAKE_REASON_MOTHERSHIP_SMS_YOUVE_GOT_MAIL" 24 "UI_KEEPAWAKE_REASON_WAKE_UP" 23 "UI_KEEPAWAKE_REASON_FIRMWARE_HANDSHAKE" 22 "UI_KEEPAWAKE_REASON_VEHICLE_DATA" 21 "UI_KEEPAWAKE_REASON_DIAG_VITALS" 20 "UI_KEEPAWAKE_REASON_URGENT_UPLOAD" 19 "UI_KEEPAWAKE_REASON_UI_REQUEST_AP_KEEPALIVE" 18 "UI_KEEPAWAKE_REASON_STEAM" 17 "UI_KEEPAWAKE_REASON_CHARGING" 16 "UI_KEEPAWAKE_REASON_UI_HVAC_REQUEST" 15 "UI_KEEPAWAKE_REASON_USER_NOTIFICATION_TIMER" 14 "UI_KEEPAWAKE_REASON_ODIN" 13 "UI_KEEPAWAKE_REASON_MEDIA_DOWNLOAD" 12 "UI_KEEPAWAKE_REASON_SENTRY_MODE" 11 "UI_KEEPAWAKE_REASON_SELFTEST" 10 "UI_KEEPAWAKE_REASON_ECALL_ACTIVE" 9 "UI_KEEPAWAKE_REASON_UPDATE_COUNTDOWN" 8 "UI_KEEPAWAKE_REASON_AUTOFUSER" 7 "UI_KEEPAWAKE_REASON_HERMES" 6 "UI_KEEPAWAKE_REASON_UPDATER" 5 "UI_KEEPAWAKE_REASON_MODEM_RESET" 4 "UI_KEEPAWAKE_REASON_UNKNOWN_REMOTE_REQUEST" 3 "UI_KEEPAWAKE_REASON_PM_CHECKING" 2 "UI_KEEPAWAKE_REASON_GUI_NEVER_SLEEP_SET" 1 "UI_KEEPAWAKE_REASON_KEEPALIVEACTIVE" 0 "UI_KEEPAWAKE_REASON_NONE_SNA" ;
VAL_ 820 UI_systemPowerLimit 31 "SNA" ;
VAL_ 820 UI_pedalMap 2 "PERFORMANCE" 1 "SPORT" 0 "CHILL" ;
VAL_ 820 UI_systemTorqueLimit 63 "SNA" ;
VAL_ 820 UI_closureConfirmed 3 "TRUNK" 2 "PROX" 1 "FRUNK" 0 "NONE" ;
VAL_ 820 UI_limitMode 3 "LIMIT_SERVICE" 2 "LIMIT_FACTORY" 1 "LIMIT_VALET" 0 "LIMIT_NORMAL" ;
VAL_ 820 UI_motorOnMode 2 "MOTORONMODE_REAR_ONLY" 1 "MOTORONMODE_FRONT_ONLY" 0 "MOTORONMODE_NORMAL" ;
VAL_ 820 UI_wasteMode 3 "BURN_IN" 2 "FULL" 1 "PARTIAL" 0 "NONE" ;
VAL_ 820 UI_wasteModeRegenLimit 3 "0A" 2 "10A" 1 "30A" 0 "MAX" ;
VAL_ 820 UI_stoppingMode 2 "HOLD" 1 "CREEP" 0 "STANDARD" ;
VAL_ 820 UI_speedLimit 511 "SNA" ;
VAL_ 820 UI_enableSmartShift 2 "ENABLED_P_R_D" 1 "ENABLED_P" 0 "OFF" ;
VAL_ 820 UI_navVehParallelToRdCanContinue 2 "TRUE" 1 "FALSE" 0 "SNA" ;
VAL_ 563 UI_gearRequest 4 "GEAR_REQUEST_DRIVE" 3 "GEAR_REQUEST_NEUTRAL" 2 "GEAR_REQUEST_REVERSE" 1 "GEAR_REQUEST_PARK" 0 "GEAR_REQUEST_IDLE_SNA" ;
VAL_ 563 UI_autopilotRequest 1 "PRESSED" 0 "IDLE" ;
VAL_ 563 UI_gearStripLocation 1 "RIGHT" 0 "LEFT" ;
VAL_ 699 UI_centerDisplaySM 4 "DOWN" 3 "TIMING_OUT" 2 "STALLING" 1 "UP" 0 "START" ;
VAL_ 991 UI_userActivity 1 "USER_ACTIVE" 0 "USER_IDLE" ;
VAL_ 991 UI_linkState 2 "LINK_STATE_WIFI" 1 "LINK_STATE_CELL" 0 "LINK_STATE_NONE" ;
VAL_ 991 UI_sentryModeState 6 "SNA" 5 "QUIET" 4 "PANIC" 3 "AWARE" 2 "ARMED" 1 "IDLE" 0 "OFF" ;
VAL_ 991 UI_mobileAppConnected 1 "CONNECTED" 0 "NOT_CONNECTED" ;
VAL_ 991 UI_autoshiftDRState 6 "AUTOSHIFT_DR_STATE_BRAKE_GEAR_SHIFT_CONFIRMED_D" 5 "AUTOSHIFT_DR_STATE_BRAKE_GEAR_SHIFT_CONFIRMED_R" 4 "AUTOSHIFT_DR_STATE_BRAKE_STEERING_AND_BRAKE_CONFIRMED" 3 "AUTOSHIFT_DR_STATE_ONLY_STEERING_CONFIRMED" 2 "AUTOSHIFT_DR_STATE_ONLY_BRAKE_CONFIRMED" 1 "AUTOSHIFT_DR_STATE_PROMPT_SHOWING_UNCONFIRMED" 0 "AUTOSHIFT_DR_STATE_INACTIVE" ;
VAL_ 991 UI_wifiBtModuleType 4 "ELEKTRA" 3 "TCU4G" 2 "BCM4359" 1 "QCA6595" 0 "UNKNOWN" ;
VAL_ 991 UI_sohHealthStatus 3 "OK" 2 "REDUCED" 1 "NO_INTERNET" 0 "UNKNOWN" ;
VAL_ 991 UI_selfParkState 255 "SNA" 52 "SELF_PARK_USER_PAUSED" 51 "SELF_PARK_REMOTE_PRE_ABORT" 50 "SELF_PARK_RESUME" 49 "SELF_PARK_PAUSE" 48 "SELF_PARK_DV_MISMATCH" 47 "SELF_PARK_DI_PANIC" 46 "SELF_PARK_POST_ACTIVE_FAILURE" 45 "SELF_PARK_POST_ACTIVE_SUCCESS" 44 "SELF_PARK_CANCEL_AUTO_SUMMON" 43 "SELF_PARK_REMOTE_ABORT" 42 "SELF_PARK_OBSTACLE_NOT_CLEARED" 41 "SELF_PARK_OBSTACLE_CLEARED" 40 "SELF_PARK_OPEN_GATE" 39 "SELF_PARK_ACTIVE" 38 "SELF_PARK_STARTED_REVERSE" 37 "SELF_PARK_STARTED_FORWARD" 36 "SELF_PARK_NOT_STARTED_TIMEOUT" 35 "SELF_PARK_PRIMED" 34 "SELF_PARK_PREPRIMED" 33 "SELF_PARK_TURN_ON_DRIVE_RAIL" 32 "SELF_PARK_DETECT_KEY_FOB" 31 "SELF_PARK_WAKE_UP_BUSES" 30 "SELF_PARK_CONNECTING_BLUETOOTH" 29 "SELF_PARK_UNAVAILABLE_CAR_WASH_MODE" 28 "SELF_PARK_UNAVAILABLE_CAR_ALARM" 27 "SELF_PARK_UNAVAILABLE_CRASH_STATE" 26 "SELF_PARK_UNAVAILABLE_DRAG_STRIP_MODE" 25 "SELF_PARK_UNAVAILABLE_TRACK_MODE" 24 "SELF_PARK_UNAVAILABLE_SERVICE_MODE" 23 "SELF_PARK_UNAVAILABLE_DOG_MODE" 22 "SELF_PARK_UNAVAILABLE_GAME_MODE" 21 "SELF_PARK_UNAVAILABLE_BLUETOOTH_CONNECT_TIMEOUT" 20 "SELF_PARK_UNAVAILABLE_WAKEUP_TIMEOUT" 19 "SELF_PARK_UNAVAILABLE_NO_BLUETOOTH_DEVICES_PAIRED" 18 "SELF_PARK_UNAVAILABLE_BRAKE_PRESSED" 17 "SELF_PARK_UNAVAILABLE_ROAD_GRADE" 16 "SELF_PARK_UNAVAILABLE_TRAILER_MODE" 15 "SELF_PARK_UNAVAILABLE_KEY_FOB_BATTERY_LOW" 14 "SELF_PARK_UNAVAILABLE_KEY_FOB_NOT_DETECTED" 13 "SELF_PARK_UNAVAILABLE_PARK_SENSOR_ISSUE" 12 "SELF_PARK_UNAVAILABLE_AUTOSTEER_NOT_ENABLED" 11 "SELF_PARK_UNAVAILABLE_LV_BUS_SUPPORT_ISSUE" 10 "SELF_PARK_UNAVAILABLE_ON_PUBLIC_ROAD" 9 "SELF_PARK_UNAVAILABLE_PARKED_TOO_LONG" 8 "SELF_PARK_UNAVAILABLE_DOOR_OPEN" 7 "SELF_PARK_UNAVAILABLE_TRUNK_OPEN" 6 "SELF_PARK_UNAVAILABLE_FRUNK_OPEN" 5 "SELF_PARK_UNAVAILABLE_PLUGGED_IN" 4 "SELF_PARK_UNAVAILABLE_NOT_PARKED" 3 "SELF_PARK_UNAVAILABLE" 2 "SELF_PARK_IDLE" 1 "SELF_PARK_DRIVING" 0 "SELF_PARK_DISABLED" ;
VAL_ 991 UI_summonDeviceIndex 3 "UNKNOWN" 2 "DEVICE_2" 1 "DEVICE_1" 0 "DEVICE_0" ;
VAL_ 661 UI_systemMonitorIndex 1 "1" 0 "0" ;
VAL_ 787 UI_trackModeRequest 2 "TRACK_MODE_REQUEST_OFF" 1 "TRACK_MODE_REQUEST_ON" 0 "TRACK_MODE_REQUEST_IDLE" ;
VAL_ 787 UI_trackPostCooling 1 "ON" 0 "OFF" ;
VAL_ 787 UI_trackCmpOverclock 1 "ON" 0 "OFF" ;
VAL_ 787 UI_trackModeBrakeTemps 1 "ON" 0 "OFF" ;
VAL_ 787 UI_trackDrivePowerAvailability 2 "TRACK_MODE_POWER_MAX" 1 "TRACK_MODE_POWER_MIDDLE" 0 "TRACK_MODE_POWER_ENDURANCE" ;
VAL_ 130 UI_navFastchargerType 4 "V4" 3 "V3" 2 "V2" 1 "LOW_POWER" 0 "NONE" ;
VAL_ 130 UI_battPreconditionOnNavState 3 "ACTIVE_COOL" 2 "PASSIVE_COOL" 1 "ACTIVE_HEAT" 0 "PASSIVE_HEAT" ;
VAL_ 130 UI_battPreconditionOnNavPowerReq 127 "SNA" 126 "MAX" -126 "MIN" ;
VAL_ 130 UI_battPreconditionOnNavTargetT 255 "SNA" 254 "MAX" 0 "MIN" ;
VAL_ 130 UI_ambientTempAtDestination -128 "SNA" ;
VAL_ 130 UI_energyAtDestination -32767 "TRIP_TOO_LONG" -32768 "SNA" ;
VAL_ 139 UI_maxSpeedToReachDestination 65535 "SNA" 65534 "UNREACHABLE" 65533 "MAXVAL" ;
VAL_ 139 UI_remainingWeightedRMSSpeed 65535 "SNA" 65534 "MAXVAL" ;
VAL_ 139 UI_timeToDestination 65535 "SNA" 65534 "MAXVAL" ;
VAL_ 1173 UI_predictedEnergy -32767 "TRIP_TOO_LONG" -32768 "SNA" ;
VAL_ 1173 UI_predictedEnergyLearned -32767 "TRIP_TOO_LONG" -32768 "SNA" ;
VAL_ 1173 UI_hindsightEnergy -32767 "TRIP_TOO_LONG" -32768 "SNA" ;
VAL_ 1173 UI_hindsightEnergyLearned -32767 "TRIP_TOO_LONG" -32768 "SNA" ;
VAL_ 1174 UI_longTermEnergyModelError 127 "MAXVAL" -128 "SNA" ;
VAL_ 1174 UI_longTermRmsSpeedRatio 255 "SNA" 254 "MAXVAL" ;
VAL_ 1174 UI_gradeCorrectedEnergy -32767 "TRIP_TOO_LONG" -32768 "SNA" ;
VAL_ 1174 UI_gradeCorrectedEnergyLearned -32767 "TRIP_TOO_LONG" -32768 "SNA" ;
VAL_ 1175 UI_battPreconditionOnNavTime 65535 "SNA" 65534 "MAXVAL" ;
VAL_ 1175 UI_maxBattPreconditionOnNavTime 65535 "SNA" 65534 "MAXVAL" ;
VAL_ 1175 UI_tripPlanChargingTargetPercent 1023 "SNA" ;
VAL_ 947 UI_lightSwitch 4 "LIGHT_SWITCH_SNA" 3 "LIGHT_SWITCH_OFF" 2 "LIGHT_SWITCH_PARKING" 1 "LIGHT_SWITCH_ON" 0 "LIGHT_SWITCH_AUTO" ;
VAL_ 947 UI_summonState 3 "ACTIVE" 2 "PRE_PRIMED" 1 "IDLE" 0 "SNA" ;
VAL_ 947 UI_autopilotPowerStateRequest 2 "AUTOPILOT_SUSPEND" 1 "AUTOPILOT_SENTRY" 0 "AUTOPILOT_NOMINAL" ;
VAL_ 947 UI_shorted12VCellTestMode 2 "ACTIVE" 1 "SHADOW" 0 "DISABLED" ;
VAL_ 947 UI_frontLeftSeatFanReq 3 "FAN_REQUEST_LEVEL3" 2 "FAN_REQUEST_LEVEL2" 1 "FAN_REQUEST_LEVEL1" 0 "FAN_REQUEST_OFF" ;
VAL_ 947 UI_frontRightSeatFanReq 3 "FAN_REQUEST_LEVEL3" 2 "FAN_REQUEST_LEVEL2" 1 "FAN_REQUEST_LEVEL1" 0 "FAN_REQUEST_OFF" ;
VAL_ 947 UI_dcr12VThreshold 12 "15_MILLIOHMS" 11 "16_MILLIOHMS" 10 "17_MILLIOHMS" 9 "18_MILLIOHMS" 8 "19_MILLIOHMS" 7 "20_MILLIOHMS" 6 "22_MILLIOHMS" 5 "24_MILLIOHMS" 4 "27_MILLIOHMS" 3 "30_MILLIOHMS" 2 "35_MILLIOHMS" 1 "40_MILLIOHMS" 0 "OFF" ;
VAL_ 947 UI_tireSeason 1 "WINTER" 0 "NON_WINTER" ;
VAL_ 947 UI_saveTireConfigReq 1 "TRUE" 0 "FALSE" ;
VAL_ 628 UI_lightFlashRequest 3 "LIGHT_FLASH_SENTRY" 2 "LIGHT_FLASH_MOBILE_APP" 1 "LIGHT_FLASH_HOMELINK" 0 "LIGHT_FLASH_INACTIVE" ;
VAL_ 628 UI_drivingSideVEH 2 "UNKNOWN" 1 "RIGHT" 0 "LEFT" ;
VAL_ 628 UI_keyPairResponse 2 "DENIED" 1 "CONFIRMED" 0 "NONE" ;
VAL_ 628 UI_steeringWheelHeatLevelReq 3 "STEERING_WHEEL_HEAT_LEVEL3" 2 "STEERING_WHEEL_HEAT_LEVEL2" 1 "STEERING_WHEEL_HEAT_LEVEL1" 0 "STEERING_WHEEL_HEAT_OFF" ;
VAL_ 628 UI_packTempLoggingRequest 1 "TRUE" 0 "FALSE" ;
VAL_ 628 UI_leftRearSeatAdjustmentRequest 6 "UI_ADJUSTABLE_FOLD_FLAT_REQUEST_STOP" 5 "UI_ADJUSTABLE_FOLD_FLAT_REQUEST_TOGGLE_FOLD" 4 "UI_ADJUSTABLE_FOLD_FLAT_REQUEST_REARWARD_FAST" 3 "UI_ADJUSTABLE_FOLD_FLAT_REQUEST_REARWARD_COMFORT" 2 "UI_ADJUSTABLE_FOLD_FLAT_REQUEST_FORWARD_FAST" 1 "UI_ADJUSTABLE_FOLD_FLAT_REQUEST_FORWARD_COMFORT" 0 "UI_ADJUSTABLE_FOLD_FLAT_REQUEST_NONE" ;
VAL_ 628 UI_rightRearSeatAdjustmentReques 6 "UI_ADJUSTABLE_FOLD_FLAT_REQUEST_STOP" 5 "UI_ADJUSTABLE_FOLD_FLAT_REQUEST_TOGGLE_FOLD" 4 "UI_ADJUSTABLE_FOLD_FLAT_REQUEST_REARWARD_FAST" 3 "UI_ADJUSTABLE_FOLD_FLAT_REQUEST_REARWARD_COMFORT" 2 "UI_ADJUSTABLE_FOLD_FLAT_REQUEST_FORWARD_FAST" 1 "UI_ADJUSTABLE_FOLD_FLAT_REQUEST_FORWARD_COMFORT" 0 "UI_ADJUSTABLE_FOLD_FLAT_REQUEST_NONE" ;
VAL_ 628 UI_etcBluetoothControl 3 "RESERVED" 2 "ON" 1 "OFF" 0 "INACTIVE" ;
VAL_ 628 UI_rearSeatChildLock 3 "UI_ADJUSTABLE_FOLD_FLAT_CHILD_LOCK_BOTH" 2 "UI_ADJUSTABLE_FOLD_FLAT_CHILD_LOCK_RIGHT" 1 "UI_ADJUSTABLE_FOLD_FLAT_CHILD_LOCK_LEFT" 0 "UI_ADJUSTABLE_FOLD_FLAT_CHILD_LOCK_NONE" ;
VAL_ 628 UI_windowRequest 6 "WINDOW_REQUEST_GOTO_RELATIVE_PERCENT" 5 "WINDOW_REQUEST_GOTO_CLOSED_CARWASH" 4 "WINDOW_REQUEST_GOTO_OPEN" 3 "WINDOW_REQUEST_GOTO_CLOSED" 2 "WINDOW_REQUEST_GOTO_VENT" 1 "WINDOW_REQUEST_GOTO_PERCENT" 0 "WINDOW_REQUEST_IDLE" ;
VAL_ 853 UI_geofencedLiftgateHeight 255 "INVALID_SNA" 1 "USE_DEFAULT" 0 "PENDING_SAVE" ;
VAL_ 644 UI_factoryMode 1 "ENABLED" 0 "DISABLED" ;
VAL_ 644 UI_transportMode 1 "TRANSPORT_MODE_ENABLED" 0 "TRANSPORT_MODE_DISABLED" ;
VAL_ 644 UI_showroomMode 1 "SHOWROOM_MODE_ENABLED" 0 "SHOWROOM_MODE_DISABLED" ;
VAL_ 644 UI_serviceMode 1 "SERVICE_MODE_ENABLED" 0 "SERVICE_MODE_DISABLED" ;
VAL_ 644 UI_diagnosticsAllowed 1 "ALLOWED" 0 "NOT_ALLOWED" ;
VAL_ 644 UI_serviceModePlus 1 "SERVICE_MODE_PLUS_ENABLED" 0 "SERVICE_MODE_PLUS_DISABLED" ;
VAL_ 644 UI_signedCmdHardLocked 1 "ENABLED" 0 "DISABLED" ;
VAL_ 644 UI_signedCmdServiceMode 1 "ENABLED" 0 "DISABLED" ;
VAL_ 644 UI_closureEasterEggStatus 3 "PLAYING" 2 "PRIMED" 1 "PRIMED_REMOTE" 0 "IDLE" ;
VAL_ 644 UI_lightShowType 5 "LIGHT_SHOW_TYPE_STANDARD_CNY24" 4 "LIGHT_SHOW_TYPE_STANDARD_THE_ARRIVAL" 3 "LIGHT_SHOW_TYPE_STANDARD_CNY23" 2 "LIGHT_SHOW_TYPE_STANDARD_AULD_LANG_SYNE" 1 "LIGHT_SHOW_TYPE_STANDARD_CAROL_OF_THE_BELLS" 0 "LIGHT_SHOW_TYPE_CUSTOM_USB" ;
VAL_ 595 UI_ventPanelControlRequestIndex 1 "1" 0 "0" ;
VAL_ 595 UI_ventPanelLeftLateralMode 2 "SWING" 1 "SPLIT" 0 "SINGLE" ;
VAL_ 595 UI_ventPanelRightLateralMode 2 "SWING" 1 "SPLIT" 0 "SINGLE" ;
VAL_ 595 UI_hvacReqActiveVents 3 "OFF" 2 "RIGHT" 1 "LEFT" 0 "BOTH" ;
VAL_ 1569 UI_weatherSvcTimeSinceLast 2047 "SNA" ;
VAL_ 1569 UI_weatherSvcTemperature 127 "SNA" 120 "MAX" -120 "MIN" ;
VAL_ 1569 UI_weatherSvcHumidity 255 "SNA" ;
VAL_ 1569 UI_weatherSvcDewPoint 255 "SNA" ;
VAL_ 1569 UI_weatherSvcCloudCover 255 "SNA" ;
VAL_ 1533 UMC_alertID 40 "a040_gndDisconnected" 39 "a039_inputOverCurrent" 38 "a038_chcVitalsFault" 37 "a037_GFCICalibration" 35 "a035_v2lHVACDetected" 34 "a034_v2lSAUnsupported" 33 "a033_chcUpdateFault" 32 "a032_chcVitalsRequestFailure" 31 "a031_relayCoilVIrrational" 30 "a030_acLostPllLock" 29 "a029_acPowerLoss" 28 "a028_processorBooted" 27 "a027_watchdogExpired" 26 "a026_vRefOutOfRange" 25 "a025_cntrOpenExpectedClose" 24 "a024_gndResistanceHigh" 23 "a023_adcSelfTest" 22 "a022_criticalRAM" 21 "a021_dataBus" 20 "a020_applicationCRC" 19 "a019_inputOTFoldback" 18 "a018_vehConnOTFoldback" 17 "a017_wallPlugOTFoldback" 16 "a016_pcbaOTFoldback" 15 "a015_SA_Connection" 14 "a014_SA_Genealogy" 13 "a013_SA_Temperature" 12 "a012_pilotFault" 11 "a011_proxDisconnected" 10 "a010_inputOT" 9 "a009_vehConnOT" 8 "a008_wallPlugOT" 7 "a007_pcbaOT" 6 "a006_contactorWelded" 5 "a005_inputUnderVoltage" 4 "a004_inputOverVoltage" 3 "a003_GFCISelfTestFault" 2 "a002_GFCITripped" 1 "a001_gndMonIntrptLineSide" 0 "ALERT_DO_NOT_USE_ZERO" ;
VAL_ 1533 UMC_alertType 1 "SET" 0 "CLEARED" ;
VAL_ 1533 UMC_a002_ccidFaultReason 4 "DC_PEAK" 3 "DC_LPF" 2 "AC_PEAK" 1 "AC_LPF" 0 "SNA" ;
VAL_ 1533 UMC_a003_faultType 1 "SELFTEST" 0 "POWERON" ;
VAL_ 1533 UMC_a006_faultType 1 "OPENED" 0 "WELDED" ;
VAL_ 1533 UMC_a018_vehConnTemp 215 "SHORTED" 214 "OPENED" ;
VAL_ 1533 UMC_a019_inputTerminalsTemp 215 "SHORTED" 214 "OPENED" ;
